VERSION ""

NS_ :

BS_:

BU_: ETH

BO_ 861 IBST_alertMatrix: 8 Vector__XXX
 SG_ IBST_matrixIndex M : 0|4@1+ (1,0) [0|0] "" Vector__XXX
 SG_ IBST_a001_microSupplyError m0 : 4|1@1+ (1,0) [0|0] "" Vector__XXX
 SG_ IBST_a061_AswSystemTimeOut m1 : 4|1@1+ (1,0) [0|0] "" Vector__XXX
 SG_ IBST_a121_RPSVectorRangeLow m2 : 4|1@1+ (1,0) [0|0] "" Vector__XXX
 SG_ IBST_a181_DIchassisControlDLC m3 : 4|1@1+ (1,0) [0|0] "" Vector__XXX
 SG_ IBST_a002_HWBISTError m0 : 5|1@1+ (1,0) [0|0] "" Vector__XXX
 SG_ IBST_a062_MICB6TransferError m1 : 5|1@1+ (1,0) [0|0] "" Vector__XXX
 SG_ IBST_a122_RPSVectorOscillating m2 : 5|1@1+ (1,0) [0|0] "" Vector__XXX
 SG_ IBST_a182_DIchassisControlTimeout m3 : 5|1@1+ (1,0) [0|0] "" Vector__XXX
 SG_ IBST_a003_RAMFault m0 : 6|1@1+ (1,0) [0|0] "" Vector__XXX
 SG_ IBST_a063_tempSens2ShortToSupply m1 : 6|1@1+ (1,0) [0|0] "" Vector__XXX
 SG_ IBST_a123_bridgeDriverUnavail m2 : 6|1@1+ (1,0) [0|0] "" Vector__XXX
 SG_ IBST_a183_DIchassisControlChecksum m3 : 6|1@1+ (1,0) [0|0] "" Vector__XXX
 SG_ IBST_a004_flashFault m0 : 7|1@1+ (1,0) [0|0] "" Vector__XXX
 SG_ IBST_a064_tempSens1ShortToGround m1 : 7|1@1+ (1,0) [0|0] "" Vector__XXX
 SG_ IBST_a124_OBDCurrent1OORHigh m2 : 7|1@1+ (1,0) [0|0] "" Vector__XXX
 SG_ IBST_a184_DIchassisControlCounter m3 : 7|1@1+ (1,0) [0|0] "" Vector__XXX
 SG_ IBST_a005_microSafetyFault m0 : 8|1@1+ (1,0) [0|0] "" Vector__XXX
 SG_ IBST_a065_tempSens2ShortToGround m1 : 8|1@1+ (1,0) [0|0] "" Vector__XXX
 SG_ IBST_a125_OBDCurrent2OORHigh m2 : 8|1@1+ (1,0) [0|0] "" Vector__XXX
 SG_ IBST_a185_rightBusOff m3 : 8|1@1+ (1,0) [0|0] "" Vector__XXX
 SG_ IBST_a006_microSafetyLogicFault m0 : 9|1@1+ (1,0) [0|0] "" Vector__XXX
 SG_ IBST_a066_tempSens1ShortToSupply m1 : 9|1@1+ (1,0) [0|0] "" Vector__XXX
 SG_ IBST_a126_OBDCurrent1OORLow m2 : 9|1@1+ (1,0) [0|0] "" Vector__XXX
 SG_ IBST_a186_rightBusPassive m3 : 9|1@1+ (1,0) [0|0] "" Vector__XXX
 SG_ IBST_a007_RBCPUException m0 : 10|1@1+ (1,0) [0|0] "" Vector__XXX
 SG_ IBST_a067_tempSensImplausVoltage m1 : 10|1@1+ (1,0) [0|0] "" Vector__XXX
 SG_ IBST_a127_OBDCurrent2OORLow m2 : 10|1@1+ (1,0) [0|0] "" Vector__XXX
 SG_ IBST_a187_brakeBusOff m3 : 10|1@1+ (1,0) [0|0] "" Vector__XXX
 SG_ IBST_a008_stackOverUnderFlow m0 : 11|1@1+ (1,0) [0|0] "" Vector__XXX
 SG_ IBST_a068_chargePumpUndervoltage m1 : 11|1@1+ (1,0) [0|0] "" Vector__XXX
 SG_ IBST_a128_BLMMuxerTimeoutError m2 : 11|1@1+ (1,0) [0|0] "" Vector__XXX
 SG_ IBST_a188_brakeBusPassive m3 : 11|1@1+ (1,0) [0|0] "" Vector__XXX
 SG_ IBST_a009_systemErrorHook m0 : 12|1@1+ (1,0) [0|0] "" Vector__XXX
 SG_ IBST_a069_greasingRoutineFault m1 : 12|1@1+ (1,0) [0|0] "" Vector__XXX
 SG_ IBST_a129_loadDumpOnFSLTest m2 : 12|1@1+ (1,0) [0|0] "" Vector__XXX
 SG_ IBST_a189_rightVCLVPowerStateTimeout m3 : 12|1@1+ (1,0) [0|0] "" Vector__XXX
 SG_ IBST_a010_OSErrorHook m0 : 13|1@1+ (1,0) [0|0] "" Vector__XXX
 SG_ IBST_a070_notShutDownNvMWrite m1 : 13|1@1+ (1,0) [0|0] "" Vector__XXX
 SG_ IBST_a130_DTSFunctionalRangeLow m2 : 13|1@1+ (1,0) [0|0] "" Vector__XXX
 SG_ IBST_a190_rightVCLVPowerStateDLC m3 : 13|1@1+ (1,0) [0|0] "" Vector__XXX
 SG_ IBST_a011_systemTaskOverRun m0 : 14|1@1+ (1,0) [0|0] "" Vector__XXX
 SG_ IBST_a071_notShutDownNvMRead m1 : 14|1@1+ (1,0) [0|0] "" Vector__XXX
 SG_ IBST_a131_DTSFunctionalRangeHigh m2 : 14|1@1+ (1,0) [0|0] "" Vector__XXX
 SG_ IBST_a191_rightVCLVPowerStateChecksum m3 : 14|1@1+ (1,0) [0|0] "" Vector__XXX
 SG_ IBST_a012_OSTaskSchemeError m0 : 15|1@1+ (1,0) [0|0] "" Vector__XXX
 SG_ IBST_a072_notShutDownRight m1 : 15|1@1+ (1,0) [0|0] "" Vector__XXX
 SG_ IBST_a132_DTSPlausiCheck1vs2 m2 : 15|1@1+ (1,0) [0|0] "" Vector__XXX
 SG_ IBST_a192_rightVCLVPowerStateCounter m3 : 15|1@1+ (1,0) [0|0] "" Vector__XXX
 SG_ IBST_a013_systemTaskJitter m0 : 16|1@1+ (1,0) [0|0] "" Vector__XXX
 SG_ IBST_a073_jumpInAdjustNvMRead m1 : 16|1@1+ (1,0) [0|0] "" Vector__XXX
 SG_ IBST_a133_DTSOffsetTooLow m2 : 16|1@1+ (1,0) [0|0] "" Vector__XXX
 SG_ IBST_a193_leftVCLVPowerStateTimeout m3 : 16|1@1+ (1,0) [0|0] "" Vector__XXX
 SG_ IBST_a014_DMATransferError m0 : 17|1@1+ (1,0) [0|0] "" Vector__XXX
 SG_ IBST_a074_FindIdleDataNvMWrite m1 : 17|1@1+ (1,0) [0|0] "" Vector__XXX
 SG_ IBST_a134_DTSOffsetTooHigh m2 : 17|1@1+ (1,0) [0|0] "" Vector__XXX
 SG_ IBST_a194_leftVCLVPowerStateChecksum m3 : 17|1@1+ (1,0) [0|0] "" Vector__XXX
 SG_ IBST_a015_asicOscillatorError m0 : 18|1@1+ (1,0) [0|0] "" Vector__XXX
 SG_ IBST_a075_FindIdleRoutineFault m1 : 18|1@1+ (1,0) [0|0] "" Vector__XXX
 SG_ IBST_a135_ESPparty1DLC m2 : 18|1@1+ (1,0) [0|0] "" Vector__XXX
 SG_ IBST_a195_leftVCLVPowerStateDLC m3 : 18|1@1+ (1,0) [0|0] "" Vector__XXX
 SG_ IBST_a016_RBBLMShaftShiftError m0 : 19|1@1+ (1,0) [0|0] "" Vector__XXX
 SG_ IBST_a076_masterCylLengthRead m1 : 19|1@1+ (1,0) [0|0] "" Vector__XXX
 SG_ IBST_a136_ESPparty1Timeout m2 : 19|1@1+ (1,0) [0|0] "" Vector__XXX
 SG_ IBST_a196_leftVCLVPowerStateCounter m3 : 19|1@1+ (1,0) [0|0] "" Vector__XXX
 SG_ IBST_a017_assertionFault m0 : 20|1@1+ (1,0) [0|0] "" Vector__XXX
 SG_ IBST_a077_runOutMotorSaturated m1 : 20|1@1+ (1,0) [0|0] "" Vector__XXX
 SG_ IBST_a137_ESPparty1Checksum m2 : 20|1@1+ (1,0) [0|0] "" Vector__XXX
 SG_ IBST_a197_brakeLatencyReductionActive m3 : 20|1@1+ (1,0) [0|0] "" Vector__XXX
 SG_ IBST_a018_unsupportedHW m0 : 21|1@1+ (1,0) [0|0] "" Vector__XXX
 SG_ IBST_a078_wearOffsetCompNVMRead m1 : 21|1@1+ (1,0) [0|0] "" Vector__XXX
 SG_ IBST_a138_ESPparty1Counter m2 : 21|1@1+ (1,0) [0|0] "" Vector__XXX
 SG_ IBST_a198_aesActive m3 : 21|1@1+ (1,0) [0|0] "" Vector__XXX
 SG_ IBST_a019_supplyASICInitFault m0 : 22|1@1+ (1,0) [0|0] "" Vector__XXX
 SG_ IBST_a079_motorTempHighLevel1 m1 : 22|1@1+ (1,0) [0|0] "" Vector__XXX
 SG_ IBST_a139_ESPparty2DLC m2 : 22|1@1+ (1,0) [0|0] "" Vector__XXX
 SG_ IBST_a199_undefinedAlertDetected m3 : 22|1@1+ (1,0) [0|0] "" Vector__XXX
 SG_ IBST_a020_VPREU5VOutOfRange m0 : 23|1@1+ (1,0) [0|0] "" Vector__XXX
 SG_ IBST_a080_motorTempHighLevel2 m1 : 23|1@1+ (1,0) [0|0] "" Vector__XXX
 SG_ IBST_a140_ESPparty2Timeout m2 : 23|1@1+ (1,0) [0|0] "" Vector__XXX
 SG_ IBST_a200_aesFault m3 : 23|1@1+ (1,0) [0|0] "" Vector__XXX
 SG_ IBST_a021_IREFOutOfRange m0 : 24|1@1+ (1,0) [0|0] "" Vector__XXX
 SG_ IBST_a081_travelDeviation m1 : 24|1@1+ (1,0) [0|0] "" Vector__XXX
 SG_ IBST_a141_ESPparty2Checksum m2 : 24|1@1+ (1,0) [0|0] "" Vector__XXX
 SG_ IBST_a201_EGGREAR1wheelSpeedsRearTimeOut m3 : 24|1@1+ (1,0) [0|0] "" Vector__XXX
 SG_ IBST_a022_U5VTestFault m0 : 25|1@1+ (1,0) [0|0] "" Vector__XXX
 SG_ IBST_a082_motorSpeedDeviation m1 : 25|1@1+ (1,0) [0|0] "" Vector__XXX
 SG_ IBST_a142_ESPparty2Counter m2 : 25|1@1+ (1,0) [0|0] "" Vector__XXX
 SG_ IBST_a202_EGGREAR1wheelSpeedsRearChecksum m3 : 25|1@1+ (1,0) [0|0] "" Vector__XXX
 SG_ IBST_a023_U5VOutOfRange m0 : 26|1@1+ (1,0) [0|0] "" Vector__XXX
 SG_ IBST_a083_spindlePositionTooHigh m1 : 26|1@1+ (1,0) [0|0] "" Vector__XXX
 SG_ IBST_a143_ESPparty3DLC m2 : 26|1@1+ (1,0) [0|0] "" Vector__XXX
 SG_ IBST_a203_EGGREAR1wheelSpeedsRearDLC m3 : 26|1@1+ (1,0) [0|0] "" Vector__XXX
 SG_ IBST_a024_chargePumpFault m0 : 27|1@1+ (1,0) [0|0] "" Vector__XXX
 SG_ IBST_a084_CANTransceiverHWFault m1 : 27|1@1+ (1,0) [0|0] "" Vector__XXX
 SG_ IBST_a144_ESPparty3Timeout m2 : 27|1@1+ (1,0) [0|0] "" Vector__XXX
 SG_ IBST_a204_EGGREAR1wheelSpeedsRearCounter m3 : 27|1@1+ (1,0) [0|0] "" Vector__XXX
 SG_ IBST_a025_ecuClockTestFault m0 : 28|1@1+ (1,0) [0|0] "" Vector__XXX
 SG_ IBST_a085_supplyUndervoltageLvl3 m1 : 28|1@1+ (1,0) [0|0] "" Vector__XXX
 SG_ IBST_a145_ESPparty3Checksum m2 : 28|1@1+ (1,0) [0|0] "" Vector__XXX
 SG_ IBST_a205_EGGRIGHT1wheelSpeedsFrontTimeOut m3 : 28|1@1+ (1,0) [0|0] "" Vector__XXX
 SG_ IBST_a026_ecuBistCmdTestFault m0 : 29|1@1+ (1,0) [0|0] "" Vector__XXX
 SG_ IBST_a086_supplyOvervoltageLvl3 m1 : 29|1@1+ (1,0) [0|0] "" Vector__XXX
 SG_ IBST_a146_ESPparty3Counter m2 : 29|1@1+ (1,0) [0|0] "" Vector__XXX
 SG_ IBST_a206_EGGRIGHT1wheelSpeedsFrontChecksum m3 : 29|1@1+ (1,0) [0|0] "" Vector__XXX
 SG_ IBST_a027_ecuFastWdTestFault m0 : 30|1@1+ (1,0) [0|0] "" Vector__XXX
 SG_ IBST_a087_rotorSinOutOfRangeLow m1 : 30|1@1+ (1,0) [0|0] "" Vector__XXX
 SG_ IBST_a147_PSCMotorSizeReadFault m2 : 30|1@1+ (1,0) [0|0] "" Vector__XXX
 SG_ IBST_a207_EGGRIGHT1wheelSpeedsFrontDLC m3 : 30|1@1+ (1,0) [0|0] "" Vector__XXX
 SG_ IBST_a028_ecuBistFaultCtrFault m0 : 31|1@1+ (1,0) [0|0] "" Vector__XXX
 SG_ IBST_a088_rotorCosOutOfRangeLow m1 : 31|1@1+ (1,0) [0|0] "" Vector__XXX
 SG_ IBST_a148_MLIGainMechReadFault m2 : 31|1@1+ (1,0) [0|0] "" Vector__XXX
 SG_ IBST_a208_EGGRIGHT1wheelSpeedsFrontCounter m3 : 31|1@1+ (1,0) [0|0] "" Vector__XXX
 SG_ IBST_a029_ecuErrpinCounterFault m0 : 32|1@1+ (1,0) [0|0] "" Vector__XXX
 SG_ IBST_a089_rotorSinOutOfRangeHigh m1 : 32|1@1+ (1,0) [0|0] "" Vector__XXX
 SG_ IBST_a149_MLITMCAreaReadFault m2 : 32|1@1+ (1,0) [0|0] "" Vector__XXX
 SG_ IBST_a209_reducedBrakePowerActive m3 : 32|1@1+ (1,0) [0|0] "" Vector__XXX
 SG_ IBST_a030_ecuEnableElLowFault m0 : 33|1@1+ (1,0) [0|0] "" Vector__XXX
 SG_ IBST_a090_rotorCosOutOfRangeHigh m1 : 33|1@1+ (1,0) [0|0] "" Vector__XXX
 SG_ IBST_a150_motorTestFault m2 : 33|1@1+ (1,0) [0|0] "" Vector__XXX
 SG_ IBST_a210_reducedBrakePowerNotAvailable m3 : 33|1@1+ (1,0) [0|0] "" Vector__XXX
 SG_ IBST_a031_decoupleBitTestFault m0 : 34|1@1+ (1,0) [0|0] "" Vector__XXX
 SG_ IBST_a091_SMMOneRequestsInit m1 : 34|1@1+ (1,0) [0|0] "" Vector__XXX
 SG_ IBST_a151_PSCGearRatioReadFault m2 : 34|1@1+ (1,0) [0|0] "" Vector__XXX
 SG_ IBST_a211_DETReportError m3 : 34|1@1+ (1,0) [0|0] "" Vector__XXX
 SG_ IBST_a032_ecuEnableElHighFault m0 : 35|1@1+ (1,0) [0|0] "" Vector__XXX
 SG_ IBST_a092_systemStartTimeOut m1 : 35|1@1+ (1,0) [0|0] "" Vector__XXX
 SG_ IBST_a152_PSCVoltageImplausible m2 : 35|1@1+ (1,0) [0|0] "" Vector__XXX
 SG_ IBST_a212_infoFailureWrongCUBASHandlingDetected m3 : 35|1@1+ (1,0) [0|0] "" Vector__XXX
 SG_ IBST_a033_ecuWdStartuptestFault m0 : 36|1@1+ (1,0) [0|0] "" Vector__XXX
 SG_ IBST_a093_UEXSOvertemperature m1 : 36|1@1+ (1,0) [0|0] "" Vector__XXX
 SG_ IBST_a153_unused m2 : 36|1@1+ (1,0) [0|0] "" Vector__XXX
 SG_ IBST_a213_PDURouterinitializationFailed m3 : 36|1@1+ (1,0) [0|0] "" Vector__XXX
 SG_ IBST_a034_ecuEnableHyHighFault m0 : 37|1@1+ (1,0) [0|0] "" Vector__XXX
 SG_ IBST_a094_XPASSEchoTimeDeviation m1 : 37|1@1+ (1,0) [0|0] "" Vector__XXX
 SG_ IBST_a154_unused m2 : 37|1@1+ (1,0) [0|0] "" Vector__XXX
 SG_ IBST_a214_LossOfPDUInstanceDetected m3 : 37|1@1+ (1,0) [0|0] "" Vector__XXX
 SG_ IBST_a035_ecuEnableHyLowFault m0 : 38|1@1+ (1,0) [0|0] "" Vector__XXX
 SG_ IBST_a095_XPASSTimeOut m1 : 38|1@1+ (1,0) [0|0] "" Vector__XXX
 SG_ IBST_a155_supplyUndervoltageLvl1 m2 : 38|1@1+ (1,0) [0|0] "" Vector__XXX
 SG_ IBST_a215_UnsupportedSeriesHWDetected m3 : 38|1@1+ (1,0) [0|0] "" Vector__XXX
 SG_ IBST_a036_MRGPathTestFault m0 : 39|1@1+ (1,0) [0|0] "" Vector__XXX
 SG_ IBST_a096_bridgeDriverMonError m1 : 39|1@1+ (1,0) [0|0] "" Vector__XXX
 SG_ IBST_a156_supplyOvervoltageLvl1 m2 : 39|1@1+ (1,0) [0|0] "" Vector__XXX
 SG_ IBST_a216_AsicMalfunctionDetected m3 : 39|1@1+ (1,0) [0|0] "" Vector__XXX
 SG_ IBST_a037_ecuWdSContinuousError m0 : 40|1@1+ (1,0) [0|0] "" Vector__XXX
 SG_ IBST_a097_bridgeDriverError m1 : 40|1@1+ (1,0) [0|0] "" Vector__XXX
 SG_ IBST_a157_masterCylPressInvalid m2 : 40|1@1+ (1,0) [0|0] "" Vector__XXX
 SG_ IBST_a217_AsicTrimmingNotCompleted m3 : 40|1@1+ (1,0) [0|0] "" Vector__XXX
 SG_ IBST_a038_ecuEnContinuousError m0 : 41|1@1+ (1,0) [0|0] "" Vector__XXX
 SG_ IBST_a098_bridgeShortedPhase m1 : 41|1@1+ (1,0) [0|0] "" Vector__XXX
 SG_ IBST_a158_DTSOffsHighSuspicious m2 : 41|1@1+ (1,0) [0|0] "" Vector__XXX
 SG_ IBST_a218_uCSafetyNotificationGRAM m3 : 41|1@1+ (1,0) [0|0] "" Vector__XXX
 SG_ IBST_a039_GTMRefFrequencyError m0 : 42|1@1+ (1,0) [0|0] "" Vector__XXX
 SG_ IBST_a099_bridgeSwitchInitError m1 : 42|1@1+ (1,0) [0|0] "" Vector__XXX
 SG_ IBST_a159_FindIdleNvMReadError m2 : 42|1@1+ (1,0) [0|0] "" Vector__XXX
 SG_ IBST_a219_uCSafetyNotification m3 : 42|1@1+ (1,0) [0|0] "" Vector__XXX
 SG_ IBST_a040_GTMTbuMonError m0 : 43|1@1+ (1,0) [0|0] "" Vector__XXX
 SG_ IBST_a100_current2OffsetHigh m1 : 43|1@1+ (1,0) [0|0] "" Vector__XXX
 SG_ IBST_a160_DTSIDTimeOut m2 : 43|1@1+ (1,0) [0|0] "" Vector__XXX
 SG_ IBST_a220_ASICOvercurrentOnGPIO250_2 m3 : 43|1@1+ (1,0) [0|0] "" Vector__XXX
 SG_ IBST_a041_micAsicClkInError m0 : 44|1@1+ (1,0) [0|0] "" Vector__XXX
 SG_ IBST_a101_current2OffsetLow m1 : 44|1@1+ (1,0) [0|0] "" Vector__XXX
 SG_ IBST_a161_powerPackMismatch m2 : 44|1@1+ (1,0) [0|0] "" Vector__XXX
 SG_ IBST_a221_ASICOvercurrentOnGPIO250_1 m3 : 44|1@1+ (1,0) [0|0] "" Vector__XXX
 SG_ IBST_a042_micAsicInitTestError m0 : 45|1@1+ (1,0) [0|0] "" Vector__XXX
 SG_ IBST_a102_current1OffsetHigh m1 : 45|1@1+ (1,0) [0|0] "" Vector__XXX
 SG_ IBST_a162_idlePosNotDetected m2 : 45|1@1+ (1,0) [0|0] "" Vector__XXX
 SG_ IBST_a222_ASICOvercurrentOnGPIO50_4 m3 : 45|1@1+ (1,0) [0|0] "" Vector__XXX
 SG_ IBST_a043_micSpiTransferError m0 : 46|1@1+ (1,0) [0|0] "" Vector__XXX
 SG_ IBST_a103_current1OffsetLow m1 : 46|1@1+ (1,0) [0|0] "" Vector__XXX
 SG_ IBST_a163_ESPpEstMaxInvalid m2 : 46|1@1+ (1,0) [0|0] "" Vector__XXX
 SG_ IBST_a223_ASICOvercurrentOnGPIO50_3 m3 : 46|1@1+ (1,0) [0|0] "" Vector__XXX
 SG_ IBST_a044_NvMEepromWIP m0 : 47|1@1+ (1,0) [0|0] "" Vector__XXX
 SG_ IBST_a104_bridgeDriverShort m1 : 47|1@1+ (1,0) [0|0] "" Vector__XXX
 SG_ IBST_a164_ESPVehicleSpeedInvalid m2 : 47|1@1+ (1,0) [0|0] "" Vector__XXX
 SG_ IBST_a224_ASICOvercurrentOnGPIO50_2 m3 : 47|1@1+ (1,0) [0|0] "" Vector__XXX
 SG_ IBST_a045_WdhAsicWdErrorCntStuck m0 : 48|1@1+ (1,0) [0|0] "" Vector__XXX
 SG_ IBST_a105_LiPSUndervoltage m1 : 48|1@1+ (1,0) [0|0] "" Vector__XXX
 SG_ IBST_a165_ESPpForceBlendInvalid m2 : 48|1@1+ (1,0) [0|0] "" Vector__XXX
 SG_ IBST_a225_ASICOvercurrentOnGPIO50_1 m3 : 48|1@1+ (1,0) [0|0] "" Vector__XXX
 SG_ IBST_a046_WdhAsicWdErrorCntLimit m0 : 49|1@1+ (1,0) [0|0] "" Vector__XXX
 SG_ IBST_a106_LiPS5VSupply m1 : 49|1@1+ (1,0) [0|0] "" Vector__XXX
 SG_ IBST_a166_ESPpMcVirtualInvalid m2 : 49|1@1+ (1,0) [0|0] "" Vector__XXX
 SG_ IBST_a226_ASICOvercurrentOnWRHS m3 : 49|1@1+ (1,0) [0|0] "" Vector__XXX
 SG_ IBST_a047_WdhAsicWdCmdMissing m0 : 50|1@1+ (1,0) [0|0] "" Vector__XXX
 SG_ IBST_a107_LiPS2PwmLineHigh m1 : 50|1@1+ (1,0) [0|0] "" Vector__XXX
 SG_ IBST_a167_ESPqTargetExterInvalid m2 : 50|1@1+ (1,0) [0|0] "" Vector__XXX
 SG_ IBST_a227_wakeRequestMismatchDetected m3 : 50|1@1+ (1,0) [0|0] "" Vector__XXX
 SG_ IBST_a048_WdhSwBistConCnt m0 : 51|1@1+ (1,0) [0|0] "" Vector__XXX
 SG_ IBST_a108_LiPS2PwmLineLow m1 : 51|1@1+ (1,0) [0|0] "" Vector__XXX
 SG_ IBST_a168_CANOvervoltage m2 : 51|1@1+ (1,0) [0|0] "" Vector__XXX
 SG_ IBST_a228_BlockedPedalDetectedDuringHAD m3 : 51|1@1+ (1,0) [0|0] "" Vector__XXX
 SG_ IBST_a049_WdhTaskMonConCnt m0 : 52|1@1+ (1,0) [0|0] "" Vector__XXX
 SG_ IBST_a109_LiPS2PwmTransmission m1 : 52|1@1+ (1,0) [0|0] "" Vector__XXX
 SG_ IBST_a169_CANUndervoltage m2 : 52|1@1+ (1,0) [0|0] "" Vector__XXX
 SG_ IBST_a229_BlockedPedalDetected m3 : 52|1@1+ (1,0) [0|0] "" Vector__XXX
 SG_ IBST_a050_VPreExternalFeeding m0 : 53|1@1+ (1,0) [0|0] "" Vector__XXX
 SG_ IBST_a110_LiPS1SentLineHigh m1 : 53|1@1+ (1,0) [0|0] "" Vector__XXX
 SG_ IBST_a170_LVPowerStateTimeout m2 : 53|1@1+ (1,0) [0|0] "" Vector__XXX
 SG_ IBST_a230_DTS2FunctionalRangeLow m3 : 53|1@1+ (1,0) [0|0] "" Vector__XXX
 SG_ IBST_a051_ecuBandgap m0 : 54|1@1+ (1,0) [0|0] "" Vector__XXX
 SG_ IBST_a111_LiPS1SentLineLow m1 : 54|1@1+ (1,0) [0|0] "" Vector__XXX
 SG_ IBST_a171_LVPowerStateChecksum m2 : 54|1@1+ (1,0) [0|0] "" Vector__XXX
 SG_ IBST_a231_DTS2FunctionalRangeLow m3 : 54|1@1+ (1,0) [0|0] "" Vector__XXX
 SG_ IBST_a052_AdcPinTest m0 : 55|1@1+ (1,0) [0|0] "" Vector__XXX
 SG_ IBST_a112_LiPS1SentTransmission m1 : 55|1@1+ (1,0) [0|0] "" Vector__XXX
 SG_ IBST_a172_LVPowerStateDLC m2 : 55|1@1+ (1,0) [0|0] "" Vector__XXX
 SG_ IBST_a232_PostAssemblyRoutineFailed m3 : 55|1@1+ (1,0) [0|0] "" Vector__XXX
 SG_ IBST_a053_AdcSelftestC5P m0 : 56|1@1+ (1,0) [0|0] "" Vector__XXX
 SG_ IBST_a113_LiPS1SentSensor m1 : 56|1@1+ (1,0) [0|0] "" Vector__XXX
 SG_ IBST_a173_LVPowerStateCounter m2 : 56|1@1+ (1,0) [0|0] "" Vector__XXX
 SG_ IBST_a233_ReferenceRunAbortByECUReset m3 : 56|1@1+ (1,0) [0|0] "" Vector__XXX
 SG_ IBST_a054_AdcPeripheralFault m0 : 57|1@1+ (1,0) [0|0] "" Vector__XXX
 SG_ IBST_a114_partyBusOff m1 : 57|1@1+ (1,0) [0|0] "" Vector__XXX
 SG_ IBST_a174_LVOffStateInvalid m2 : 57|1@1+ (1,0) [0|0] "" Vector__XXX
 SG_ IBST_a234_LiPSOutOfRangeHigh m3 : 57|1@1+ (1,0) [0|0] "" Vector__XXX
 SG_ IBST_a055_UB6SupplyPathFault m0 : 58|1@1+ (1,0) [0|0] "" Vector__XXX
 SG_ IBST_a115_chassisBusOff m1 : 58|1@1+ (1,0) [0|0] "" Vector__XXX
 SG_ IBST_a175_LVGoingDownInvalid m2 : 58|1@1+ (1,0) [0|0] "" Vector__XXX
 SG_ IBST_a235_LiPSOutOfRangeLow m3 : 58|1@1+ (1,0) [0|0] "" Vector__XXX
 SG_ IBST_a056_UB6PlausiMonFault m0 : 59|1@1+ (1,0) [0|0] "" Vector__XXX
 SG_ IBST_a116_supplyUndervoltageLvl2 m1 : 59|1@1+ (1,0) [0|0] "" Vector__XXX
 SG_ IBST_a176_blockedPedalDetected m2 : 59|1@1+ (1,0) [0|0] "" Vector__XXX
 SG_ IBST_a057_microRegisterFault m0 : 60|1@1+ (1,0) [0|0] "" Vector__XXX
 SG_ IBST_a117_supplyOvervoltageLvl2 m1 : 60|1@1+ (1,0) [0|0] "" Vector__XXX
 SG_ IBST_a177_EPBLsystemStatusMIA m2 : 60|1@1+ (1,0) [0|0] "" Vector__XXX
 SG_ IBST_a058_NvMWriteCycleExceed m0 : 61|1@1+ (1,0) [0|0] "" Vector__XXX
 SG_ IBST_a118_RPSNvMReadFault m1 : 61|1@1+ (1,0) [0|0] "" Vector__XXX
 SG_ IBST_a178_EPBRsystemStatusMIA m2 : 61|1@1+ (1,0) [0|0] "" Vector__XXX
 SG_ IBST_a059_NvMEepromSize m0 : 62|1@1+ (1,0) [0|0] "" Vector__XXX
 SG_ IBST_a119_RPSWrongCalibData m1 : 62|1@1+ (1,0) [0|0] "" Vector__XXX
 SG_ IBST_a179_VCLEFTepbmStatusMIA m2 : 62|1@1+ (1,0) [0|0] "" Vector__XXX
 SG_ IBST_a060_NvMMigrationFault m0 : 63|1@1+ (1,0) [0|0] "" Vector__XXX
 SG_ IBST_a120_RPSVectorRangeHigh m1 : 63|1@1+ (1,0) [0|0] "" Vector__XXX
 SG_ IBST_a180_VCRIGHTepbmStatusMIA m2 : 63|1@1+ (1,0) [0|0] "" Vector__XXX

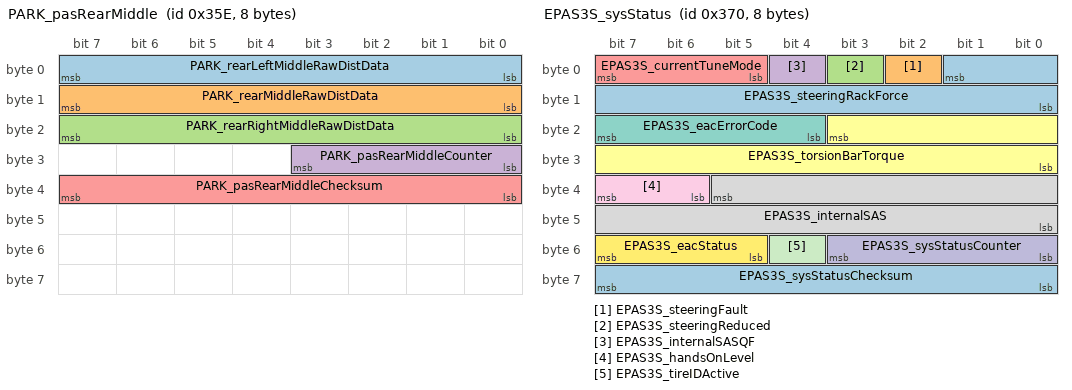
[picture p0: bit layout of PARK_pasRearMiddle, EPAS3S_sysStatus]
BO_ 862 PARK_pasRearMiddle: 8 Vector__XXX
 SG_ PARK_rearLeftMiddleRawDistData : 0|8@1+ (1,0) [0|0] "" Vector__XXX
 SG_ PARK_rearMiddleRawDistData : 8|8@1+ (1,0) [0|0] "" Vector__XXX
 SG_ PARK_rearRightMiddleRawDistData : 16|8@1+ (1,0) [0|0] "" Vector__XXX
 SG_ PARK_pasRearMiddleCounter : 24|4@1+ (1,0) [0|0] "" Vector__XXX
 SG_ PARK_pasRearMiddleChecksum : 32|8@1+ (1,0) [0|0] "" Vector__XXX

BO_ 873 APP_warningMatrix1: 8 Vector__XXX
 SG_ APP_w065_deserializerOvercurrent : 0|1@1+ (1,0) [0|0] "" Vector__XXX
 SG_ APP_w066_deserializerLockLost : 1|1@1+ (1,0) [0|0] "" Vector__XXX
 SG_ APP_w067_steeringAlignment : 2|1@1+ (1,0) [0|0] "" Vector__XXX
 SG_ APP_w068_vlInconsistency : 3|1@1+ (1,0) [0|0] "" Vector__XXX
 SG_ APP_w069_apcSpaceMasked : 4|1@1+ (1,0) [0|0] "" Vector__XXX
 SG_ APP_w070_apcIncompleteCal : 5|1@1+ (1,0) [0|0] "" Vector__XXX
 SG_ APP_w071_selfparkStarted : 6|1@1+ (1,0) [0|0] "" Vector__XXX
 SG_ APP_w072_selfparkComplete : 7|1@1+ (1,0) [0|0] "" Vector__XXX
 SG_ APP_w073_issueEscalatedLDW : 8|1@1+ (1,0) [0|0] "" Vector__XXX
 SG_ APP_w074_inPathStationaryObst : 9|1@1+ (1,0) [0|0] "" Vector__XXX
 SG_ APP_w075_scMia : 10|1@1+ (1,0) [0|0] "" Vector__XXX
 SG_ APP_w076_mobilEyeSetC : 11|1@1+ (1,0) [0|0] "" Vector__XXX
 SG_ APP_w077_pmmActive : 12|1@1+ (1,0) [0|0] "" Vector__XXX
 SG_ APP_w078_pmmActive2 : 13|1@1+ (1,0) [0|0] "" Vector__XXX
 SG_ APP_w079_edrAvailable : 14|1@1+ (1,0) [0|0] "" Vector__XXX
 SG_ APP_w080_accFailedActivation : 15|1@1+ (1,0) [0|0] "" Vector__XXX
 SG_ APP_w081_pmmActiveBraking : 16|1@1+ (1,0) [0|0] "" Vector__XXX
 SG_ APP_w082_inPathFSviolation : 17|1@1+ (1,0) [0|0] "" Vector__XXX
 SG_ APP_w083_inPathRADObject : 18|1@1+ (1,0) [0|0] "" Vector__XXX
 SG_ APP_w084_pmmIPSO : 19|1@1+ (1,0) [0|0] "" Vector__XXX
 SG_ APP_w085_pmmSteering : 20|1@1+ (1,0) [0|0] "" Vector__XXX
 SG_ APP_w086_robCollision : 21|1@1+ (1,0) [0|0] "" Vector__XXX
 SG_ APP_w087_DEPRECATED : 22|1@1+ (1,0) [0|0] "" Vector__XXX
 SG_ APP_w088_DEPRECATED : 23|1@1+ (1,0) [0|0] "" Vector__XXX
 SG_ APP_w089_DEPRECATED : 24|1@1+ (1,0) [0|0] "" Vector__XXX
 SG_ APP_w090_DEPRECATED : 25|1@1+ (1,0) [0|0] "" Vector__XXX
 SG_ APP_w091_DEPRECATED : 26|1@1+ (1,0) [0|0] "" Vector__XXX
 SG_ APP_w092_DEPRECATED : 27|1@1+ (1,0) [0|0] "" Vector__XXX
 SG_ APP_w093_DEPRECATED : 28|1@1+ (1,0) [0|0] "" Vector__XXX
 SG_ APP_w094_DEPRECATED : 29|1@1+ (1,0) [0|0] "" Vector__XXX
 SG_ APP_w095_DEPRECATED : 30|1@1+ (1,0) [0|0] "" Vector__XXX
 SG_ APP_w096_DEPRECATED : 31|1@1+ (1,0) [0|0] "" Vector__XXX
 SG_ APP_w097_DEPRECATED : 32|1@1+ (1,0) [0|0] "" Vector__XXX
 SG_ APP_w098_DEPRECATED : 33|1@1+ (1,0) [0|0] "" Vector__XXX
 SG_ APP_w099_DEPRECATED : 34|1@1+ (1,0) [0|0] "" Vector__XXX
 SG_ APP_w100_DEPRECATED : 35|1@1+ (1,0) [0|0] "" Vector__XXX
 SG_ APP_w101_DEPRECATED : 36|1@1+ (1,0) [0|0] "" Vector__XXX
 SG_ APP_w102_DEPRECATED : 37|1@1+ (1,0) [0|0] "" Vector__XXX
 SG_ APP_w103_robExperimentalAEB : 38|1@1+ (1,0) [0|0] "" Vector__XXX
 SG_ APP_w104_DEPRECATED : 39|1@1+ (1,0) [0|0] "" Vector__XXX
 SG_ APP_w105_DEPRECATED : 40|1@1+ (1,0) [0|0] "" Vector__XXX
 SG_ APP_w106_torsionBarOffset : 41|1@1+ (1,0) [0|0] "" Vector__XXX

BO_ 874 DAS_warningMatrix1: 8 Vector__XXX
 SG_ DAS_w065_deserializerOvercurrent : 0|1@1+ (1,0) [0|0] "" Vector__XXX
 SG_ DAS_w066_deserializerLockLost : 1|1@1+ (1,0) [0|0] "" Vector__XXX
 SG_ DAS_w067_steeringAlignment : 2|1@1+ (1,0) [0|0] "" Vector__XXX
 SG_ DAS_w068_vlInconsistency : 3|1@1+ (1,0) [0|0] "" Vector__XXX
 SG_ DAS_w069_apcSpaceMasked : 4|1@1+ (1,0) [0|0] "" Vector__XXX
 SG_ DAS_w070_apcIncompleteCal : 5|1@1+ (1,0) [0|0] "" Vector__XXX
 SG_ DAS_w071_selfparkStarted : 6|1@1+ (1,0) [0|0] "" Vector__XXX
 SG_ DAS_w072_selfparkComplete : 7|1@1+ (1,0) [0|0] "" Vector__XXX
 SG_ DAS_w073_issueEscalatedLDW : 8|1@1+ (1,0) [0|0] "" Vector__XXX
 SG_ DAS_w074_inPathStationaryObst : 9|1@1+ (1,0) [0|0] "" Vector__XXX
 SG_ DAS_w075_scMia : 10|1@1+ (1,0) [0|0] "" Vector__XXX
 SG_ DAS_w076_mobilEyeSetC : 11|1@1+ (1,0) [0|0] "" Vector__XXX
 SG_ DAS_w077_pmmActive : 12|1@1+ (1,0) [0|0] "" Vector__XXX
 SG_ DAS_w078_pmmActive2 : 13|1@1+ (1,0) [0|0] "" Vector__XXX
 SG_ DAS_w079_edrAvailable : 14|1@1+ (1,0) [0|0] "" Vector__XXX
 SG_ DAS_w080_accFailedActivation : 15|1@1+ (1,0) [0|0] "" Vector__XXX
 SG_ DAS_w081_pmmActiveBraking : 16|1@1+ (1,0) [0|0] "" Vector__XXX
 SG_ DAS_w082_inPathFSviolation : 17|1@1+ (1,0) [0|0] "" Vector__XXX
 SG_ DAS_w083_inPathRADObject : 18|1@1+ (1,0) [0|0] "" Vector__XXX
 SG_ DAS_w084_pmmIPSO : 19|1@1+ (1,0) [0|0] "" Vector__XXX
 SG_ DAS_w085_pmmSteering : 20|1@1+ (1,0) [0|0] "" Vector__XXX
 SG_ DAS_w086_robCollision : 21|1@1+ (1,0) [0|0] "" Vector__XXX
 SG_ DAS_w087_DEPRECATED : 22|1@1+ (1,0) [0|0] "" Vector__XXX
 SG_ DAS_w088_DEPRECATED : 23|1@1+ (1,0) [0|0] "" Vector__XXX
 SG_ DAS_w089_DEPRECATED : 24|1@1+ (1,0) [0|0] "" Vector__XXX
 SG_ DAS_w090_DEPRECATED : 25|1@1+ (1,0) [0|0] "" Vector__XXX
 SG_ DAS_w091_DEPRECATED : 26|1@1+ (1,0) [0|0] "" Vector__XXX
 SG_ DAS_w092_DEPRECATED : 27|1@1+ (1,0) [0|0] "" Vector__XXX
 SG_ DAS_w093_DEPRECATED : 28|1@1+ (1,0) [0|0] "" Vector__XXX
 SG_ DAS_w094_DEPRECATED : 29|1@1+ (1,0) [0|0] "" Vector__XXX
 SG_ DAS_w095_DEPRECATED : 30|1@1+ (1,0) [0|0] "" Vector__XXX
 SG_ DAS_w096_DEPRECATED : 31|1@1+ (1,0) [0|0] "" Vector__XXX
 SG_ DAS_w097_DEPRECATED : 32|1@1+ (1,0) [0|0] "" Vector__XXX
 SG_ DAS_w098_DEPRECATED : 33|1@1+ (1,0) [0|0] "" Vector__XXX
 SG_ DAS_w099_DEPRECATED : 34|1@1+ (1,0) [0|0] "" Vector__XXX
 SG_ DAS_w100_DEPRECATED : 35|1@1+ (1,0) [0|0] "" Vector__XXX
 SG_ DAS_w101_DEPRECATED : 36|1@1+ (1,0) [0|0] "" Vector__XXX
 SG_ DAS_w102_DEPRECATED : 37|1@1+ (1,0) [0|0] "" Vector__XXX
 SG_ DAS_w103_robExperimentalAEB : 38|1@1+ (1,0) [0|0] "" Vector__XXX
 SG_ DAS_w104_DEPRECATED : 39|1@1+ (1,0) [0|0] "" Vector__XXX
 SG_ DAS_w105_DEPRECATED : 40|1@1+ (1,0) [0|0] "" Vector__XXX
 SG_ DAS_w106_torsionBarCalibrated : 41|1@1+ (1,0) [0|0] "" Vector__XXX

BO_ 876 APS_warningMatrix1: 8 Vector__XXX
 SG_ APS_w065_deserializerOvercurrent : 0|1@1+ (1,0) [0|0] "" Vector__XXX
 SG_ APS_w066_deserializerLockLost : 1|1@1+ (1,0) [0|0] "" Vector__XXX
 SG_ APS_w067_steeringAlignment : 2|1@1+ (1,0) [0|0] "" Vector__XXX
 SG_ APS_w068_vlInconsistency : 3|1@1+ (1,0) [0|0] "" Vector__XXX
 SG_ APS_w069_apcSpaceMasked : 4|1@1+ (1,0) [0|0] "" Vector__XXX
 SG_ APS_w070_apcIncompleteCal : 5|1@1+ (1,0) [0|0] "" Vector__XXX
 SG_ APS_w071_selfparkStarted : 6|1@1+ (1,0) [0|0] "" Vector__XXX
 SG_ APS_w072_selfparkComplete : 7|1@1+ (1,0) [0|0] "" Vector__XXX
 SG_ APS_w073_issueEscalatedLDW : 8|1@1+ (1,0) [0|0] "" Vector__XXX
 SG_ APS_w074_inPathStationaryObst : 9|1@1+ (1,0) [0|0] "" Vector__XXX
 SG_ APS_w075_scMia : 10|1@1+ (1,0) [0|0] "" Vector__XXX
 SG_ APS_w076_mobilEyeSetC : 11|1@1+ (1,0) [0|0] "" Vector__XXX
 SG_ APS_w077_pmmActive : 12|1@1+ (1,0) [0|0] "" Vector__XXX
 SG_ APS_w078_pmmActive2 : 13|1@1+ (1,0) [0|0] "" Vector__XXX
 SG_ APS_w079_edrAvailable : 14|1@1+ (1,0) [0|0] "" Vector__XXX
 SG_ APS_w080_accFailedActivation : 15|1@1+ (1,0) [0|0] "" Vector__XXX
 SG_ APS_w081_pmmActiveBraking : 16|1@1+ (1,0) [0|0] "" Vector__XXX
 SG_ APS_w082_inPathFSviolation : 17|1@1+ (1,0) [0|0] "" Vector__XXX
 SG_ APS_w083_inPathRADObject : 18|1@1+ (1,0) [0|0] "" Vector__XXX
 SG_ APS_w084_pmmIPSO : 19|1@1+ (1,0) [0|0] "" Vector__XXX
 SG_ APS_w085_pmmSteering : 20|1@1+ (1,0) [0|0] "" Vector__XXX
 SG_ APS_w086_robCollision : 21|1@1+ (1,0) [0|0] "" Vector__XXX
 SG_ APS_w087_DEPRECATED : 22|1@1+ (1,0) [0|0] "" Vector__XXX
 SG_ APS_w088_DEPRECATED : 23|1@1+ (1,0) [0|0] "" Vector__XXX
 SG_ APS_w089_DEPRECATED : 24|1@1+ (1,0) [0|0] "" Vector__XXX
 SG_ APS_w090_DEPRECATED : 25|1@1+ (1,0) [0|0] "" Vector__XXX
 SG_ APS_w091_DEPRECATED : 26|1@1+ (1,0) [0|0] "" Vector__XXX
 SG_ APS_w092_DEPRECATED : 27|1@1+ (1,0) [0|0] "" Vector__XXX
 SG_ APS_w093_DEPRECATED : 28|1@1+ (1,0) [0|0] "" Vector__XXX
 SG_ APS_w094_DEPRECATED : 29|1@1+ (1,0) [0|0] "" Vector__XXX
 SG_ APS_w095_DEPRECATED : 30|1@1+ (1,0) [0|0] "" Vector__XXX
 SG_ APS_w096_DEPRECATED : 31|1@1+ (1,0) [0|0] "" Vector__XXX
 SG_ APS_w097_DEPRECATED : 32|1@1+ (1,0) [0|0] "" Vector__XXX
 SG_ APS_w098_DEPRECATED : 33|1@1+ (1,0) [0|0] "" Vector__XXX
 SG_ APS_w099_DEPRECATED : 34|1@1+ (1,0) [0|0] "" Vector__XXX
 SG_ APS_w100_DEPRECATED : 35|1@1+ (1,0) [0|0] "" Vector__XXX
 SG_ APS_w101_DEPRECATED : 36|1@1+ (1,0) [0|0] "" Vector__XXX
 SG_ APS_w102_DEPRECATED : 37|1@1+ (1,0) [0|0] "" Vector__XXX
 SG_ APS_w103_robExperimentalAEB : 38|1@1+ (1,0) [0|0] "" Vector__XXX
 SG_ APS_w104_DEPRECATED : 39|1@1+ (1,0) [0|0] "" Vector__XXX
 SG_ APS_w105_DEPRECATED : 40|1@1+ (1,0) [0|0] "" Vector__XXX
 SG_ APS_w106_torsionBarOffset : 41|1@1+ (1,0) [0|0] "" Vector__XXX

BO_ 879 TPMS_StatusC: 8 Vector__XXX
 SG_ TPMS_c_globalHardWarning : 0|1@1+ (1,0) [0|0] "" Vector__XXX
 SG_ TPMS_c_globalSoftWarning : 1|1@1+ (1,0) [0|0] "" Vector__XXX
 SG_ TPMS_systemMalfunction : 2|1@1+ (1,0) [0|0] "" Vector__XXX
 SG_ TPMS_WA_version : 3|1@1+ (1,0) [0|0] "" Vector__XXX
 SG_ TPMS_globalDeltaPressure : 4|1@1+ (1,0) [0|0] "" Vector__XXX
 SG_ TPMS_newSensorLearnt : 5|3@1+ (1,0) [0|0] "" Vector__XXX
 SG_ TPMS_softWarningRR : 8|1@1+ (1,0) [0|0] "" Vector__XXX
 SG_ TPMS_hardWarningRR : 9|1@1+ (1,0) [0|0] "" Vector__XXX
 SG_ TPMS_softWarningRL : 10|1@1+ (1,0) [0|0] "" Vector__XXX
 SG_ TPMS_hardWarningRL : 11|1@1+ (1,0) [0|0] "" Vector__XXX
 SG_ TPMS_softWarningFR : 12|1@1+ (1,0) [0|0] "" Vector__XXX
 SG_ TPMS_hardWarningFR : 13|1@1+ (1,0) [0|0] "" Vector__XXX
 SG_ TPMS_softWarningFL : 14|1@1+ (1,0) [0|0] "" Vector__XXX
 SG_ TPMS_hardWarningFL : 15|1@1+ (1,0) [0|0] "" Vector__XXX
 SG_ TPMS_learningStatus : 16|2@1+ (1,0) [0|0] "" Vector__XXX
 SG_ TPMS_localisationStatus : 18|2@1+ (1,0) [0|0] "" Vector__XXX
 SG_ TPMS_deltaPressWarningFL : 20|1@1+ (1,0) [0|0] "" Vector__XXX
 SG_ TPMS_deltaPressWarningFR : 21|1@1+ (1,0) [0|0] "" Vector__XXX
 SG_ TPMS_deltaPressWarningRL : 22|1@1+ (1,0) [0|0] "" Vector__XXX
 SG_ TPMS_deltaPressWarningRR : 23|1@1+ (1,0) [0|0] "" Vector__XXX
 SG_ TPMS_sensorNoResponseFL : 24|1@1+ (1,0) [0|0] "" Vector__XXX
 SG_ TPMS_sensorNoResponseFR : 25|1@1+ (1,0) [0|0] "" Vector__XXX
 SG_ TPMS_sensorNoResponseRL : 26|1@1+ (1,0) [0|0] "" Vector__XXX
 SG_ TPMS_sensorNoResponseRR : 27|1@1+ (1,0) [0|0] "" Vector__XXX
 SG_ TPMS_sensorThermShutdownFL : 28|1@1+ (1,0) [0|0] "" Vector__XXX
 SG_ TPMS_sensorThermShutdownFR : 29|1@1+ (1,0) [0|0] "" Vector__XXX
 SG_ TPMS_sensorThermShutdownRL : 30|1@1+ (1,0) [0|0] "" Vector__XXX
 SG_ TPMS_sensorThermShutdownRR : 31|1@1+ (1,0) [0|0] "" Vector__XXX
 SG_ TPMS_sensorBatteryLowFL : 32|1@1+ (1,0) [0|0] "" Vector__XXX
 SG_ TPMS_sensorBatteryLowFR : 33|1@1+ (1,0) [0|0] "" Vector__XXX
 SG_ TPMS_sensorBatteryLowRL : 34|1@1+ (1,0) [0|0] "" Vector__XXX
 SG_ TPMS_sensorBatteryLowRR : 35|1@1+ (1,0) [0|0] "" Vector__XXX
 SG_ TPMS_sensorDefectiveFL : 36|1@1+ (1,0) [0|0] "" Vector__XXX
 SG_ TPMS_sensorDefectiveFR : 37|1@1+ (1,0) [0|0] "" Vector__XXX
 SG_ TPMS_sensorDefectiveRL : 38|1@1+ (1,0) [0|0] "" Vector__XXX
 SG_ TPMS_sensorDefectiveRR : 39|1@1+ (1,0) [0|0] "" Vector__XXX
 SG_ TPMS_ecuUnderVoltage : 40|1@1+ (1,0) [0|0] "" Vector__XXX
 SG_ TPMS_ecuOverVoltage : 41|1@1+ (1,0) [0|0] "" Vector__XXX
 SG_ TPMS_ecuRamRomNvMFail : 42|1@1+ (1,0) [0|0] "" Vector__XXX
 SG_ TPMS_rfReceiverFail : 43|1@1+ (1,0) [0|0] "" Vector__XXX
 SG_ TPMS_wheelPulseMissing : 44|1@1+ (1,0) [0|0] "" Vector__XXX
 SG_ TPMS_vehicleSpeedFail : 45|1@1+ (1,0) [0|0] "" Vector__XXX
 SG_ TPMS_externalTemperatureFail : 46|1@1+ (1,0) [0|0] "" Vector__XXX
 SG_ TPMS_eolNotCompleted : 47|1@1+ (1,0) [0|0] "" Vector__XXX
 SG_ TPMS_rcpFront : 48|8@1+ (0.025,0) [0|0] "" Vector__XXX
 SG_ TPMS_rcpRear : 56|8@1+ (0.025,0) [0|0] "" Vector__XXX

BO_ 880 EPAS3S_sysStatus: 8 Vector__XXX
 SG_ EPAS3S_steeringRackForce : 1|10@0+ (50,-25575) [0|0] "" Vector__XXX
 SG_ EPAS3S_steeringFault : 2|1@0+ (1,0) [0|0] "" Vector__XXX
 SG_ EPAS3S_steeringReduced : 3|1@0+ (1,0) [0|0] "" Vector__XXX
 SG_ EPAS3S_internalSASQF : 4|1@0+ (1,0) [0|0] "" Vector__XXX
 SG_ EPAS3S_currentTuneMode : 7|3@0+ (1,0) [0|0] "" Vector__XXX
 SG_ EPAS3S_torsionBarTorque : 19|12@0+ (0.01,-20.5) [0|0] "" Vector__XXX
 SG_ EPAS3S_eacErrorCode : 23|4@0+ (1,0) [0|0] "" Vector__XXX
 SG_ EPAS3S_internalSAS : 37|14@0+ (0.1,-819.2) [0|0] "" Vector__XXX
 SG_ EPAS3S_handsOnLevel : 39|2@0+ (1,0) [0|0] "" Vector__XXX
 SG_ EPAS3S_sysStatusCounter : 51|4@0+ (1,0) [0|0] "" Vector__XXX
 SG_ EPAS3S_tireIDActive : 52|1@1+ (1,0) [0|0] "" Vector__XXX
 SG_ EPAS3S_eacStatus : 55|3@0+ (1,0) [0|0] "" Vector__XXX
 SG_ EPAS3S_sysStatusChecksum : 63|8@0+ (1,0) [0|0] "" Vector__XXX

BO_ 881 RCM_alertMatrix: 8 Vector__XXX
 SG_ RCM_matrixIndex M : 0|4@1+ (1,0) [0|0] "" Vector__XXX
 SG_ RCM_a000_crashDetected m0 : 4|1@1+ (1,0) [0|0] "" Vector__XXX
 SG_ RCM_a060_stpsLeft m1 : 4|1@1+ (1,0) [0|0] "" Vector__XXX
 SG_ RCM_a001_nearDeploy m0 : 5|1@1+ (1,0) [0|0] "" Vector__XXX
 SG_ RCM_a061_stpsRight m1 : 5|1@1+ (1,0) [0|0] "" Vector__XXX
 SG_ RCM_a002_airbagsNotArmed m0 : 6|1@1+ (1,0) [0|0] "" Vector__XXX
 SG_ RCM_a062_alrSwitch m1 : 6|1@1+ (1,0) [0|0] "" Vector__XXX
 SG_ RCM_a003_warningIndicator m0 : 7|1@1+ (1,0) [0|0] "" Vector__XXX
 SG_ RCM_a063_sbsw2ndRowRight m1 : 7|1@1+ (1,0) [0|0] "" Vector__XXX
 SG_ RCM_a004_internalFault m0 : 8|1@1+ (1,0) [0|0] "" Vector__XXX
 SG_ RCM_a064_hardwareCodingPin1 m1 : 8|1@1+ (1,0) [0|0] "" Vector__XXX
 SG_ RCM_a005_crcError m0 : 9|1@1+ (1,0) [0|0] "" Vector__XXX
 SG_ RCM_a065_driverOrientConfigPin m1 : 9|1@1+ (1,0) [0|0] "" Vector__XXX
 SG_ RCM_a006_batteryVoltageRange m0 : 10|1@1+ (1,0) [0|0] "" Vector__XXX
 SG_ RCM_a066_seatBackSw2ndRowLeft m1 : 10|1@1+ (1,0) [0|0] "" Vector__XXX
 SG_ RCM_a007_powerSupplyExternal m0 : 11|1@1+ (1,0) [0|0] "" Vector__XXX
 SG_ RCM_a067_comCANInitFailure m1 : 11|1@1+ (1,0) [0|0] "" Vector__XXX
 SG_ RCM_a008_powerSupplyInternal m0 : 12|1@1+ (1,0) [0|0] "" Vector__XXX
 SG_ RCM_a068_comChassisBusOff m1 : 12|1@1+ (1,0) [0|0] "" Vector__XXX
 SG_ RCM_a009_reprogramLimit m0 : 13|1@1+ (1,0) [0|0] "" Vector__XXX
 SG_ RCM_a069_comCHCANPH7 m1 : 13|1@1+ (1,0) [0|0] "" Vector__XXX
 SG_ RCM_a010_scmDisabled m0 : 14|1@1+ (1,0) [0|0] "" Vector__XXX
 SG_ RCM_a070_comCHCANPH8 m1 : 14|1@1+ (1,0) [0|0] "" Vector__XXX
 SG_ RCM_a011_eepromDataLocked m0 : 15|1@1+ (1,0) [0|0] "" Vector__XXX
 SG_ RCM_a071_comCHCANPH9 m1 : 15|1@1+ (1,0) [0|0] "" Vector__XXX
 SG_ RCM_a012_vinStorage m0 : 16|1@1+ (1,0) [0|0] "" Vector__XXX
 SG_ RCM_a072_comUnused m1 : 16|1@1+ (1,0) [0|0] "" Vector__XXX
 SG_ RCM_a013_driverOrientation m0 : 17|1@1+ (1,0) [0|0] "" Vector__XXX
 SG_ RCM_a073_comCHCANPH4 m1 : 17|1@1+ (1,0) [0|0] "" Vector__XXX
 SG_ RCM_a014_driverABStage1 m0 : 18|1@1+ (1,0) [0|0] "" Vector__XXX
 SG_ RCM_a074_comCHCANPH5 m1 : 18|1@1+ (1,0) [0|0] "" Vector__XXX
 SG_ RCM_a015_driverABStage2 m0 : 19|1@1+ (1,0) [0|0] "" Vector__XXX
 SG_ RCM_a075_comCHCANPH6 m1 : 19|1@1+ (1,0) [0|0] "" Vector__XXX
 SG_ RCM_a016_passABStage1 m0 : 20|1@1+ (1,0) [0|0] "" Vector__XXX
 SG_ RCM_a076_comEPBLStatus m1 : 20|1@1+ (1,0) [0|0] "" Vector__XXX
 SG_ RCM_a017_passABStage2 m0 : 21|1@1+ (1,0) [0|0] "" Vector__XXX
 SG_ RCM_a077_comEPBRStatus m1 : 21|1@1+ (1,0) [0|0] "" Vector__XXX
 SG_ RCM_a018_passengerActiveVent m0 : 22|1@1+ (1,0) [0|0] "" Vector__XXX
 SG_ RCM_a078_comOCS1PStatus m1 : 22|1@1+ (1,0) [0|0] "" Vector__XXX
 SG_ RCM_a019_pretenShldrFrontLeft m0 : 23|1@1+ (1,0) [0|0] "" Vector__XXX
 SG_ RCM_a079_comOCS1DStatus m1 : 23|1@1+ (1,0) [0|0] "" Vector__XXX
 SG_ RCM_a020_pretenShldFrontRight m0 : 24|1@1+ (1,0) [0|0] "" Vector__XXX
 SG_ RCM_a080_comGTWACS m1 : 24|1@1+ (1,0) [0|0] "" Vector__XXX
 SG_ RCM_a021_pretenLapFrontLeft m0 : 25|1@1+ (1,0) [0|0] "" Vector__XXX
 SG_ RCM_a081_comVCFRONTLVPwr m1 : 25|1@1+ (1,0) [0|0] "" Vector__XXX
 SG_ RCM_a022_pretenLapFrontRight m0 : 26|1@1+ (1,0) [0|0] "" Vector__XXX
 SG_ RCM_a082_comUIodo m1 : 26|1@1+ (1,0) [0|0] "" Vector__XXX
 SG_ RCM_a023_loadLimiterLeftSide m0 : 27|1@1+ (1,0) [0|0] "" Vector__XXX
 SG_ RCM_a083_comGTWCarState m1 : 27|1@1+ (1,0) [0|0] "" Vector__XXX
 SG_ RCM_a024_loadLimiterRightSide m0 : 28|1@1+ (1,0) [0|0] "" Vector__XXX
 SG_ RCM_a084_comTPMSStatus m1 : 28|1@1+ (1,0) [0|0] "" Vector__XXX
 SG_ RCM_a025_kneeABDriver m0 : 29|1@1+ (1,0) [0|0] "" Vector__XXX
 SG_ RCM_a085_comGTWCarConfig m1 : 29|1@1+ (1,0) [0|0] "" Vector__XXX
 SG_ RCM_a026_kneeABFrontPassenger m0 : 30|1@1+ (1,0) [0|0] "" Vector__XXX
 SG_ RCM_a086_comVINMIA m1 : 30|1@1+ (1,0) [0|0] "" Vector__XXX
 SG_ RCM_a027_sideAB1stRowLeft m0 : 31|1@1+ (1,0) [0|0] "" Vector__XXX
 SG_ RCM_a087_comCANSilent m1 : 31|1@1+ (1,0) [0|0] "" Vector__XXX
 SG_ RCM_a028_sideAB1stRowRight m0 : 32|1@1+ (1,0) [0|0] "" Vector__XXX
 SG_ RCM_a088_comCHCANPH2 m1 : 32|1@1+ (1,0) [0|0] "" Vector__XXX
 SG_ RCM_a029_driverABActiveVent m0 : 33|1@1+ (1,0) [0|0] "" Vector__XXX
 SG_ RCM_a089_comCHCANPH3 m1 : 33|1@1+ (1,0) [0|0] "" Vector__XXX
 SG_ RCM_a030_farSideInboardAirbag m0 : 34|1@1+ (1,0) [0|0] "" Vector__XXX
 SG_ RCM_a090_comPartyBusOff m1 : 34|1@1+ (1,0) [0|0] "" Vector__XXX
 SG_ RCM_a031_frontCenterAirbag m0 : 35|1@1+ (1,0) [0|0] "" Vector__XXX
 SG_ RCM_a091_comEPAS3PsysStatus m1 : 35|1@1+ (1,0) [0|0] "" Vector__XXX
 SG_ RCM_a032_curtainABLeft m0 : 36|1@1+ (1,0) [0|0] "" Vector__XXX
 SG_ RCM_a092_comDASISF m1 : 36|1@1+ (1,0) [0|0] "" Vector__XXX
 SG_ RCM_a033_curtainABRight m0 : 37|1@1+ (1,0) [0|0] "" Vector__XXX
 SG_ RCM_a093_comVCLEFTStatus m1 : 37|1@1+ (1,0) [0|0] "" Vector__XXX
 SG_ RCM_a034_preten2ndRowLeft m0 : 38|1@1+ (1,0) [0|0] "" Vector__XXX
 SG_ RCM_a094_comVCRIGHTStatus m1 : 38|1@1+ (1,0) [0|0] "" Vector__XXX
 SG_ RCM_a035_preten2ndRowRight m0 : 39|1@1+ (1,0) [0|0] "" Vector__XXX
 SG_ RCM_a095_comESPstatus m1 : 39|1@1+ (1,0) [0|0] "" Vector__XXX
 SG_ RCM_a036_curAB2ndRowLeft m0 : 40|1@1+ (1,0) [0|0] "" Vector__XXX
 SG_ RCM_a096_comESPwheelSpeeds m1 : 40|1@1+ (1,0) [0|0] "" Vector__XXX
 SG_ RCM_a037_curAB2ndRowRight m0 : 41|1@1+ (1,0) [0|0] "" Vector__XXX
 SG_ RCM_a097_comDIspeed m1 : 41|1@1+ (1,0) [0|0] "" Vector__XXX
 SG_ RCM_a038_unusedA m0 : 42|1@1+ (1,0) [0|0] "" Vector__XXX
 SG_ RCM_a098_comDIchassisControl m1 : 42|1@1+ (1,0) [0|0] "" Vector__XXX
 SG_ RCM_a039_unusedB m0 : 43|1@1+ (1,0) [0|0] "" Vector__XXX
 SG_ RCM_a099_comDItorque m1 : 43|1@1+ (1,0) [0|0] "" Vector__XXX
 SG_ RCM_a040_hoodActuatorRight m0 : 44|1@1+ (1,0) [0|0] "" Vector__XXX
 SG_ RCM_a100_comDIsystemStatus m1 : 44|1@1+ (1,0) [0|0] "" Vector__XXX
 SG_ RCM_a041_hoodActuatorLeft m0 : 45|1@1+ (1,0) [0|0] "" Vector__XXX
 SG_ RCM_a101_idfSystem m1 : 45|1@1+ (1,0) [0|0] "" Vector__XXX
 SG_ RCM_a042_ens1Line m0 : 46|1@1+ (1,0) [0|0] "" Vector__XXX
 SG_ RCM_a102_imuYawR8OffstCompLim m1 : 46|1@1+ (1,0) [0|0] "" Vector__XXX
 SG_ RCM_a043_ens2Line m0 : 47|1@1+ (1,0) [0|0] "" Vector__XXX
 SG_ RCM_a103_imuPtchR8OffstCompLim m1 : 47|1@1+ (1,0) [0|0] "" Vector__XXX
 SG_ RCM_a044_upFrontSensorLeft m0 : 48|1@1+ (1,0) [0|0] "" Vector__XXX
 SG_ RCM_a104_imuRollR8OffstCompLim m1 : 48|1@1+ (1,0) [0|0] "" Vector__XXX
 SG_ RCM_a045_upFrontSensorRight m0 : 49|1@1+ (1,0) [0|0] "" Vector__XXX
 SG_ RCM_a105_imuLongAccOffstCompLim m1 : 49|1@1+ (1,0) [0|0] "" Vector__XXX
 SG_ RCM_a046_sideAccelBPillarLeft m0 : 50|1@1+ (1,0) [0|0] "" Vector__XXX
 SG_ RCM_a106_imuLatAccOffstCompLim m1 : 50|1@1+ (1,0) [0|0] "" Vector__XXX
 SG_ RCM_a047_sideAccelBPillarRight m0 : 51|1@1+ (1,0) [0|0] "" Vector__XXX
 SG_ RCM_a107_imuVertAccOffstCompLim m1 : 51|1@1+ (1,0) [0|0] "" Vector__XXX
 SG_ RCM_a048_sideAccelCPillarLeft m0 : 52|1@1+ (1,0) [0|0] "" Vector__XXX
 SG_ RCM_a108_crashAlgoWakeup m1 : 52|1@1+ (1,0) [0|0] "" Vector__XXX
 SG_ RCM_a049_sideAccelCPillarRight m0 : 53|1@1+ (1,0) [0|0] "" Vector__XXX
 SG_ RCM_a109_abuseImmunity m1 : 53|1@1+ (1,0) [0|0] "" Vector__XXX
 SG_ RCM_a050_upFrontSensorCenter m0 : 54|1@1+ (1,0) [0|0] "" Vector__XXX
 SG_ RCM_a110_factoryMode m1 : 54|1@1+ (1,0) [0|0] "" Vector__XXX
 SG_ RCM_a051_pressureFrontLftDoor m0 : 55|1@1+ (1,0) [0|0] "" Vector__XXX
 SG_ RCM_a111_diagnosticsEnabled m1 : 55|1@1+ (1,0) [0|0] "" Vector__XXX
 SG_ RCM_a052_pressureFrontRtDoor m0 : 56|1@1+ (1,0) [0|0] "" Vector__XXX
 SG_ RCM_a112_imuYawRate m1 : 56|1@1+ (1,0) [0|0] "" Vector__XXX
 SG_ RCM_a053_pressurePedProLeft m0 : 57|1@1+ (1,0) [0|0] "" Vector__XXX
 SG_ RCM_a113_imuPitchRate m1 : 57|1@1+ (1,0) [0|0] "" Vector__XXX
 SG_ RCM_a054_pressurePedProRight m0 : 58|1@1+ (1,0) [0|0] "" Vector__XXX
 SG_ RCM_a114_imuRollRate m1 : 58|1@1+ (1,0) [0|0] "" Vector__XXX
 SG_ RCM_a055_inertialMeasurement m0 : 59|1@1+ (1,0) [0|0] "" Vector__XXX
 SG_ RCM_a115_imuLinearAcceleration m1 : 59|1@1+ (1,0) [0|0] "" Vector__XXX
 SG_ RCM_a056_passengerFrontOCS m0 : 60|1@1+ (1,0) [0|0] "" Vector__XXX
 SG_ RCM_a116_imuLateralAcceleration m1 : 60|1@1+ (1,0) [0|0] "" Vector__XXX
 SG_ RCM_a057_driverOCS m0 : 61|1@1+ (1,0) [0|0] "" Vector__XXX
 SG_ RCM_a117_imuVerticalAcceleration m1 : 61|1@1+ (1,0) [0|0] "" Vector__XXX
 SG_ RCM_a058_buckle1stRowLeft m0 : 62|1@1+ (1,0) [0|0] "" Vector__XXX
 SG_ RCM_a118_imuInPlaneAcceleration m1 : 62|1@1+ (1,0) [0|0] "" Vector__XXX
 SG_ RCM_a059_buckle1stRowRight m0 : 63|1@1+ (1,0) [0|0] "" Vector__XXX

BO_ 882 TRCM_alertMatrix: 8 Vector__XXX
 SG_ TRCM_matrixIndex M : 0|4@1+ (1,0) [0|0] "" Vector__XXX
 SG_ TRCM_a001_airbagsDisabled m0 : 4|1@1+ (1,0) [0|0] "" Vector__XXX
 SG_ TRCM_a061_XCPConnected m1 : 4|1@1+ (1,0) [0|0] "" Vector__XXX
 SG_ TRCM_a301_passengerAirbagStage1Suppressed m5 : 4|1@1+ (1,0) [0|0] "" Vector__XXX
 SG_ TRCM_a421_hoodLifterRightIssue m7 : 4|1@1+ (1,0) [0|0] "" Vector__XXX
 SG_ TRCM_a601_loop0AsicStartupDiagnosticFailure m10 : 4|1@1+ (1,0) [0|0] "" Vector__XXX
 SG_ TRCM_a002_systemDisabled m0 : 5|1@1+ (1,0) [0|0] "" Vector__XXX
 SG_ TRCM_a062_XCPWasConnected m1 : 5|1@1+ (1,0) [0|0] "" Vector__XXX
 SG_ TRCM_a302_driverAirbagStage2Suppressed m5 : 5|1@1+ (1,0) [0|0] "" Vector__XXX
 SG_ TRCM_a422_seatbeltShoulderPretensionerRearLeftIssue m7 : 5|1@1+ (1,0) [0|0] "" Vector__XXX
 SG_ TRCM_a602_loop1AsicStartupDiagnosticFailure m10 : 5|1@1+ (1,0) [0|0] "" Vector__XXX
 SG_ TRCM_a003_SWAssertion m0 : 6|1@1+ (1,0) [0|0] "" Vector__XXX
 SG_ TRCM_a063_SwitchFault m1 : 6|1@1+ (1,0) [0|0] "" Vector__XXX
 SG_ TRCM_a303_driverAirbagActiveVentSuppressed m5 : 6|1@1+ (1,0) [0|0] "" Vector__XXX
 SG_ TRCM_a423_seatbeltShoulderPretensionerRearRightIssue m7 : 6|1@1+ (1,0) [0|0] "" Vector__XXX
 SG_ TRCM_a603_loop2AsicStartupDiagnosticFailure m10 : 6|1@1+ (1,0) [0|0] "" Vector__XXX
 SG_ TRCM_a004_internalFailure m0 : 7|1@1+ (1,0) [0|0] "" Vector__XXX
 SG_ TRCM_a064_busSleepReqTimeout m1 : 7|1@1+ (1,0) [0|0] "" Vector__XXX
 SG_ TRCM_a304_passengerAirbagStage2Suppressed m5 : 7|1@1+ (1,0) [0|0] "" Vector__XXX
 SG_ TRCM_a364_safingEngine0NoValidData m6 : 7|1@1+ (1,0) [0|0] "" Vector__XXX
 SG_ TRCM_a544_erCapDiagnosticsFailed m9 : 7|1@1+ (1,0) [0|0] "" Vector__XXX
 SG_ TRCM_a604_loop3AsicStartupDiagnosticFailure m10 : 7|1@1+ (1,0) [0|0] "" Vector__XXX
 SG_ TRCM_a005_CANTXError m0 : 8|1@1+ (1,0) [0|0] "" Vector__XXX
 SG_ TRCM_a065_vSafingFetUnderVoltage m1 : 8|1@1+ (1,0) [0|0] "" Vector__XXX
 SG_ TRCM_a305_passengerAirbagActiveVentSuppressed m5 : 8|1@1+ (1,0) [0|0] "" Vector__XXX
 SG_ TRCM_a365_safingEngine1NoValidData m6 : 8|1@1+ (1,0) [0|0] "" Vector__XXX
 SG_ TRCM_a545_erCapBelowAutarkyThreshold m9 : 8|1@1+ (1,0) [0|0] "" Vector__XXX
 SG_ TRCM_a605_loop4AsicStartupDiagnosticFailure m10 : 8|1@1+ (1,0) [0|0] "" Vector__XXX
 SG_ TRCM_a006_CANTX_cyclicError m0 : 9|1@1+ (1,0) [0|0] "" Vector__XXX
 SG_ TRCM_a066_leftPowerIssue m1 : 9|1@1+ (1,0) [0|0] "" Vector__XXX
 SG_ TRCM_a366_safingEngine2NoValidData m6 : 9|1@1+ (1,0) [0|0] "" Vector__XXX
 SG_ TRCM_a546_sensorValuesFaultedBySmart m9 : 9|1@1+ (1,0) [0|0] "" Vector__XXX
 SG_ TRCM_a606_loop5AsicStartupDiagnosticFailure m10 : 9|1@1+ (1,0) [0|0] "" Vector__XXX
 SG_ TRCM_a007_chassisChecksumError m0 : 10|1@1+ (1,0) [0|0] "" Vector__XXX
 SG_ TRCM_a067_rightPowerIssue m1 : 10|1@1+ (1,0) [0|0] "" Vector__XXX
 SG_ TRCM_a367_safingEngine3NoValidData m6 : 10|1@1+ (1,0) [0|0] "" Vector__XXX
 SG_ TRCM_a607_loop6AsicStartupDiagnosticFailure m10 : 10|1@1+ (1,0) [0|0] "" Vector__XXX
 SG_ TRCM_a008_chassisCounterError m0 : 11|1@1+ (1,0) [0|0] "" Vector__XXX
 SG_ TRCM_a068_vBusCUnderVoltage m1 : 11|1@1+ (1,0) [0|0] "" Vector__XXX
 SG_ TRCM_a308_kneeAirbagLeftSuppressed m5 : 11|1@1+ (1,0) [0|0] "" Vector__XXX
 SG_ TRCM_a368_safingEngine4NoValidData m6 : 11|1@1+ (1,0) [0|0] "" Vector__XXX
 SG_ TRCM_a608_loop7AsicStartupDiagnosticFailure m10 : 11|1@1+ (1,0) [0|0] "" Vector__XXX
 SG_ TRCM_a009_partyChecksumError m0 : 12|1@1+ (1,0) [0|0] "" Vector__XXX
 SG_ TRCM_a069_swAppBoot m1 : 12|1@1+ (1,0) [0|0] "" Vector__XXX
 SG_ TRCM_a309_kneeAirbagRightSuppressed m5 : 12|1@1+ (1,0) [0|0] "" Vector__XXX
 SG_ TRCM_a369_safingEngine5NoValidData m6 : 12|1@1+ (1,0) [0|0] "" Vector__XXX
 SG_ TRCM_a609_loop8AsicStartupDiagnosticFailure m10 : 12|1@1+ (1,0) [0|0] "" Vector__XXX
 SG_ TRCM_a010_partyCounterError m0 : 13|1@1+ (1,0) [0|0] "" Vector__XXX
 SG_ TRCM_a070_asm3StatusError m1 : 13|1@1+ (1,0) [0|0] "" Vector__XXX
 SG_ TRCM_a310_curtainAirbagLeftSuppressed m5 : 13|1@1+ (1,0) [0|0] "" Vector__XXX
 SG_ TRCM_a370_safingEngine6NoValidData m6 : 13|1@1+ (1,0) [0|0] "" Vector__XXX
 SG_ TRCM_a550_AlgoWake_RCM_WAKE_FRONT m9 : 13|1@1+ (1,0) [0|0] "" Vector__XXX
 SG_ TRCM_a610_loop9AsicStartupDiagnosticFailure m10 : 13|1@1+ (1,0) [0|0] "" Vector__XXX
 SG_ TRCM_a011_edrDataLocked m0 : 14|1@1+ (1,0) [0|0] "" Vector__XXX
 SG_ TRCM_a071_asm3DeviceFaulted m1 : 14|1@1+ (1,0) [0|0] "" Vector__XXX
 SG_ TRCM_a311_curtainAirbagRightSuppressed m5 : 14|1@1+ (1,0) [0|0] "" Vector__XXX
 SG_ TRCM_a371_safingEngine7NoValidData m6 : 14|1@1+ (1,0) [0|0] "" Vector__XXX
 SG_ TRCM_a551_AlgoWake_RCM_WAKE_REAR m9 : 14|1@1+ (1,0) [0|0] "" Vector__XXX
 SG_ TRCM_a611_loop10AsicStartupDiagnosticFailure m10 : 14|1@1+ (1,0) [0|0] "" Vector__XXX
 SG_ TRCM_a012_asm5TemperatureOutsideSignalRange m0 : 15|1@1+ (1,0) [0|0] "" Vector__XXX
 SG_ TRCM_a072_ais2120StatusError m1 : 15|1@1+ (1,0) [0|0] "" Vector__XXX
 SG_ TRCM_a312_seatbeltLoadLimiterFrontLeftSuppressed m5 : 15|1@1+ (1,0) [0|0] "" Vector__XXX
 SG_ TRCM_a372_safingEngine8NoValidData m6 : 15|1@1+ (1,0) [0|0] "" Vector__XXX
 SG_ TRCM_a432_driverAirbagStage1ConfigError m7 : 15|1@1+ (1,0) [0|0] "" Vector__XXX
 SG_ TRCM_a552_AlgoWake_RCM_WAKE_LEFT m9 : 15|1@1+ (1,0) [0|0] "" Vector__XXX
 SG_ TRCM_a612_loop11AsicStartupDiagnosticFailure m10 : 15|1@1+ (1,0) [0|0] "" Vector__XXX
 SG_ TRCM_a013_AlertManagerFault m0 : 16|1@1+ (1,0) [0|0] "" Vector__XXX
 SG_ TRCM_a073_ais2120DeviceFaulted m1 : 16|1@1+ (1,0) [0|0] "" Vector__XXX
 SG_ TRCM_a313_seatbeltLoadLimiterFrontRightSuppressed m5 : 16|1@1+ (1,0) [0|0] "" Vector__XXX
 SG_ TRCM_a373_safingEngine9NoValidData m6 : 16|1@1+ (1,0) [0|0] "" Vector__XXX
 SG_ TRCM_a433_passengerAirbagStage1ConfigError m7 : 16|1@1+ (1,0) [0|0] "" Vector__XXX
 SG_ TRCM_a553_AlgoWake_RCM_WAKE_RIGHT m9 : 16|1@1+ (1,0) [0|0] "" Vector__XXX
 SG_ TRCM_a613_loop12AsicStartupDiagnosticFailure m10 : 16|1@1+ (1,0) [0|0] "" Vector__XXX
 SG_ TRCM_a014_asm3TemperatureOutsideSignalRange m0 : 17|1@1+ (1,0) [0|0] "" Vector__XXX
 SG_ TRCM_a074_ais2120SelfTestXPositiveFailed m1 : 17|1@1+ (1,0) [0|0] "" Vector__XXX
 SG_ TRCM_a314_seatbeltShoulderPretensionerFrontLeftSuppressed m5 : 17|1@1+ (1,0) [0|0] "" Vector__XXX
 SG_ TRCM_a374_safingEngine10NoValidData m6 : 17|1@1+ (1,0) [0|0] "" Vector__XXX
 SG_ TRCM_a434_driverAirbagStage2ConfigError m7 : 17|1@1+ (1,0) [0|0] "" Vector__XXX
 SG_ TRCM_a554_AlgoWake_PAS_LH_PLAUSI_FRONT m9 : 17|1@1+ (1,0) [0|0] "" Vector__XXX
 SG_ TRCM_a614_loop13AsicStartupDiagnosticFailure m10 : 17|1@1+ (1,0) [0|0] "" Vector__XXX
 SG_ TRCM_a015_NVMMError m0 : 18|1@1+ (1,0) [0|0] "" Vector__XXX
 SG_ TRCM_a075_ais2120SelfTestXNegativeFailed m1 : 18|1@1+ (1,0) [0|0] "" Vector__XXX
 SG_ TRCM_a135_asm5StatusError m2 : 18|1@1+ (1,0) [0|0] "" Vector__XXX
 SG_ TRCM_a315_seatbeltShoulderPretensionerFrontRightSuppressed m5 : 18|1@1+ (1,0) [0|0] "" Vector__XXX
 SG_ TRCM_a375_safingEngine11NoValidData m6 : 18|1@1+ (1,0) [0|0] "" Vector__XXX
 SG_ TRCM_a435_driverAirbagActiveVentConfigError m7 : 18|1@1+ (1,0) [0|0] "" Vector__XXX
 SG_ TRCM_a555_AlgoWake_PAS_LH_PLAUSI_REAR m9 : 18|1@1+ (1,0) [0|0] "" Vector__XXX
 SG_ TRCM_a615_loop14AsicStartupDiagnosticFailure m10 : 18|1@1+ (1,0) [0|0] "" Vector__XXX
 SG_ TRCM_a016_NVMMRecordError m0 : 19|1@1+ (1,0) [0|0] "" Vector__XXX
 SG_ TRCM_a076_ais2120SelfTestYPositiveFailed m1 : 19|1@1+ (1,0) [0|0] "" Vector__XXX
 SG_ TRCM_a136_asm5DeviceFaulted m2 : 19|1@1+ (1,0) [0|0] "" Vector__XXX
 SG_ TRCM_a316_seatbeltLapPretensionerFrontLeftSuppressed m5 : 19|1@1+ (1,0) [0|0] "" Vector__XXX
 SG_ TRCM_a376_safingEngine12NoValidData m6 : 19|1@1+ (1,0) [0|0] "" Vector__XXX
 SG_ TRCM_a436_passengerAirbagStage2ConfigError m7 : 19|1@1+ (1,0) [0|0] "" Vector__XXX
 SG_ TRCM_a556_AlgoWake_PAS_LH_PLAUSI m9 : 19|1@1+ (1,0) [0|0] "" Vector__XXX
 SG_ TRCM_a616_loop15AsicStartupDiagnosticFailure m10 : 19|1@1+ (1,0) [0|0] "" Vector__XXX
 SG_ TRCM_a017_asm5TemperatureOutsideOperatingRange m0 : 20|1@1+ (1,0) [0|0] "" Vector__XXX
 SG_ TRCM_a077_ais2120SelfTestYNegativeFailed m1 : 20|1@1+ (1,0) [0|0] "" Vector__XXX
 SG_ TRCM_a137_ext1AsicSnoopTestFailed m2 : 20|1@1+ (1,0) [0|0] "" Vector__XXX
 SG_ TRCM_a317_seatbeltLapPretensionerFrontRightSuppressed m5 : 20|1@1+ (1,0) [0|0] "" Vector__XXX
 SG_ TRCM_a377_safingEngine13NoValidData m6 : 20|1@1+ (1,0) [0|0] "" Vector__XXX
 SG_ TRCM_a437_passengerAirbagActiveVentConfigError m7 : 20|1@1+ (1,0) [0|0] "" Vector__XXX
 SG_ TRCM_a557_AlgoWake_PAS_RH_PLAUSI_FRONT m9 : 20|1@1+ (1,0) [0|0] "" Vector__XXX
 SG_ TRCM_a617_loop16AsicStartupDiagnosticFailure m10 : 20|1@1+ (1,0) [0|0] "" Vector__XXX
 SG_ TRCM_a018_asm3TemperatureOutsideOperatingRange m0 : 21|1@1+ (1,0) [0|0] "" Vector__XXX
 SG_ TRCM_a078_imuSensorSignalMonitor m1 : 21|1@1+ (1,0) [0|0] "" Vector__XXX
 SG_ TRCM_a138_ext2AsicSnoopTestFailed m2 : 21|1@1+ (1,0) [0|0] "" Vector__XXX
 SG_ TRCM_a318_outboardSeatAirbagLeftSuppressed m5 : 21|1@1+ (1,0) [0|0] "" Vector__XXX
 SG_ TRCM_a378_safingEngine14NoValidData m6 : 21|1@1+ (1,0) [0|0] "" Vector__XXX
 SG_ TRCM_a558_AlgoWake_PAS_RH_PLAUSI_REAR m9 : 21|1@1+ (1,0) [0|0] "" Vector__XXX
 SG_ TRCM_a618_loop17AsicStartupDiagnosticFailure m10 : 21|1@1+ (1,0) [0|0] "" Vector__XXX
 SG_ TRCM_a019_Task500usError m0 : 22|1@1+ (1,0) [0|0] "" Vector__XXX
 SG_ TRCM_a319_outboardSeatAirbagRightSuppressed m5 : 22|1@1+ (1,0) [0|0] "" Vector__XXX
 SG_ TRCM_a379_safingEngine15NoValidData m6 : 22|1@1+ (1,0) [0|0] "" Vector__XXX
 SG_ TRCM_a559_AlgoWake_PAS_RH_PLAUSI m9 : 22|1@1+ (1,0) [0|0] "" Vector__XXX
 SG_ TRCM_a619_loop18AsicStartupDiagnosticFailure m10 : 22|1@1+ (1,0) [0|0] "" Vector__XXX
 SG_ TRCM_a020_asm3ComStatusError m0 : 23|1@1+ (1,0) [0|0] "" Vector__XXX
 SG_ TRCM_a200_rightBPillarAccelReportedError m3 : 23|1@1+ (1,0) [0|0] "" Vector__XXX
 SG_ TRCM_a320_hoodLifterLeftSuppressed m5 : 23|1@1+ (1,0) [0|0] "" Vector__XXX
 SG_ TRCM_a380_safingEngine16NoValidData m6 : 23|1@1+ (1,0) [0|0] "" Vector__XXX
 SG_ TRCM_a440_kneeAirbagLeftConfigError m7 : 23|1@1+ (1,0) [0|0] "" Vector__XXX
 SG_ TRCM_a560_AlgoWake_RCM_WAKE_ROLL_LEFT m9 : 23|1@1+ (1,0) [0|0] "" Vector__XXX
 SG_ TRCM_a620_loop19AsicStartupDiagnosticFailure m10 : 23|1@1+ (1,0) [0|0] "" Vector__XXX
 SG_ TRCM_a021_TaskSchedulerError m0 : 24|1@1+ (1,0) [0|0] "" Vector__XXX
 SG_ TRCM_a081_powerLossDetected m1 : 24|1@1+ (1,0) [0|0] "" Vector__XXX
 SG_ TRCM_a201_rightBPillarAccelGeneralIssue m3 : 24|1@1+ (1,0) [0|0] "" Vector__XXX
 SG_ TRCM_a321_hoodLifterRightSuppressed m5 : 24|1@1+ (1,0) [0|0] "" Vector__XXX
 SG_ TRCM_a381_safingEngine17NoValidData m6 : 24|1@1+ (1,0) [0|0] "" Vector__XXX
 SG_ TRCM_a441_kneeAirbagRightConfigError m7 : 24|1@1+ (1,0) [0|0] "" Vector__XXX
 SG_ TRCM_a561_AlgoWake_RCM_WAKE_ROLL_RIGHT m9 : 24|1@1+ (1,0) [0|0] "" Vector__XXX
 SG_ TRCM_a621_loop20AsicStartupDiagnosticFailure m10 : 24|1@1+ (1,0) [0|0] "" Vector__XXX
 SG_ TRCM_a022_TaskInitError m0 : 25|1@1+ (1,0) [0|0] "" Vector__XXX
 SG_ TRCM_a082_VCRIGHT_IPC_MIA m1 : 25|1@1+ (1,0) [0|0] "" Vector__XXX
 SG_ TRCM_a202_rightBPillarAccelElectricalIssue m3 : 25|1@1+ (1,0) [0|0] "" Vector__XXX
 SG_ TRCM_a322_seatbeltShoulderPretensionerRearLeftSuppressed m5 : 25|1@1+ (1,0) [0|0] "" Vector__XXX
 SG_ TRCM_a382_safingEngine18NoValidData m6 : 25|1@1+ (1,0) [0|0] "" Vector__XXX
 SG_ TRCM_a442_curtainAirbagLeftConfigError m7 : 25|1@1+ (1,0) [0|0] "" Vector__XXX
 SG_ TRCM_a562_AlgoWake_RCM_AWAKE_FRONT m9 : 25|1@1+ (1,0) [0|0] "" Vector__XXX
 SG_ TRCM_a622_loop21AsicStartupDiagnosticFailure m10 : 25|1@1+ (1,0) [0|0] "" Vector__XXX
 SG_ TRCM_a023_asm3ArsStatusXError m0 : 26|1@1+ (1,0) [0|0] "" Vector__XXX
 SG_ TRCM_a083_VCLEFT_IPC_MIA m1 : 26|1@1+ (1,0) [0|0] "" Vector__XXX
 SG_ TRCM_a203_rightBPillarAccelConfigError m3 : 26|1@1+ (1,0) [0|0] "" Vector__XXX
 SG_ TRCM_a323_seatbeltShoulderPretensionerRearRightSuppressed m5 : 26|1@1+ (1,0) [0|0] "" Vector__XXX
 SG_ TRCM_a383_safingEngine19NoValidData m6 : 26|1@1+ (1,0) [0|0] "" Vector__XXX
 SG_ TRCM_a443_curtainAirbagRightConfigError m7 : 26|1@1+ (1,0) [0|0] "" Vector__XXX
 SG_ TRCM_a563_AlgoWake_RCM_AWAKE_REAR m9 : 26|1@1+ (1,0) [0|0] "" Vector__XXX
 SG_ TRCM_a623_loop22AsicStartupDiagnosticFailure m10 : 26|1@1+ (1,0) [0|0] "" Vector__XXX
 SG_ TRCM_a024_asm3AccStatusError m0 : 27|1@1+ (1,0) [0|0] "" Vector__XXX
 SG_ TRCM_a084_TPMS_MIA m1 : 27|1@1+ (1,0) [0|0] "" Vector__XXX
 SG_ TRCM_a204_rightBPillarAccelSignalMonitor m3 : 27|1@1+ (1,0) [0|0] "" Vector__XXX
 SG_ TRCM_a384_safingEngine20NoValidData m6 : 27|1@1+ (1,0) [0|0] "" Vector__XXX
 SG_ TRCM_a444_seatbeltLoadLimiterFrontLeftConfigError m7 : 27|1@1+ (1,0) [0|0] "" Vector__XXX
 SG_ TRCM_a564_AlgoWake_RCM_AWAKE_LEFT m9 : 27|1@1+ (1,0) [0|0] "" Vector__XXX
 SG_ TRCM_a624_loop23AsicStartupDiagnosticFailure m10 : 27|1@1+ (1,0) [0|0] "" Vector__XXX
 SG_ TRCM_a025_CHCANBusFaults m0 : 28|1@1+ (1,0) [0|0] "" Vector__XXX
 SG_ TRCM_a085_CCCM_MIA m1 : 28|1@1+ (1,0) [0|0] "" Vector__XXX
 SG_ TRCM_a145_frontCenterAccelReportedError m2 : 28|1@1+ (1,0) [0|0] "" Vector__XXX
 SG_ TRCM_a205_rightCPillarAccelReportedError m3 : 28|1@1+ (1,0) [0|0] "" Vector__XXX
 SG_ TRCM_a385_safingEngine21NoValidData m6 : 28|1@1+ (1,0) [0|0] "" Vector__XXX
 SG_ TRCM_a445_seatbeltLoadLimiterFrontRightConfigError m7 : 28|1@1+ (1,0) [0|0] "" Vector__XXX
 SG_ TRCM_a565_AlgoWake_RCM_AWAKE_RIGHT m9 : 28|1@1+ (1,0) [0|0] "" Vector__XXX
 SG_ TRCM_a625_loop24AsicStartupDiagnosticFailure m10 : 28|1@1+ (1,0) [0|0] "" Vector__XXX
 SG_ TRCM_a026_airbagAsicDiagnosticFault m0 : 29|1@1+ (1,0) [0|0] "" Vector__XXX
 SG_ TRCM_a086_VCBATT_MIA m1 : 29|1@1+ (1,0) [0|0] "" Vector__XXX
 SG_ TRCM_a146_frontCenterAccelGeneralIssue m2 : 29|1@1+ (1,0) [0|0] "" Vector__XXX
 SG_ TRCM_a206_rightCPillarAccelGeneralIssue m3 : 29|1@1+ (1,0) [0|0] "" Vector__XXX
 SG_ TRCM_a446_seatbeltShoulderPretensionerFrontLeftConfigError m7 : 29|1@1+ (1,0) [0|0] "" Vector__XXX
 SG_ TRCM_a566_AlgoWake_RCM_AWAKE_ROLL m9 : 29|1@1+ (1,0) [0|0] "" Vector__XXX
 SG_ TRCM_a626_loop25AsicStartupDiagnosticFailure m10 : 29|1@1+ (1,0) [0|0] "" Vector__XXX
 SG_ TRCM_a027_airbagAsicDeploymentDiagnosticFault m0 : 30|1@1+ (1,0) [0|0] "" Vector__XXX
 SG_ TRCM_a087_DIREL_MIA m1 : 30|1@1+ (1,0) [0|0] "" Vector__XXX
 SG_ TRCM_a147_frontCenterAccelElectricalIssue m2 : 30|1@1+ (1,0) [0|0] "" Vector__XXX
 SG_ TRCM_a207_rightCPillarAccelElectricalIssue m3 : 30|1@1+ (1,0) [0|0] "" Vector__XXX
 SG_ TRCM_a387_primaryAsicResetSource m6 : 30|1@1+ (1,0) [0|0] "" Vector__XXX
 SG_ TRCM_a447_seatbeltShoulderPretensionerFrontRightConfigError m7 : 30|1@1+ (1,0) [0|0] "" Vector__XXX
 SG_ TRCM_a567_AlgoWake_RCM_AWAKE_X m9 : 30|1@1+ (1,0) [0|0] "" Vector__XXX
 SG_ TRCM_a627_loop26AsicStartupDiagnosticFailure m10 : 30|1@1+ (1,0) [0|0] "" Vector__XXX
 SG_ TRCM_a088_DIRER_MIA m1 : 31|1@1+ (1,0) [0|0] "" Vector__XXX
 SG_ TRCM_a148_frontCenterAccelConfigError m2 : 31|1@1+ (1,0) [0|0] "" Vector__XXX
 SG_ TRCM_a208_rightCPillarAccelConfigError m3 : 31|1@1+ (1,0) [0|0] "" Vector__XXX
 SG_ TRCM_a388_cpuLoadHigh m6 : 31|1@1+ (1,0) [0|0] "" Vector__XXX
 SG_ TRCM_a448_seatbeltLapPretensionerFrontLeftConfigError m7 : 31|1@1+ (1,0) [0|0] "" Vector__XXX
 SG_ TRCM_a568_AlgoWake_RCM_AWAKE_Y m9 : 31|1@1+ (1,0) [0|0] "" Vector__XXX
 SG_ TRCM_a628_loop27AsicStartupDiagnosticFailure m10 : 31|1@1+ (1,0) [0|0] "" Vector__XXX
 SG_ TRCM_a089_IBST_MIA m1 : 32|1@1+ (1,0) [0|0] "" Vector__XXX
 SG_ TRCM_a149_frontCenterAccelSignalMonitor m2 : 32|1@1+ (1,0) [0|0] "" Vector__XXX
 SG_ TRCM_a209_rightCPillarAccelSignalMonitor m3 : 32|1@1+ (1,0) [0|0] "" Vector__XXX
 SG_ TRCM_a389_asicPwrStatusError m6 : 32|1@1+ (1,0) [0|0] "" Vector__XXX
 SG_ TRCM_a449_seatbeltLapPretensionerFrontRightConfigError m7 : 32|1@1+ (1,0) [0|0] "" Vector__XXX
 SG_ TRCM_a569_AlgoWake_PAS_WAKE_LEFT m9 : 32|1@1+ (1,0) [0|0] "" Vector__XXX
 SG_ TRCM_a629_loop28AsicStartupDiagnosticFailure m10 : 32|1@1+ (1,0) [0|0] "" Vector__XXX
 SG_ TRCM_a030_ECULogUploadRequest m0 : 33|1@1+ (1,0) [0|0] "" Vector__XXX
 SG_ TRCM_a090_APS_MIA m1 : 33|1@1+ (1,0) [0|0] "" Vector__XXX
 SG_ TRCM_a150_frontLeftAccelReportedError m2 : 33|1@1+ (1,0) [0|0] "" Vector__XXX
 SG_ TRCM_a390_systemAsicClockOrOperatingStateError m6 : 33|1@1+ (1,0) [0|0] "" Vector__XXX
 SG_ TRCM_a450_outboardSeatAirbagLeftConfigError m7 : 33|1@1+ (1,0) [0|0] "" Vector__XXX
 SG_ TRCM_a570_AlgoWake_PAS_WAKE_RIGHT m9 : 33|1@1+ (1,0) [0|0] "" Vector__XXX
 SG_ TRCM_a630_loop29AsicStartupDiagnosticFailure m10 : 33|1@1+ (1,0) [0|0] "" Vector__XXX
 SG_ TRCM_a031_UDSActive m0 : 34|1@1+ (1,0) [0|0] "" Vector__XXX
 SG_ TRCM_a091_CMPD_MIA m1 : 34|1@1+ (1,0) [0|0] "" Vector__XXX
 SG_ TRCM_a151_frontLeftAccelGeneralIssue m2 : 34|1@1+ (1,0) [0|0] "" Vector__XXX
 SG_ TRCM_a391_extAsic1ClockOrOperatingStateError m6 : 34|1@1+ (1,0) [0|0] "" Vector__XXX
 SG_ TRCM_a451_outboardSeatAirbagRightConfigError m7 : 34|1@1+ (1,0) [0|0] "" Vector__XXX
 SG_ TRCM_a631_loop30AsicStartupDiagnosticFailure m10 : 34|1@1+ (1,0) [0|0] "" Vector__XXX
 SG_ TRCM_a032_ScrollCreated m0 : 35|1@1+ (1,0) [0|0] "" Vector__XXX
 SG_ TRCM_a092_VCSEATD_MIA m1 : 35|1@1+ (1,0) [0|0] "" Vector__XXX
 SG_ TRCM_a152_frontLeftAccelElectricalIssue m2 : 35|1@1+ (1,0) [0|0] "" Vector__XXX
 SG_ TRCM_a272_asm5ComStatusError m4 : 35|1@1+ (1,0) [0|0] "" Vector__XXX
 SG_ TRCM_a332_driverAirbagStage1Deployed m5 : 35|1@1+ (1,0) [0|0] "" Vector__XXX
 SG_ TRCM_a392_extAsic2ClockOrOperatingStateError m6 : 35|1@1+ (1,0) [0|0] "" Vector__XXX
 SG_ TRCM_a452_hoodLifterLeftConfigError m7 : 35|1@1+ (1,0) [0|0] "" Vector__XXX
 SG_ TRCM_a632_loop31AsicStartupDiagnosticFailure m10 : 35|1@1+ (1,0) [0|0] "" Vector__XXX
 SG_ TRCM_a033_HercLogCreated m0 : 36|1@1+ (1,0) [0|0] "" Vector__XXX
 SG_ TRCM_a093_VCSEATP_MIA m1 : 36|1@1+ (1,0) [0|0] "" Vector__XXX
 SG_ TRCM_a153_frontLeftAccelConfigError m2 : 36|1@1+ (1,0) [0|0] "" Vector__XXX
 SG_ TRCM_a273_asm5ArsStatusXError m4 : 36|1@1+ (1,0) [0|0] "" Vector__XXX
 SG_ TRCM_a333_passengerAirbagStage1Deployed m5 : 36|1@1+ (1,0) [0|0] "" Vector__XXX
 SG_ TRCM_a393_depAdcConvertRatioError m6 : 36|1@1+ (1,0) [0|0] "" Vector__XXX
 SG_ TRCM_a453_hoodLifterRightConfigError m7 : 36|1@1+ (1,0) [0|0] "" Vector__XXX
 SG_ TRCM_a633_glacierInitialStatusFailure m10 : 36|1@1+ (1,0) [0|0] "" Vector__XXX
 SG_ TRCM_a034_apClipTrigger m0 : 37|1@1+ (1,0) [0|0] "" Vector__XXX
 SG_ TRCM_a094_EPAS3P_MIA m1 : 37|1@1+ (1,0) [0|0] "" Vector__XXX
 SG_ TRCM_a154_frontLeftAccelSignalMonitor m2 : 37|1@1+ (1,0) [0|0] "" Vector__XXX
 SG_ TRCM_a274_asm5ArsStatusZError m4 : 37|1@1+ (1,0) [0|0] "" Vector__XXX
 SG_ TRCM_a334_driverAirbagStage2Deployed m5 : 37|1@1+ (1,0) [0|0] "" Vector__XXX
 SG_ TRCM_a394_gspiGlobalStatusWordError m6 : 37|1@1+ (1,0) [0|0] "" Vector__XXX
 SG_ TRCM_a454_seatbeltShoulderPretensionerRearLeftConfigError m7 : 37|1@1+ (1,0) [0|0] "" Vector__XXX
 SG_ TRCM_a634_glacierTraceabilityReadoutA0A0Failure m10 : 37|1@1+ (1,0) [0|0] "" Vector__XXX
 SG_ TRCM_a035_hvDisconnectCommanded m0 : 38|1@1+ (1,0) [0|0] "" Vector__XXX
 SG_ TRCM_a095_CHG_MIA m1 : 38|1@1+ (1,0) [0|0] "" Vector__XXX
 SG_ TRCM_a155_frontLeftDoorPressureReportedError m2 : 38|1@1+ (1,0) [0|0] "" Vector__XXX
 SG_ TRCM_a275_asm5AccStatusError m4 : 38|1@1+ (1,0) [0|0] "" Vector__XXX
 SG_ TRCM_a335_driverAirbagActiveVentDeployed m5 : 38|1@1+ (1,0) [0|0] "" Vector__XXX
 SG_ TRCM_a395_imuUncalibrated m6 : 38|1@1+ (1,0) [0|0] "" Vector__XXX
 SG_ TRCM_a455_seatbeltShoulderPretensionerRearRightConfigError m7 : 38|1@1+ (1,0) [0|0] "" Vector__XXX
 SG_ TRCM_a635_glacierTraceabilityReadoutB0B0Failure m10 : 38|1@1+ (1,0) [0|0] "" Vector__XXX
 SG_ TRCM_a036_crashDetected m0 : 39|1@1+ (1,0) [0|0] "" Vector__XXX
 SG_ TRCM_a096_OCS1P_MIA m1 : 39|1@1+ (1,0) [0|0] "" Vector__XXX
 SG_ TRCM_a156_frontLeftDoorPressureGeneralIssue m2 : 39|1@1+ (1,0) [0|0] "" Vector__XXX
 SG_ TRCM_a276_watchdogStatus m4 : 39|1@1+ (1,0) [0|0] "" Vector__XXX
 SG_ TRCM_a336_passengerAirbagStage2Deployed m5 : 39|1@1+ (1,0) [0|0] "" Vector__XXX
 SG_ TRCM_a396_spiCommunicationProgramError m6 : 39|1@1+ (1,0) [0|0] "" Vector__XXX
 SG_ TRCM_a576_AlgoWake_IMPACT_FINISH_X m9 : 39|1@1+ (1,0) [0|0] "" Vector__XXX
 SG_ TRCM_a636_glacierRegisterPatternWriteFailure m10 : 39|1@1+ (1,0) [0|0] "" Vector__XXX
 SG_ TRCM_a037_nearDeploy m0 : 40|1@1+ (1,0) [0|0] "" Vector__XXX
 SG_ TRCM_a097_CMP_MIA m1 : 40|1@1+ (1,0) [0|0] "" Vector__XXX
 SG_ TRCM_a157_frontLeftDoorPressureElectricalIssue m2 : 40|1@1+ (1,0) [0|0] "" Vector__XXX
 SG_ TRCM_a337_passengerAirbagActiveVentDeployed m5 : 40|1@1+ (1,0) [0|0] "" Vector__XXX
 SG_ TRCM_a397_safingMonitorError m6 : 40|1@1+ (1,0) [0|0] "" Vector__XXX
 SG_ TRCM_a577_AlgoWake_IMPACT_FINISH_Y m9 : 40|1@1+ (1,0) [0|0] "" Vector__XXX
 SG_ TRCM_a637_glacierFixedPatternSelfTestFailure m10 : 40|1@1+ (1,0) [0|0] "" Vector__XXX
 SG_ TRCM_a038_ens1Degraded m0 : 41|1@1+ (1,0) [0|0] "" Vector__XXX
 SG_ TRCM_a098_DIR_MIA m1 : 41|1@1+ (1,0) [0|0] "" Vector__XXX
 SG_ TRCM_a158_frontLeftDoorPressureConfigError m2 : 41|1@1+ (1,0) [0|0] "" Vector__XXX
 SG_ TRCM_a278_safingEngine0Armed m4 : 41|1@1+ (1,0) [0|0] "" Vector__XXX
 SG_ TRCM_a398_asicNvmReprogrammed m6 : 41|1@1+ (1,0) [0|0] "" Vector__XXX
 SG_ TRCM_a578_AlgoWake_IMPACT_FINISH_ROLL m9 : 41|1@1+ (1,0) [0|0] "" Vector__XXX
 SG_ TRCM_a638_glacierSelfTestEFailure m10 : 41|1@1+ (1,0) [0|0] "" Vector__XXX
 SG_ TRCM_a039_ens2Degraded m0 : 42|1@1+ (1,0) [0|0] "" Vector__XXX
 SG_ TRCM_a099_PARK_MIA m1 : 42|1@1+ (1,0) [0|0] "" Vector__XXX
 SG_ TRCM_a159_frontLeftDoorPressureSignalMonitor m2 : 42|1@1+ (1,0) [0|0] "" Vector__XXX
 SG_ TRCM_a279_safingEngine1Armed m4 : 42|1@1+ (1,0) [0|0] "" Vector__XXX
 SG_ TRCM_a579_AlgoWake_RCM_ENABLED_X m9 : 42|1@1+ (1,0) [0|0] "" Vector__XXX
 SG_ TRCM_a639_glacierSelfTestFFailure m10 : 42|1@1+ (1,0) [0|0] "" Vector__XXX
 SG_ TRCM_a040_task500usOverrunDebug m0 : 43|1@1+ (1,0) [0|0] "" Vector__XXX
 SG_ TRCM_a100_CANbus_MIA m1 : 43|1@1+ (1,0) [0|0] "" Vector__XXX
 SG_ TRCM_a160_frontRightAccelReportedError m2 : 43|1@1+ (1,0) [0|0] "" Vector__XXX
 SG_ TRCM_a280_safingEngine2Armed m4 : 43|1@1+ (1,0) [0|0] "" Vector__XXX
 SG_ TRCM_a340_kneeAirbagLeftDeployed m5 : 43|1@1+ (1,0) [0|0] "" Vector__XXX
 SG_ TRCM_a400_driverAirbagStage1Issue m6 : 43|1@1+ (1,0) [0|0] "" Vector__XXX
 SG_ TRCM_a580_AlgoWake_RCM_ENABLED_Y m9 : 43|1@1+ (1,0) [0|0] "" Vector__XXX
 SG_ TRCM_a640_glacierAnalogSelfTestFailure m10 : 43|1@1+ (1,0) [0|0] "" Vector__XXX
 SG_ TRCM_a041_HighCPULoad m0 : 44|1@1+ (1,0) [0|0] "" Vector__XXX
 SG_ TRCM_a101_PM_MIA m1 : 44|1@1+ (1,0) [0|0] "" Vector__XXX
 SG_ TRCM_a161_frontRightAccelGeneralIssue m2 : 44|1@1+ (1,0) [0|0] "" Vector__XXX
 SG_ TRCM_a281_safingEngine3Armed m4 : 44|1@1+ (1,0) [0|0] "" Vector__XXX
 SG_ TRCM_a341_kneeAirbagRightDeployed m5 : 44|1@1+ (1,0) [0|0] "" Vector__XXX
 SG_ TRCM_a401_passengerAirbagStage1Issue m6 : 44|1@1+ (1,0) [0|0] "" Vector__XXX
 SG_ TRCM_a581_AlgoWake_RCM_ENABLED_ROLL m9 : 44|1@1+ (1,0) [0|0] "" Vector__XXX
 SG_ TRCM_a641_glacierOscillatorVerificationFailure m10 : 44|1@1+ (1,0) [0|0] "" Vector__XXX
 SG_ TRCM_a042_HighStackUsage m0 : 45|1@1+ (1,0) [0|0] "" Vector__XXX
 SG_ TRCM_a102_PTC_MIA m1 : 45|1@1+ (1,0) [0|0] "" Vector__XXX
 SG_ TRCM_a162_frontRightAccelElectricalIssue m2 : 45|1@1+ (1,0) [0|0] "" Vector__XXX
 SG_ TRCM_a282_safingEngine4Armed m4 : 45|1@1+ (1,0) [0|0] "" Vector__XXX
 SG_ TRCM_a342_curtainAirbagLeftDeployed m5 : 45|1@1+ (1,0) [0|0] "" Vector__XXX
 SG_ TRCM_a402_driverAirbagStage2Issue m6 : 45|1@1+ (1,0) [0|0] "" Vector__XXX
 SG_ TRCM_a582_AlgoWake_RCM_AWAKE m9 : 45|1@1+ (1,0) [0|0] "" Vector__XXX
 SG_ TRCM_a642_glacierFinalStatusFailure m10 : 45|1@1+ (1,0) [0|0] "" Vector__XXX
 SG_ TRCM_a043_Task1msError m0 : 46|1@1+ (1,0) [0|0] "" Vector__XXX
 SG_ TRCM_a103_CP_MIA m1 : 46|1@1+ (1,0) [0|0] "" Vector__XXX
 SG_ TRCM_a163_frontRightAccelConfigError m2 : 46|1@1+ (1,0) [0|0] "" Vector__XXX
 SG_ TRCM_a283_safingEngine5Armed m4 : 46|1@1+ (1,0) [0|0] "" Vector__XXX
 SG_ TRCM_a343_curtainAirbagRightDeployed m5 : 46|1@1+ (1,0) [0|0] "" Vector__XXX
 SG_ TRCM_a403_driverAirbagActiveVentIssue m6 : 46|1@1+ (1,0) [0|0] "" Vector__XXX
 SG_ TRCM_a643_glacierOffsetVerificationFailure m10 : 46|1@1+ (1,0) [0|0] "" Vector__XXX
 SG_ TRCM_a044_Task10msError m0 : 47|1@1+ (1,0) [0|0] "" Vector__XXX
 SG_ TRCM_a104_DAS_MIA m1 : 47|1@1+ (1,0) [0|0] "" Vector__XXX
 SG_ TRCM_a164_frontRightAccelSignalMonitor m2 : 47|1@1+ (1,0) [0|0] "" Vector__XXX
 SG_ TRCM_a284_safingEngine6Armed m4 : 47|1@1+ (1,0) [0|0] "" Vector__XXX
 SG_ TRCM_a344_seatbeltLoadLimiterFrontLeftDeployed m5 : 47|1@1+ (1,0) [0|0] "" Vector__XXX
 SG_ TRCM_a404_passengerAirbagStage2Issue m6 : 47|1@1+ (1,0) [0|0] "" Vector__XXX
 SG_ TRCM_a644_glacierNormalOperationFailure m10 : 47|1@1+ (1,0) [0|0] "" Vector__XXX
 SG_ TRCM_a045_Task100msError m0 : 48|1@1+ (1,0) [0|0] "" Vector__XXX
 SG_ TRCM_a105_TAS_MIA m1 : 48|1@1+ (1,0) [0|0] "" Vector__XXX
 SG_ TRCM_a165_frontRightDoorPressureReportedError m2 : 48|1@1+ (1,0) [0|0] "" Vector__XXX
 SG_ TRCM_a285_safingEngine7Armed m4 : 48|1@1+ (1,0) [0|0] "" Vector__XXX
 SG_ TRCM_a345_seatbeltLoadLimiterFrontRightDeployed m5 : 48|1@1+ (1,0) [0|0] "" Vector__XXX
 SG_ TRCM_a405_passengerAirbagActiveVentIssue m6 : 48|1@1+ (1,0) [0|0] "" Vector__XXX
 SG_ TRCM_a645_glacierDeviceReset m10 : 48|1@1+ (1,0) [0|0] "" Vector__XXX
 SG_ TRCM_a046_Task1000msError m0 : 49|1@1+ (1,0) [0|0] "" Vector__XXX
 SG_ TRCM_a106_PCS_MIA m1 : 49|1@1+ (1,0) [0|0] "" Vector__XXX
 SG_ TRCM_a166_frontRightDoorPressureGeneralIssue m2 : 49|1@1+ (1,0) [0|0] "" Vector__XXX
 SG_ TRCM_a286_safingEngine8Armed m4 : 49|1@1+ (1,0) [0|0] "" Vector__XXX
 SG_ TRCM_a346_seatbeltShoulderPretensionerFrontLeftDeployed m5 : 49|1@1+ (1,0) [0|0] "" Vector__XXX
 SG_ TRCM_a646_glacierDeviceFaulted m10 : 49|1@1+ (1,0) [0|0] "" Vector__XXX
 SG_ TRCM_a047_vinNotLearned m0 : 50|1@1+ (1,0) [0|0] "" Vector__XXX
 SG_ TRCM_a107_BMS_MIA m1 : 50|1@1+ (1,0) [0|0] "" Vector__XXX
 SG_ TRCM_a167_frontRightDoorPressureElectricalIssue m2 : 50|1@1+ (1,0) [0|0] "" Vector__XXX
 SG_ TRCM_a287_safingEngine9Armed m4 : 50|1@1+ (1,0) [0|0] "" Vector__XXX
 SG_ TRCM_a347_seatbeltShoulderPretensionerFrontRightDeployed m5 : 50|1@1+ (1,0) [0|0] "" Vector__XXX
 SG_ TRCM_a048_vinMismatch m0 : 51|1@1+ (1,0) [0|0] "" Vector__XXX
 SG_ TRCM_a108_DIF_MIA m1 : 51|1@1+ (1,0) [0|0] "" Vector__XXX
 SG_ TRCM_a168_frontRightDoorPressureConfigError m2 : 51|1@1+ (1,0) [0|0] "" Vector__XXX
 SG_ TRCM_a288_safingEngine10Armed m4 : 51|1@1+ (1,0) [0|0] "" Vector__XXX
 SG_ TRCM_a348_seatbeltLapPretensionerFrontLeftDeployed m5 : 51|1@1+ (1,0) [0|0] "" Vector__XXX
 SG_ TRCM_a408_kneeAirbagLeftIssue m6 : 51|1@1+ (1,0) [0|0] "" Vector__XXX
 SG_ TRCM_a588_yawRateOffsetPosLimit m9 : 51|1@1+ (1,0) [0|0] "" Vector__XXX
 SG_ TRCM_a049_nvmDebugInfo m0 : 52|1@1+ (1,0) [0|0] "" Vector__XXX
 SG_ TRCM_a109_RCM_MIA m1 : 52|1@1+ (1,0) [0|0] "" Vector__XXX
 SG_ TRCM_a169_frontRightDoorPressureSignalMonitor m2 : 52|1@1+ (1,0) [0|0] "" Vector__XXX
 SG_ TRCM_a289_safingEngine11Armed m4 : 52|1@1+ (1,0) [0|0] "" Vector__XXX
 SG_ TRCM_a349_seatbeltLapPretensionerFrontRightDeployed m5 : 52|1@1+ (1,0) [0|0] "" Vector__XXX
 SG_ TRCM_a409_kneeAirbagRightIssue m6 : 52|1@1+ (1,0) [0|0] "" Vector__XXX
 SG_ TRCM_a589_yawRateOffsetNegLimit m9 : 52|1@1+ (1,0) [0|0] "" Vector__XXX
 SG_ TRCM_a110_GTW_MIA m1 : 53|1@1+ (1,0) [0|0] "" Vector__XXX
 SG_ TRCM_a170_leftBPillarAccelReportedError m2 : 53|1@1+ (1,0) [0|0] "" Vector__XXX
 SG_ TRCM_a290_safingEngine12Armed m4 : 53|1@1+ (1,0) [0|0] "" Vector__XXX
 SG_ TRCM_a350_outboardSeatAirbagLeftDeployed m5 : 53|1@1+ (1,0) [0|0] "" Vector__XXX
 SG_ TRCM_a410_curtainAirbagLeftIssue m6 : 53|1@1+ (1,0) [0|0] "" Vector__XXX
 SG_ TRCM_a590_pitchRateOffsetPosLimit m9 : 53|1@1+ (1,0) [0|0] "" Vector__XXX
 SG_ TRCM_a051_systemSelfTestTimeout m0 : 54|1@1+ (1,0) [0|0] "" Vector__XXX
 SG_ TRCM_a111_EPBR_MIA m1 : 54|1@1+ (1,0) [0|0] "" Vector__XXX
 SG_ TRCM_a171_leftBPillarAccelGeneralIssue m2 : 54|1@1+ (1,0) [0|0] "" Vector__XXX
 SG_ TRCM_a291_safingEngine13Armed m4 : 54|1@1+ (1,0) [0|0] "" Vector__XXX
 SG_ TRCM_a351_outboardSeatAirbagRightDeployed m5 : 54|1@1+ (1,0) [0|0] "" Vector__XXX
 SG_ TRCM_a411_curtainAirbagRightIssue m6 : 54|1@1+ (1,0) [0|0] "" Vector__XXX
 SG_ TRCM_a591_pitchRateOffsetNegLimit m9 : 54|1@1+ (1,0) [0|0] "" Vector__XXX
 SG_ TRCM_a112_EPBL_MIA m1 : 55|1@1+ (1,0) [0|0] "" Vector__XXX
 SG_ TRCM_a172_leftBPillarAccelElectricalIssue m2 : 55|1@1+ (1,0) [0|0] "" Vector__XXX
 SG_ TRCM_a292_safingEngine14Armed m4 : 55|1@1+ (1,0) [0|0] "" Vector__XXX
 SG_ TRCM_a352_hoodLifterLeftDeployed m5 : 55|1@1+ (1,0) [0|0] "" Vector__XXX
 SG_ TRCM_a412_seatbeltLoadLimiterFrontLeftIssue m6 : 55|1@1+ (1,0) [0|0] "" Vector__XXX
 SG_ TRCM_a592_rollRateOffsetPosLimit m9 : 55|1@1+ (1,0) [0|0] "" Vector__XXX
 SG_ TRCM_a113_UI_MIA m1 : 56|1@1+ (1,0) [0|0] "" Vector__XXX
 SG_ TRCM_a173_leftBPillarAccelConfigError m2 : 56|1@1+ (1,0) [0|0] "" Vector__XXX
 SG_ TRCM_a293_safingEngine15Armed m4 : 56|1@1+ (1,0) [0|0] "" Vector__XXX
 SG_ TRCM_a353_hoodLifterRightDeployed m5 : 56|1@1+ (1,0) [0|0] "" Vector__XXX
 SG_ TRCM_a413_seatbeltLoadLimiterFrontRightIssue m6 : 56|1@1+ (1,0) [0|0] "" Vector__XXX
 SG_ TRCM_a593_rollRateOffsetNegLimit m9 : 56|1@1+ (1,0) [0|0] "" Vector__XXX
 SG_ TRCM_a114_ESP_MIA m1 : 57|1@1+ (1,0) [0|0] "" Vector__XXX
 SG_ TRCM_a174_leftBPillarAccelSignalMonitor m2 : 57|1@1+ (1,0) [0|0] "" Vector__XXX
 SG_ TRCM_a294_safingEngine16Armed m4 : 57|1@1+ (1,0) [0|0] "" Vector__XXX
 SG_ TRCM_a354_seatbeltShoulderPretensionerRearLeftDeployed m5 : 57|1@1+ (1,0) [0|0] "" Vector__XXX
 SG_ TRCM_a414_seatbeltShoulderPretensionerFrontLeftIssue m6 : 57|1@1+ (1,0) [0|0] "" Vector__XXX
 SG_ TRCM_a594_longitudinalAccelOffsetPosLimit m9 : 57|1@1+ (1,0) [0|0] "" Vector__XXX
 SG_ TRCM_a115_VCSEC_MIA m1 : 58|1@1+ (1,0) [0|0] "" Vector__XXX
 SG_ TRCM_a175_leftCPillarAccelReportedError m2 : 58|1@1+ (1,0) [0|0] "" Vector__XXX
 SG_ TRCM_a295_safingEngine17Armed m4 : 58|1@1+ (1,0) [0|0] "" Vector__XXX
 SG_ TRCM_a355_seatbeltShoulderPretensionerRearRightDeployed m5 : 58|1@1+ (1,0) [0|0] "" Vector__XXX
 SG_ TRCM_a415_seatbeltShoulderPretensionerFrontRightIssue m6 : 58|1@1+ (1,0) [0|0] "" Vector__XXX
 SG_ TRCM_a595_longitudinalAccelOffsetNegLimit m9 : 58|1@1+ (1,0) [0|0] "" Vector__XXX
 SG_ TRCM_a116_VCRIGHT_MIA m1 : 59|1@1+ (1,0) [0|0] "" Vector__XXX
 SG_ TRCM_a176_leftCPillarAccelGeneralIssue m2 : 59|1@1+ (1,0) [0|0] "" Vector__XXX
 SG_ TRCM_a296_safingEngine18Armed m4 : 59|1@1+ (1,0) [0|0] "" Vector__XXX
 SG_ TRCM_a416_seatbeltLapPretensionerFrontLeftIssue m6 : 59|1@1+ (1,0) [0|0] "" Vector__XXX
 SG_ TRCM_a596_lateralAccelOffsetPosLimit m9 : 59|1@1+ (1,0) [0|0] "" Vector__XXX
 SG_ TRCM_a057_HVP_MIA m0 : 60|1@1+ (1,0) [0|0] "" Vector__XXX
 SG_ TRCM_a117_VCLEFT_MIA m1 : 60|1@1+ (1,0) [0|0] "" Vector__XXX
 SG_ TRCM_a177_leftCPillarAccelElectricalIssue m2 : 60|1@1+ (1,0) [0|0] "" Vector__XXX
 SG_ TRCM_a297_safingEngine19Armed m4 : 60|1@1+ (1,0) [0|0] "" Vector__XXX
 SG_ TRCM_a417_seatbeltLapPretensionerFrontRightIssue m6 : 60|1@1+ (1,0) [0|0] "" Vector__XXX
 SG_ TRCM_a597_lateralAccelOffsetNegLimit m9 : 60|1@1+ (1,0) [0|0] "" Vector__XXX
 SG_ TRCM_a058_inputRHighSyncDebug m0 : 61|1@1+ (1,0) [0|0] "" Vector__XXX
 SG_ TRCM_a118_VCFRONT_MIA m1 : 61|1@1+ (1,0) [0|0] "" Vector__XXX
 SG_ TRCM_a178_leftCPillarAccelConfigError m2 : 61|1@1+ (1,0) [0|0] "" Vector__XXX
 SG_ TRCM_a298_safingEngine20Armed m4 : 61|1@1+ (1,0) [0|0] "" Vector__XXX
 SG_ TRCM_a418_outboardSeatAirbagLeftIssue m6 : 61|1@1+ (1,0) [0|0] "" Vector__XXX
 SG_ TRCM_a598_verticalAccelOffsetPosLimit m9 : 61|1@1+ (1,0) [0|0] "" Vector__XXX
 SG_ TRCM_a059_inputResistanceHigh m0 : 62|1@1+ (1,0) [0|0] "" Vector__XXX
 SG_ TRCM_a119_SCCM_MIA m1 : 62|1@1+ (1,0) [0|0] "" Vector__XXX
 SG_ TRCM_a179_leftCPillarAccelSignalMonitor m2 : 62|1@1+ (1,0) [0|0] "" Vector__XXX
 SG_ TRCM_a299_safingEngine21Armed m4 : 62|1@1+ (1,0) [0|0] "" Vector__XXX
 SG_ TRCM_a419_outboardSeatAirbagRightIssue m6 : 62|1@1+ (1,0) [0|0] "" Vector__XXX
 SG_ TRCM_a599_verticalAccelOffsetNegLimit m9 : 62|1@1+ (1,0) [0|0] "" Vector__XXX
 SG_ TRCM_a060_engineeringBuild m0 : 63|1@1+ (1,0) [0|0] "" Vector__XXX
 SG_ TRCM_a120_DI_DRIVE_MIA m1 : 63|1@1+ (1,0) [0|0] "" Vector__XXX
 SG_ TRCM_a300_driverAirbagStage1Suppressed m4 : 63|1@1+ (1,0) [0|0] "" Vector__XXX
 SG_ TRCM_a420_hoodLifterLeftIssue m6 : 63|1@1+ (1,0) [0|0] "" Vector__XXX
 SG_ TRCM_a600_airbagAsicStartupFailure m9 : 63|1@1+ (1,0) [0|0] "" Vector__XXX

BO_ 890 DAS_telemetryPeriodic: 8 Vector__XXX
 SG_ DAS_TP_multiplexer M : 0|5@1+ (1,0) [0|0] "" Vector__XXX
 SG_ DAS_TP_bdlCounter m6 : 5|3@1+ (1,0) [0|0] "" Vector__XXX
 SG_ DAS_TP_bdrCounter m7 : 5|3@1+ (1,0) [0|0] "" Vector__XXX
 SG_ DAS_TP_counter m0 : 5|3@1+ (1,0) [0|0] "" Vector__XXX
 SG_ DAS_TP_hppCounter m3 : 5|3@1+ (1,0) [0|0] "" Vector__XXX
 SG_ DAS_TP_laneCounter m8 : 5|3@1+ (1,0) [0|0] "" Vector__XXX
 SG_ DAS_TP_llCounter m1 : 5|3@1+ (1,0) [0|0] "" Vector__XXX
 SG_ DAS_TP_llrCounter m9 : 5|3@1+ (1,0) [0|0] "" Vector__XXX
 SG_ DAS_TP_navCounter m4 : 5|3@1+ (1,0) [0|0] "" Vector__XXX
 SG_ DAS_TP_rlCounter m2 : 5|3@1+ (1,0) [0|0] "" Vector__XXX
 SG_ DAS_TP_vlCounter m5 : 5|3@1+ (1,0) [0|0] "" Vector__XXX
 SG_ DAS_TP_bdlC0 m6 : 8|10@1- (0.02,0) [0|0] "" Vector__XXX
 SG_ DAS_TP_bdrC0 m7 : 8|10@1- (0.02,0) [0|0] "" Vector__XXX
 SG_ DAS_TP_hppC0 m3 : 8|10@1- (0.02,0) [0|0] "" Vector__XXX
 SG_ DAS_TP_llC0 m1 : 8|10@1- (0.02,0) [0|0] "" Vector__XXX
 SG_ DAS_TP_llSegQ1 m8 : 8|4@1+ (10,0) [0|0] "" Vector__XXX
 SG_ DAS_TP_navC0 m4 : 8|10@1- (0.02,0) [0|0] "" Vector__XXX
 SG_ DAS_TP_numLanes m9 : 8|3@1+ (1,0) [0|0] "" Vector__XXX
 SG_ DAS_TP_rlC0 m2 : 8|10@1- (0.02,0) [0|0] "" Vector__XXX
 SG_ DAS_TP_vlC0 m5 : 8|10@1- (0.02,0) [0|0] "" Vector__XXX
 SG_ DAS_TP_vlWidth m0 : 8|8@1+ (0.05,0) [0|0] "" Vector__XXX
 SG_ DAS_TP_lane1LLR m9 : 11|6@1+ (0.3125,-10) [0|0] "" Vector__XXX
 SG_ DAS_TP_llSegQ2 m8 : 12|4@1+ (10,0) [0|0] "" Vector__XXX
 SG_ DAS_TP_hppError m0 : 16|6@1+ (0.05,0) [0|0] "" Vector__XXX
 SG_ DAS_TP_llSegQ3 m8 : 16|4@1+ (10,0) [0|0] "" Vector__XXX
 SG_ DAS_TP_lane2LLR m9 : 17|6@1+ (0.3125,-10) [0|0] "" Vector__XXX
 SG_ DAS_TP_bdlC1 m6 : 18|9@1- (0.001953125,0) [0|0] "" Vector__XXX
 SG_ DAS_TP_bdrC1 m7 : 18|9@1- (0.001953125,0) [0|0] "" Vector__XXX
 SG_ DAS_TP_hppC1 m3 : 18|9@1- (0.001953125,0) [0|0] "" Vector__XXX
 SG_ DAS_TP_llC1 m1 : 18|9@1- (0.001953125,0) [0|0] "" Vector__XXX
 SG_ DAS_TP_navC1 m4 : 18|9@1- (0.001953125,0) [0|0] "" Vector__XXX
 SG_ DAS_TP_rlC1 m2 : 18|9@1- (0.001953125,0) [0|0] "" Vector__XXX
 SG_ DAS_TP_vlC1 m5 : 18|9@1- (0.001953125,0) [0|0] "" Vector__XXX
 SG_ DAS_TP_llSegQ4 m8 : 20|4@1+ (10,0) [0|0] "" Vector__XXX
 SG_ DAS_TP_wipersActive m0 : 22|1@1+ (1,0) [0|0] "" Vector__XXX
 SG_ DAS_TP_handsOn m0 : 23|1@1+ (1,0) [0|0] "" Vector__XXX
 SG_ DAS_TP_lane3LLR m9 : 23|6@1+ (0.3125,-10) [0|0] "" Vector__XXX
 SG_ DAS_TP_rlSegQ1 m8 : 24|4@1+ (10,0) [0|0] "" Vector__XXX
 SG_ DAS_TP_sonicDistL m0 : 24|9@1+ (0.01,0) [0|0] "" Vector__XXX
 SG_ DAS_TP_bdlC2 m6 : 27|14@1- (4e-06,0) [0|0] "" Vector__XXX
 SG_ DAS_TP_bdrC2 m7 : 27|14@1- (4e-06,0) [0|0] "" Vector__XXX
 SG_ DAS_TP_hppC2 m3 : 27|14@1- (4e-06,0) [0|0] "" Vector__XXX
 SG_ DAS_TP_llC2 m1 : 27|14@1- (4e-06,0) [0|0] "" Vector__XXX
 SG_ DAS_TP_navC2 m4 : 27|14@1- (4e-06,0) [0|0] "" Vector__XXX
 SG_ DAS_TP_rlC2 m2 : 27|14@1- (4e-06,0) [0|0] "" Vector__XXX
 SG_ DAS_TP_vlC2 m5 : 27|14@1- (4e-06,0) [0|0] "" Vector__XXX
 SG_ DAS_TP_rlSegQ2 m8 : 28|4@1+ (10,0) [0|0] "" Vector__XXX
 SG_ DAS_TP_lane4LLR m9 : 29|6@1+ (0.3125,-10) [0|0] "" Vector__XXX
 SG_ DAS_TP_rlSegQ3 m8 : 32|4@1+ (10,0) [0|0] "" Vector__XXX
 SG_ DAS_TP_sonicDistR m0 : 33|9@1+ (0.01,0) [0|0] "" Vector__XXX
 SG_ DAS_TP_lane5LLR m9 : 35|6@1+ (0.3125,-10) [0|0] "" Vector__XXX
 SG_ DAS_TP_rlSegQ4 m8 : 36|4@1+ (10,0) [0|0] "" Vector__XXX
 SG_ DAS_TP_llExist m8 : 40|4@1+ (10,0) [0|0] "" Vector__XXX
 SG_ DAS_TP_bdlC3 m6 : 41|14@1- (1.6e-08,0) [0|0] "" Vector__XXX
 SG_ DAS_TP_bdrC3 m7 : 41|14@1- (1.6e-08,0) [0|0] "" Vector__XXX
 SG_ DAS_TP_hppC3 m3 : 41|14@1- (1.6e-08,0) [0|0] "" Vector__XXX
 SG_ DAS_TP_lane6LLR m9 : 41|6@1+ (0.3125,-10) [0|0] "" Vector__XXX
 SG_ DAS_TP_llC3 m1 : 41|14@1- (1.6e-08,0) [0|0] "" Vector__XXX
 SG_ DAS_TP_navC3 m4 : 41|14@1- (1.6e-08,0) [0|0] "" Vector__XXX
 SG_ DAS_TP_rlC3 m2 : 41|14@1- (1.6e-08,0) [0|0] "" Vector__XXX
 SG_ DAS_TP_vlC3 m5 : 41|14@1- (1.6e-08,0) [0|0] "" Vector__XXX
 SG_ DAS_TP_hppValid m0 : 42|1@1+ (1,0) [0|0] "" Vector__XXX
 SG_ DAS_TP_restrictedAccess m0 : 43|1@1+ (1,0) [0|0] "" Vector__XXX
 SG_ DAS_TP_rlExist m8 : 44|4@1+ (10,0) [0|0] "" Vector__XXX
 SG_ DAS_TP_vehFuse m0 : 44|1@1+ (1,0) [0|0] "" Vector__XXX
 SG_ DAS_TP_accRestricted m0 : 46|1@1+ (1,0) [0|0] "" Vector__XXX
 SG_ DAS_TP_lane7LLR m9 : 47|6@1+ (0.3125,-10) [0|0] "" Vector__XXX
 SG_ DAS_TP_laneChange m0 : 48|2@1+ (1,0) [0|0] "" Vector__XXX
 SG_ DAS_TP_nllProb m8 : 48|4@1+ (0.1,0) [0|0] "" Vector__XXX
 SG_ DAS_TP_llType m0 : 50|3@1+ (1,0) [0|0] "" Vector__XXX
 SG_ DAS_TP_nrlProb m8 : 52|4@1+ (0.1,0) [0|0] "" Vector__XXX
 SG_ DAS_TP_lane8LLR m9 : 53|6@1+ (0.3125,-10) [0|0] "" Vector__XXX
 SG_ DAS_TP_rlType m0 : 53|3@1+ (1,0) [0|0] "" Vector__XXX
 SG_ DAS_TP_bdlQlty m6 : 55|1@1+ (1,0) [0|0] "" Vector__XXX
 SG_ DAS_TP_bdrQlty m7 : 55|1@1+ (1,0) [0|0] "" Vector__XXX
 SG_ DAS_TP_hppQlty m3 : 55|1@1+ (1,0) [0|0] "" Vector__XXX
 SG_ DAS_TP_llQlty m1 : 55|1@1+ (1,0) [0|0] "" Vector__XXX
 SG_ DAS_TP_navQlty m4 : 55|1@1+ (1,0) [0|0] "" Vector__XXX
 SG_ DAS_TP_rlQlty m2 : 55|1@1+ (1,0) [0|0] "" Vector__XXX
 SG_ DAS_TP_vlQlty m5 : 55|1@1+ (1,0) [0|0] "" Vector__XXX
 SG_ DAS_TP_bdlRange m6 : 56|7@1+ (1,0) [0|0] "" Vector__XXX
 SG_ DAS_TP_bdrRange m7 : 56|7@1+ (1,0) [0|0] "" Vector__XXX
 SG_ DAS_TP_hppRange m3 : 56|7@1+ (1,0) [0|0] "" Vector__XXX
 SG_ DAS_TP_llQltyME m8 : 56|2@1+ (1,0) [0|0] "" Vector__XXX
 SG_ DAS_TP_llRange m1 : 56|7@1+ (1,0) [0|0] "" Vector__XXX
 SG_ DAS_TP_navRange m4 : 56|7@1+ (1,0) [0|0] "" Vector__XXX
 SG_ DAS_TP_plannerState m0 : 56|4@1+ (1,0) [0|0] "" Vector__XXX
 SG_ DAS_TP_rlRange m2 : 56|7@1+ (1,0) [0|0] "" Vector__XXX
 SG_ DAS_TP_vlRange m5 : 56|7@1+ (1,0) [0|0] "" Vector__XXX
 SG_ DAS_TP_rlQltyME m8 : 58|2@1+ (1,0) [0|0] "" Vector__XXX
 SG_ DAS_TP_egoLane m9 : 59|3@1+ (1,0) [0|0] "" Vector__XXX
 SG_ DAS_TP_bdlQltyME m8 : 60|2@1+ (1,0) [0|0] "" Vector__XXX
 SG_ DAS_TP_lcState m0 : 60|4@1+ (1,0) [0|0] "" Vector__XXX
 SG_ DAS_TP_bdrQltyME m8 : 62|2@1+ (1,0) [0|0] "" Vector__XXX
 SG_ DAS_TP_bdlFuse m6 : 63|1@1+ (1,0) [0|0] "" Vector__XXX
 SG_ DAS_TP_bdrFuse m7 : 63|1@1+ (1,0) [0|0] "" Vector__XXX
 SG_ DAS_TP_hppFuse m3 : 63|1@1+ (1,0) [0|0] "" Vector__XXX
 SG_ DAS_TP_llFuse m1 : 63|1@1+ (1,0) [0|0] "" Vector__XXX
 SG_ DAS_TP_navFuse m4 : 63|1@1+ (1,0) [0|0] "" Vector__XXX
 SG_ DAS_TP_rlFuse m2 : 63|1@1+ (1,0) [0|0] "" Vector__XXX
 SG_ DAS_TP_vlFuse m5 : 63|1@1+ (1,0) [0|0] "" Vector__XXX

BO_ 894 PARK_warningMatrix: 8 Vector__XXX
 SG_ PARK_matrixIndex M : 0|4@1+ (1,0) [0|0] "" Vector__XXX
 SG_ PARK_a001_s1_overTemp m0 : 4|1@1+ (1,0) [0|0] "" Vector__XXX
 SG_ PARK_a061_ecuUnderVoltage m1 : 4|1@1+ (1,0) [0|0] "" Vector__XXX
 SG_ PARK_a002_s1_internalFail m0 : 5|1@1+ (1,0) [0|0] "" Vector__XXX
 SG_ PARK_a062_ecuOverVoltage m1 : 5|1@1+ (1,0) [0|0] "" Vector__XXX
 SG_ PARK_a003_s1_linCommError m0 : 6|1@1+ (1,0) [0|0] "" Vector__XXX
 SG_ PARK_a063_sensorVoltage m1 : 6|1@1+ (1,0) [0|0] "" Vector__XXX
 SG_ PARK_a004_s1_blocked m0 : 7|1@1+ (1,0) [0|0] "" Vector__XXX
 SG_ PARK_a064_ecuFault m1 : 7|1@1+ (1,0) [0|0] "" Vector__XXX
 SG_ PARK_a005_s1_crossTalk m0 : 8|1@1+ (1,0) [0|0] "" Vector__XXX
 SG_ PARK_a065_crcFault m1 : 8|1@1+ (1,0) [0|0] "" Vector__XXX
 SG_ PARK_a006_s2_overTemp m0 : 9|1@1+ (1,0) [0|0] "" Vector__XXX
 SG_ PARK_a066_calibrationMissing m1 : 9|1@1+ (1,0) [0|0] "" Vector__XXX
 SG_ PARK_a007_s2_internalFail m0 : 10|1@1+ (1,0) [0|0] "" Vector__XXX
 SG_ PARK_a067_privateCANBusOff m1 : 10|1@1+ (1,0) [0|0] "" Vector__XXX
 SG_ PARK_a008_s2_linCommError m0 : 11|1@1+ (1,0) [0|0] "" Vector__XXX
 SG_ PARK_a068_hardwareWatchDog m1 : 11|1@1+ (1,0) [0|0] "" Vector__XXX
 SG_ PARK_a009_s2_blocked m0 : 12|1@1+ (1,0) [0|0] "" Vector__XXX
 SG_ PARK_a069_dasMia m1 : 12|1@1+ (1,0) [0|0] "" Vector__XXX
 SG_ PARK_a010_s2_crossTalk m0 : 13|1@1+ (1,0) [0|0] "" Vector__XXX
 SG_ PARK_a070_sccmMia m1 : 13|1@1+ (1,0) [0|0] "" Vector__XXX
 SG_ PARK_a011_s3_overTemp m0 : 14|1@1+ (1,0) [0|0] "" Vector__XXX
 SG_ PARK_a071_diMia m1 : 14|1@1+ (1,0) [0|0] "" Vector__XXX
 SG_ PARK_a012_s3_internalFail m0 : 15|1@1+ (1,0) [0|0] "" Vector__XXX
 SG_ PARK_a072_epasMia m1 : 15|1@1+ (1,0) [0|0] "" Vector__XXX
 SG_ PARK_a013_s3_linCommError m0 : 16|1@1+ (1,0) [0|0] "" Vector__XXX
 SG_ PARK_a073_epbMia m1 : 16|1@1+ (1,0) [0|0] "" Vector__XXX
 SG_ PARK_a014_s3_blocked m0 : 17|1@1+ (1,0) [0|0] "" Vector__XXX
 SG_ PARK_a074_espMia m1 : 17|1@1+ (1,0) [0|0] "" Vector__XXX
 SG_ PARK_a015_s3_crossTalk m0 : 18|1@1+ (1,0) [0|0] "" Vector__XXX
 SG_ PARK_a075_rcmMia m1 : 18|1@1+ (1,0) [0|0] "" Vector__XXX
 SG_ PARK_a016_s4_overTemp m0 : 19|1@1+ (1,0) [0|0] "" Vector__XXX
 SG_ PARK_a076_vcFrontMia m1 : 19|1@1+ (1,0) [0|0] "" Vector__XXX
 SG_ PARK_a017_s4_internalFail m0 : 20|1@1+ (1,0) [0|0] "" Vector__XXX
 SG_ PARK_a077_dasError m1 : 20|1@1+ (1,0) [0|0] "" Vector__XXX
 SG_ PARK_a018_s4_linCommError m0 : 21|1@1+ (1,0) [0|0] "" Vector__XXX
 SG_ PARK_a078_diError m1 : 21|1@1+ (1,0) [0|0] "" Vector__XXX
 SG_ PARK_a019_s4_blocked m0 : 22|1@1+ (1,0) [0|0] "" Vector__XXX
 SG_ PARK_a079_epasError m1 : 22|1@1+ (1,0) [0|0] "" Vector__XXX
 SG_ PARK_a020_s4_crossTalk m0 : 23|1@1+ (1,0) [0|0] "" Vector__XXX
 SG_ PARK_a080_epbError m1 : 23|1@1+ (1,0) [0|0] "" Vector__XXX
 SG_ PARK_a021_s5_overTemp m0 : 24|1@1+ (1,0) [0|0] "" Vector__XXX
 SG_ PARK_a081_espError m1 : 24|1@1+ (1,0) [0|0] "" Vector__XXX
 SG_ PARK_a022_s5_internalFail m0 : 25|1@1+ (1,0) [0|0] "" Vector__XXX
 SG_ PARK_a082_rcmError m1 : 25|1@1+ (1,0) [0|0] "" Vector__XXX
 SG_ PARK_a023_s5_linCommError m0 : 26|1@1+ (1,0) [0|0] "" Vector__XXX
 SG_ PARK_a083_vcFrontError m1 : 26|1@1+ (1,0) [0|0] "" Vector__XXX
 SG_ PARK_a024_s5_blocked m0 : 27|1@1+ (1,0) [0|0] "" Vector__XXX
 SG_ PARK_a084_sccmError m1 : 27|1@1+ (1,0) [0|0] "" Vector__XXX
 SG_ PARK_a025_s5_crossTalk m0 : 28|1@1+ (1,0) [0|0] "" Vector__XXX
 SG_ PARK_a085_watchdogReset m1 : 28|1@1+ (1,0) [0|0] "" Vector__XXX
 SG_ PARK_a026_s6_overTemp m0 : 29|1@1+ (1,0) [0|0] "" Vector__XXX
 SG_ PARK_a086_nvmFault m1 : 29|1@1+ (1,0) [0|0] "" Vector__XXX
 SG_ PARK_a027_s6_internalFail m0 : 30|1@1+ (1,0) [0|0] "" Vector__XXX
 SG_ PARK_a087_sensorMismatchError m1 : 30|1@1+ (1,0) [0|0] "" Vector__XXX
 SG_ PARK_a028_s6_linCommError m0 : 31|1@1+ (1,0) [0|0] "" Vector__XXX
 SG_ PARK_a029_s6_blocked m0 : 32|1@1+ (1,0) [0|0] "" Vector__XXX
 SG_ PARK_a030_s6_crossTalk m0 : 33|1@1+ (1,0) [0|0] "" Vector__XXX
 SG_ PARK_a031_s7_overTemp m0 : 34|1@1+ (1,0) [0|0] "" Vector__XXX
 SG_ PARK_a032_s7_internalFail m0 : 35|1@1+ (1,0) [0|0] "" Vector__XXX
 SG_ PARK_a033_s7_linCommError m0 : 36|1@1+ (1,0) [0|0] "" Vector__XXX
 SG_ PARK_a034_s7_blocked m0 : 37|1@1+ (1,0) [0|0] "" Vector__XXX
 SG_ PARK_a035_s7_crossTalk m0 : 38|1@1+ (1,0) [0|0] "" Vector__XXX
 SG_ PARK_a036_s8_overTemp m0 : 39|1@1+ (1,0) [0|0] "" Vector__XXX
 SG_ PARK_a037_s8_internalFail m0 : 40|1@1+ (1,0) [0|0] "" Vector__XXX
 SG_ PARK_a038_s8_linCommError m0 : 41|1@1+ (1,0) [0|0] "" Vector__XXX
 SG_ PARK_a039_s8_blocked m0 : 42|1@1+ (1,0) [0|0] "" Vector__XXX
 SG_ PARK_a040_s8_crossTalk m0 : 43|1@1+ (1,0) [0|0] "" Vector__XXX
 SG_ PARK_a041_s9_overTemp m0 : 44|1@1+ (1,0) [0|0] "" Vector__XXX
 SG_ PARK_a042_s9_internalFail m0 : 45|1@1+ (1,0) [0|0] "" Vector__XXX
 SG_ PARK_a043_s9_linCommError m0 : 46|1@1+ (1,0) [0|0] "" Vector__XXX
 SG_ PARK_a044_s9_blocked m0 : 47|1@1+ (1,0) [0|0] "" Vector__XXX
 SG_ PARK_a045_s9_crossTalk m0 : 48|1@1+ (1,0) [0|0] "" Vector__XXX
 SG_ PARK_a046_s10_overTemp m0 : 49|1@1+ (1,0) [0|0] "" Vector__XXX
 SG_ PARK_a047_s10_internalFail m0 : 50|1@1+ (1,0) [0|0] "" Vector__XXX
 SG_ PARK_a048_s10_linCommError m0 : 51|1@1+ (1,0) [0|0] "" Vector__XXX
 SG_ PARK_a049_s10_blocked m0 : 52|1@1+ (1,0) [0|0] "" Vector__XXX
 SG_ PARK_a050_s10_crossTalk m0 : 53|1@1+ (1,0) [0|0] "" Vector__XXX
 SG_ PARK_a051_s11_overTemp m0 : 54|1@1+ (1,0) [0|0] "" Vector__XXX
 SG_ PARK_a052_s11_internalFail m0 : 55|1@1+ (1,0) [0|0] "" Vector__XXX
 SG_ PARK_a053_s11_linCommError m0 : 56|1@1+ (1,0) [0|0] "" Vector__XXX
 SG_ PARK_a054_s11_blocked m0 : 57|1@1+ (1,0) [0|0] "" Vector__XXX
 SG_ PARK_a055_s11_crossTalk m0 : 58|1@1+ (1,0) [0|0] "" Vector__XXX
 SG_ PARK_a056_s12_overTemp m0 : 59|1@1+ (1,0) [0|0] "" Vector__XXX
 SG_ PARK_a057_s12_internalFail m0 : 60|1@1+ (1,0) [0|0] "" Vector__XXX
 SG_ PARK_a058_s12_linCommError m0 : 61|1@1+ (1,0) [0|0] "" Vector__XXX
 SG_ PARK_a059_s12_blocked m0 : 62|1@1+ (1,0) [0|0] "" Vector__XXX
 SG_ PARK_a060_s12_crossTalk m0 : 63|1@1+ (1,0) [0|0] "" Vector__XXX

BO_ 895 TPMS_debugC: 8 Vector__XXX
 SG_ TPMS_debugResponse : 0|64@1+ (1,0) [0|0] "" Vector__XXX

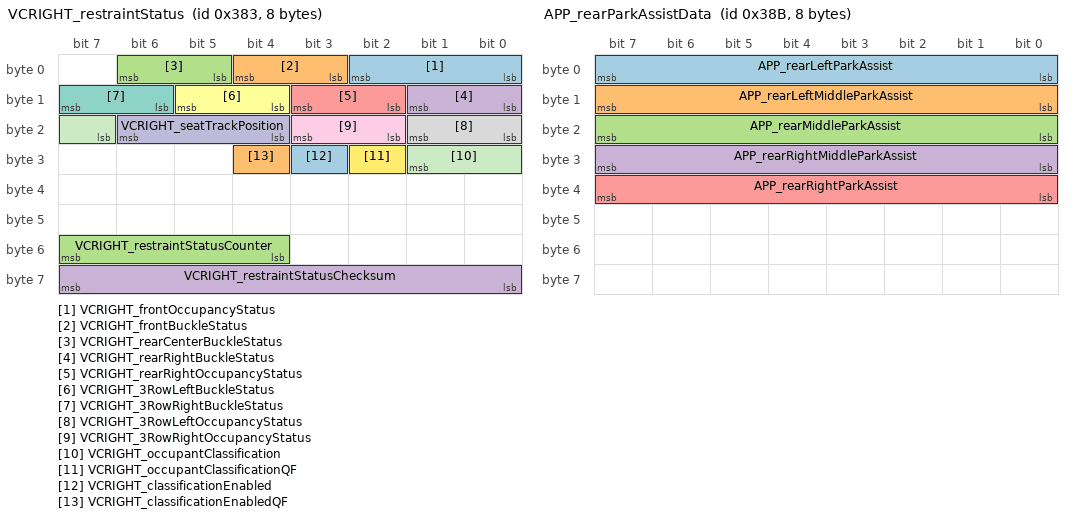
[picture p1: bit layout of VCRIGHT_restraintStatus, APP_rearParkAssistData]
BO_ 899 VCRIGHT_restraintStatus: 8 Vector__XXX
 SG_ VCRIGHT_frontOccupancyStatus : 0|3@1+ (1,0) [0|0] "" Vector__XXX
 SG_ VCRIGHT_frontBuckleStatus : 3|2@1+ (1,0) [0|0] "" Vector__XXX
 SG_ VCRIGHT_rearCenterBuckleStatus : 5|2@1+ (1,0) [0|0] "" Vector__XXX
 SG_ VCRIGHT_rearRightBuckleStatus : 8|2@1+ (1,0) [0|0] "" Vector__XXX
 SG_ VCRIGHT_rearRightOccupancyStatus : 10|2@1+ (1,0) [0|0] "" Vector__XXX
 SG_ VCRIGHT_3RowLeftBuckleStatus : 12|2@1+ (1,0) [0|0] "" Vector__XXX
 SG_ VCRIGHT_3RowRightBuckleStatus : 14|2@1+ (1,0) [0|0] "" Vector__XXX
 SG_ VCRIGHT_3RowLeftOccupancyStatus : 16|2@1+ (1,0) [0|0] "" Vector__XXX
 SG_ VCRIGHT_3RowRightOccupancyStatus : 18|2@1+ (1,0) [0|0] "" Vector__XXX
 SG_ VCRIGHT_seatTrackPosition : 20|3@1+ (1,0) [0|0] "" Vector__XXX
 SG_ VCRIGHT_occupantClassification : 23|3@1+ (1,0) [0|0] "" Vector__XXX
 SG_ VCRIGHT_occupantClassificationQF : 26|1@1+ (1,0) [0|0] "" Vector__XXX
 SG_ VCRIGHT_classificationEnabled : 27|1@1+ (1,0) [0|0] "" Vector__XXX
 SG_ VCRIGHT_classificationEnabledQF : 28|1@1+ (1,0) [0|0] "" Vector__XXX
 SG_ VCRIGHT_restraintStatusCounter : 52|4@1+ (1,0) [0|0] "" Vector__XXX
 SG_ VCRIGHT_restraintStatusChecksum : 56|8@1+ (1,0) [0|0] "" Vector__XXX

BO_ 905 DAS_status2: 8 Vector__XXX
 SG_ DAS_accSpeedLimit : 0|9@1+ (0.4,0) [0|0] "" Vector__XXX
 SG_ DAS_versionIdentifier : 9|1@1+ (1,0) [0|0] "" Vector__XXX
 SG_ DAS_pmmObstacleSeverity : 10|3@1+ (1,0) [0|0] "" Vector__XXX
 SG_ DAS_pmmLoggingRequest : 13|1@1+ (1,0) [0|0] "" Vector__XXX
 SG_ DAS_activationFailureStatus : 14|2@1+ (1,0) [0|0] "" Vector__XXX
 SG_ DAS_pmmUltrasonicsFaultReason : 16|3@1+ (1,0) [0|0] "" Vector__XXX
 SG_ DAS_pmmRadarFaultReason : 19|2@1+ (1,0) [0|0] "" Vector__XXX
 SG_ DAS_pmmSysFaultReason : 21|3@1+ (1,0) [0|0] "" Vector__XXX
 SG_ DAS_pmmCameraFaultReason : 24|2@1+ (1,0) [0|0] "" Vector__XXX
 SG_ DAS_ACC_report : 26|5@1+ (1,0) [0|0] "" Vector__XXX
 SG_ DAS_relaxCruiseLimits : 31|1@1+ (1,0) [0|0] "" Vector__XXX
 SG_ DAS_csaState : 32|2@1+ (1,0) [0|0] "" Vector__XXX
 SG_ DAS_radarTelemetry : 34|2@1+ (1,0) [0|0] "" Vector__XXX
 SG_ DAS_robState : 36|2@1+ (1,0) [0|0] "" Vector__XXX
 SG_ DAS_driverInteractionLevel : 38|2@1+ (1,0) [0|0] "" Vector__XXX
 SG_ DAS_ppOffsetDesiredRamp : 40|8@1+ (0.01,-1.28) [0|0] "" Vector__XXX
 SG_ DAS_longCollisionWarning : 48|4@1+ (1,0) [0|0] "" Vector__XXX
 SG_ DAS_status2Counter : 52|4@1+ (1,0) [0|0] "" Vector__XXX
 SG_ DAS_status2Checksum : 56|8@1+ (1,0) [0|0] "" Vector__XXX

BO_ 907 APP_rearParkAssistData: 8 Vector__XXX
 SG_ APP_rearLeftParkAssist : 0|8@1+ (1,0) [0|0] "" Vector__XXX
 SG_ APP_rearLeftMiddleParkAssist : 8|8@1+ (1,0) [0|0] "" Vector__XXX
 SG_ APP_rearMiddleParkAssist : 16|8@1+ (1,0) [0|0] "" Vector__XXX
 SG_ APP_rearRightMiddleParkAssist : 24|8@1+ (1,0) [0|0] "" Vector__XXX
 SG_ APP_rearRightParkAssist : 32|8@1+ (1,0) [0|0] "" Vector__XXX

BO_ 913 EPAS3S_alertMatrix: 8 Vector__XXX
 SG_ EPAS3S_matrixIndex M : 0|4@1+ (1,0) [0|0] "" Vector__XXX
 SG_ EPAS3S_a001_sent1Mia m0 : 4|1@1+ (1,0) [0|0] "" Vector__XXX
 SG_ EPAS3S_a061_bridgeUv m1 : 4|1@1+ (1,0) [0|0] "" Vector__XXX
 SG_ EPAS3S_a121_pvtEcuStatCrcError m2 : 4|1@1+ (1,0) [0|0] "" Vector__XXX
 SG_ EPAS3S_a002_sent1Error m0 : 5|1@1+ (1,0) [0|0] "" Vector__XXX
 SG_ EPAS3S_a062_assistCorrError m1 : 5|1@1+ (1,0) [0|0] "" Vector__XXX
 SG_ EPAS3S_a122_olpActive m2 : 5|1@1+ (1,0) [0|0] "" Vector__XXX
 SG_ EPAS3S_a003_trqSens1Supply m0 : 6|1@1+ (1,0) [0|0] "" Vector__XXX
 SG_ EPAS3S_a063_dampCorrError m1 : 6|1@1+ (1,0) [0|0] "" Vector__XXX
 SG_ EPAS3S_a123_combEcu2StatFail m2 : 6|1@1+ (1,0) [0|0] "" Vector__XXX
 SG_ EPAS3S_a004_trqSens1Eeprom m0 : 7|1@1+ (1,0) [0|0] "" Vector__XXX
 SG_ EPAS3S_a064_phaseCompCorrError m1 : 7|1@1+ (1,0) [0|0] "" Vector__XXX
 SG_ EPAS3S_a124_tempSensStuckInRange m2 : 7|1@1+ (1,0) [0|0] "" Vector__XXX
 SG_ EPAS3S_a005_sent2Mia m0 : 8|1@1+ (1,0) [0|0] "" Vector__XXX
 SG_ EPAS3S_a065_trqTarCorrError m1 : 8|1@1+ (1,0) [0|0] "" Vector__XXX
 SG_ EPAS3S_a125_trqSensTrimOutRange m2 : 8|1@1+ (1,0) [0|0] "" Vector__XXX
 SG_ EPAS3S_a006_sent2Error m0 : 9|1@1+ (1,0) [0|0] "" Vector__XXX
 SG_ EPAS3S_a066_returnCorrError m1 : 9|1@1+ (1,0) [0|0] "" Vector__XXX
 SG_ EPAS3S_a126_apsMia m2 : 9|1@1+ (1,0) [0|0] "" Vector__XXX
 SG_ EPAS3S_a007_trqSens2Supply m0 : 10|1@1+ (1,0) [0|0] "" Vector__XXX
 SG_ EPAS3S_a067_yawDampCorrError m1 : 10|1@1+ (1,0) [0|0] "" Vector__XXX
 SG_ EPAS3S_a127_apsCntError m2 : 10|1@1+ (1,0) [0|0] "" Vector__XXX
 SG_ EPAS3S_a008_trqSens2Eeprom m0 : 11|1@1+ (1,0) [0|0] "" Vector__XXX
 SG_ EPAS3S_a068_hystCorrError m1 : 11|1@1+ (1,0) [0|0] "" Vector__XXX
 SG_ EPAS3S_a128_apsCsError m2 : 11|1@1+ (1,0) [0|0] "" Vector__XXX
 SG_ EPAS3S_a009_sentDiff m0 : 12|1@1+ (1,0) [0|0] "" Vector__XXX
 SG_ EPAS3S_a069_eacCorrError m1 : 12|1@1+ (1,0) [0|0] "" Vector__XXX
 SG_ EPAS3S_a129_combEcu1StatFail m2 : 12|1@1+ (1,0) [0|0] "" Vector__XXX
 SG_ EPAS3S_a010_trqSensCalError m0 : 13|1@1+ (1,0) [0|0] "" Vector__XXX
 SG_ EPAS3S_a070_hodCorrError m1 : 13|1@1+ (1,0) [0|0] "" Vector__XXX
 SG_ EPAS3S_a130_sasOffsetNotCal m2 : 13|1@1+ (1,0) [0|0] "" Vector__XXX
 SG_ EPAS3S_a011_currentSensError m0 : 14|1@1+ (1,0) [0|0] "" Vector__XXX
 SG_ EPAS3S_a071_vehSpdCorrError m1 : 14|1@1+ (1,0) [0|0] "" Vector__XXX
 SG_ EPAS3S_a131_phaseFeedbackError m2 : 14|1@1+ (1,0) [0|0] "" Vector__XXX
 SG_ EPAS3S_a012_currentSensCalError m0 : 15|1@1+ (1,0) [0|0] "" Vector__XXX
 SG_ EPAS3S_a072_motFeedFwdError m1 : 15|1@1+ (1,0) [0|0] "" Vector__XXX
 SG_ EPAS3S_a132_motFeedFwdCounter25 m2 : 15|1@1+ (1,0) [0|0] "" Vector__XXX
 SG_ EPAS3S_a013_gateDriveError m0 : 16|1@1+ (1,0) [0|0] "" Vector__XXX
 SG_ EPAS3S_a073_motParEstError m1 : 16|1@1+ (1,0) [0|0] "" Vector__XXX
 SG_ EPAS3S_a133_motFeedFwdCounter50 m2 : 16|1@1+ (1,0) [0|0] "" Vector__XXX
 SG_ EPAS3S_a014_gateDriveTxError m0 : 17|1@1+ (1,0) [0|0] "" Vector__XXX
 SG_ EPAS3S_a074_overHeatProtect m1 : 17|1@1+ (1,0) [0|0] "" Vector__XXX
 SG_ EPAS3S_a134_motFeedFwdCounter85 m2 : 17|1@1+ (1,0) [0|0] "" Vector__XXX
 SG_ EPAS3S_a015_gateDriveEeprom m0 : 18|1@1+ (1,0) [0|0] "" Vector__XXX
 SG_ EPAS3S_a075_fspPwrCut m1 : 18|1@1+ (1,0) [0|0] "" Vector__XXX
 SG_ EPAS3S_a135_piCtrlCounter25 m2 : 18|1@1+ (1,0) [0|0] "" Vector__XXX
 SG_ EPAS3S_a016_phaseUhighUv m0 : 19|1@1+ (1,0) [0|0] "" Vector__XXX
 SG_ EPAS3S_a076_tempSensOutofRange m1 : 19|1@1+ (1,0) [0|0] "" Vector__XXX
 SG_ EPAS3S_a136_piCtrlCounter50 m2 : 19|1@1+ (1,0) [0|0] "" Vector__XXX
 SG_ EPAS3S_a017_phaseUlowUv m0 : 20|1@1+ (1,0) [0|0] "" Vector__XXX
 SG_ EPAS3S_a077_highSideFetError m1 : 20|1@1+ (1,0) [0|0] "" Vector__XXX
 SG_ EPAS3S_a137_piCtrlCounter85 m2 : 20|1@1+ (1,0) [0|0] "" Vector__XXX
 SG_ EPAS3S_a018_phaseVhighUv m0 : 21|1@1+ (1,0) [0|0] "" Vector__XXX
 SG_ EPAS3S_a078_phaseDisconnectError m1 : 21|1@1+ (1,0) [0|0] "" Vector__XXX
 SG_ EPAS3S_a144_diSpdMia m2 : 21|1@1+ (1,0) [0|0] "" Vector__XXX
 SG_ EPAS3S_a019_phaseVlowUv m0 : 22|1@1+ (1,0) [0|0] "" Vector__XXX
 SG_ EPAS3S_a079_backupCurrentPlaus m1 : 22|1@1+ (1,0) [0|0] "" Vector__XXX
 SG_ EPAS3S_a145_diSpdCntError m2 : 22|1@1+ (1,0) [0|0] "" Vector__XXX
 SG_ EPAS3S_a020_phaseWhighUv m0 : 23|1@1+ (1,0) [0|0] "" Vector__XXX
 SG_ EPAS3S_a080_ecuInitArbError m1 : 23|1@1+ (1,0) [0|0] "" Vector__XXX
 SG_ EPAS3S_a146_diSpdCsError m2 : 23|1@1+ (1,0) [0|0] "" Vector__XXX
 SG_ EPAS3S_a021_phaseWlowUv m0 : 24|1@1+ (1,0) [0|0] "" Vector__XXX
 SG_ EPAS3S_a081_coggCompError m1 : 24|1@1+ (1,0) [0|0] "" Vector__XXX
 SG_ EPAS3S_a147_backupVehSpeed m2 : 24|1@1+ (1,0) [0|0] "" Vector__XXX
 SG_ EPAS3S_a022_phaseUhighOv m0 : 25|1@1+ (1,0) [0|0] "" Vector__XXX
 SG_ EPAS3S_a082_polarityCalError m1 : 25|1@1+ (1,0) [0|0] "" Vector__XXX
 SG_ EPAS3S_a148_vMaxAssist m2 : 25|1@1+ (1,0) [0|0] "" Vector__XXX
 SG_ EPAS3S_a023_phaseUlowOv m0 : 26|1@1+ (1,0) [0|0] "" Vector__XXX
 SG_ EPAS3S_a083_crcMismatch m1 : 26|1@1+ (1,0) [0|0] "" Vector__XXX
 SG_ EPAS3S_a149_currentSensPathSwitch m2 : 26|1@1+ (1,0) [0|0] "" Vector__XXX
 SG_ EPAS3S_a024_phaseVhighOv m0 : 27|1@1+ (1,0) [0|0] "" Vector__XXX
 SG_ EPAS3S_a084_eacCancelled m1 : 27|1@1+ (1,0) [0|0] "" Vector__XXX
 SG_ EPAS3S_a150_currentSensOffsetDetect m2 : 27|1@1+ (1,0) [0|0] "" Vector__XXX
 SG_ EPAS3S_a025_phaseVlowOv m0 : 28|1@1+ (1,0) [0|0] "" Vector__XXX
 SG_ EPAS3S_a085_canBusOff m1 : 28|1@1+ (1,0) [0|0] "" Vector__XXX
 SG_ EPAS3S_a151_dcsCboot m2 : 28|1@1+ (1,0) [0|0] "" Vector__XXX
 SG_ EPAS3S_a026_phaseWhighOv m0 : 29|1@1+ (1,0) [0|0] "" Vector__XXX
 SG_ EPAS3S_a086_dasMia m1 : 29|1@1+ (1,0) [0|0] "" Vector__XXX
 SG_ EPAS3S_a152_dcsDiagReg m2 : 29|1@1+ (1,0) [0|0] "" Vector__XXX
 SG_ EPAS3S_a027_phaseWlowOv m0 : 30|1@1+ (1,0) [0|0] "" Vector__XXX
 SG_ EPAS3S_a087_dasCntError m1 : 30|1@1+ (1,0) [0|0] "" Vector__XXX
 SG_ EPAS3S_a153_dcsInitOffset m2 : 30|1@1+ (1,0) [0|0] "" Vector__XXX
 SG_ EPAS3S_a028_phaseUbootUv m0 : 31|1@1+ (1,0) [0|0] "" Vector__XXX
 SG_ EPAS3S_a088_dasCsError m1 : 31|1@1+ (1,0) [0|0] "" Vector__XXX
 SG_ EPAS3S_a154_assistTorqueDisabled m2 : 31|1@1+ (1,0) [0|0] "" Vector__XXX
 SG_ EPAS3S_a029_phaseVbootUv m0 : 32|1@1+ (1,0) [0|0] "" Vector__XXX
 SG_ EPAS3S_a089_espWsMia m1 : 32|1@1+ (1,0) [0|0] "" Vector__XXX
 SG_ EPAS3S_a155_backupEacActive m2 : 32|1@1+ (1,0) [0|0] "" Vector__XXX
 SG_ EPAS3S_a030_phaseWbootUv m0 : 33|1@1+ (1,0) [0|0] "" Vector__XXX
 SG_ EPAS3S_a090_espWsCntError m1 : 33|1@1+ (1,0) [0|0] "" Vector__XXX
 SG_ EPAS3S_a156_angleSensorDivergence m2 : 33|1@1+ (1,0) [0|0] "" Vector__XXX
 SG_ EPAS3S_a031_abnormalShutdown m0 : 34|1@1+ (1,0) [0|0] "" Vector__XXX
 SG_ EPAS3S_a091_espWsCsError m1 : 34|1@1+ (1,0) [0|0] "" Vector__XXX
 SG_ EPAS3S_a032_vRegOutputUv m0 : 35|1@1+ (1,0) [0|0] "" Vector__XXX
 SG_ EPAS3S_a092_espWrMia m1 : 35|1@1+ (1,0) [0|0] "" Vector__XXX
 SG_ EPAS3S_a033_vRegOutputOv m0 : 36|1@1+ (1,0) [0|0] "" Vector__XXX
 SG_ EPAS3S_a093_espWrCntError m1 : 36|1@1+ (1,0) [0|0] "" Vector__XXX
 SG_ EPAS3S_a034_vRegError m0 : 37|1@1+ (1,0) [0|0] "" Vector__XXX
 SG_ EPAS3S_a094_espWrCsError m1 : 37|1@1+ (1,0) [0|0] "" Vector__XXX
 SG_ EPAS3S_a035_vbbSupplyUv m0 : 38|1@1+ (1,0) [0|0] "" Vector__XXX
 SG_ EPAS3S_a095_espWsStatus m1 : 38|1@1+ (1,0) [0|0] "" Vector__XXX
 SG_ EPAS3S_a036_vbbSupplyOv m0 : 39|1@1+ (1,0) [0|0] "" Vector__XXX
 SG_ EPAS3S_a096_rcmMia m1 : 39|1@1+ (1,0) [0|0] "" Vector__XXX
 SG_ EPAS3S_a037_motPos1ParityError m0 : 40|1@1+ (1,0) [0|0] "" Vector__XXX
 SG_ EPAS3S_a097_rcmCntError m1 : 40|1@1+ (1,0) [0|0] "" Vector__XXX
 SG_ EPAS3S_a038_motPos1Uv m0 : 41|1@1+ (1,0) [0|0] "" Vector__XXX
 SG_ EPAS3S_a098_rcmCsError m1 : 41|1@1+ (1,0) [0|0] "" Vector__XXX
 SG_ EPAS3S_a039_motPos1MagnetMia m0 : 42|1@1+ (1,0) [0|0] "" Vector__XXX
 SG_ EPAS3S_a099_yawRateStatus m1 : 42|1@1+ (1,0) [0|0] "" Vector__XXX
 SG_ EPAS3S_a040_motPos1LogicError m0 : 43|1@1+ (1,0) [0|0] "" Vector__XXX
 SG_ EPAS3S_a100_diMia m1 : 43|1@1+ (1,0) [0|0] "" Vector__XXX
 SG_ EPAS3S_a041_motPos1tempError m0 : 44|1@1+ (1,0) [0|0] "" Vector__XXX
 SG_ EPAS3S_a101_diCntError m1 : 44|1@1+ (1,0) [0|0] "" Vector__XXX
 SG_ EPAS3S_a042_motPos2ParityError m0 : 45|1@1+ (1,0) [0|0] "" Vector__XXX
 SG_ EPAS3S_a102_diCsError m1 : 45|1@1+ (1,0) [0|0] "" Vector__XXX
 SG_ EPAS3S_a043_motPos2Uv m0 : 46|1@1+ (1,0) [0|0] "" Vector__XXX
 SG_ EPAS3S_a103_vcFrontMia m1 : 46|1@1+ (1,0) [0|0] "" Vector__XXX
 SG_ EPAS3S_a044_motPos2MagnetMia m0 : 47|1@1+ (1,0) [0|0] "" Vector__XXX
 SG_ EPAS3S_a104_vcFrontCntError m1 : 47|1@1+ (1,0) [0|0] "" Vector__XXX
 SG_ EPAS3S_a045_motPos2LogicError m0 : 48|1@1+ (1,0) [0|0] "" Vector__XXX
 SG_ EPAS3S_a105_vcFrontCsError m1 : 48|1@1+ (1,0) [0|0] "" Vector__XXX
 SG_ EPAS3S_a046_motPos2tempError m0 : 49|1@1+ (1,0) [0|0] "" Vector__XXX
 SG_ EPAS3S_a106_vcFrontTempMia m1 : 49|1@1+ (1,0) [0|0] "" Vector__XXX
 SG_ EPAS3S_a047_motPosCorrError m0 : 50|1@1+ (1,0) [0|0] "" Vector__XXX
 SG_ EPAS3S_a107_uiTuneReqMia m1 : 50|1@1+ (1,0) [0|0] "" Vector__XXX
 SG_ EPAS3S_a048_motPosCalError m0 : 51|1@1+ (1,0) [0|0] "" Vector__XXX
 SG_ EPAS3S_a108_uiTuneReqCntError m1 : 51|1@1+ (1,0) [0|0] "" Vector__XXX
 SG_ EPAS3S_a049_piCtrlError m0 : 52|1@1+ (1,0) [0|0] "" Vector__XXX
 SG_ EPAS3S_a109_uiTuneReqCsError m1 : 52|1@1+ (1,0) [0|0] "" Vector__XXX
 SG_ EPAS3S_a050_mcuSmuError m0 : 53|1@1+ (1,0) [0|0] "" Vector__XXX
 SG_ EPAS3S_a110_sasMia m1 : 53|1@1+ (1,0) [0|0] "" Vector__XXX
 SG_ EPAS3S_a051_mcuSupError m0 : 54|1@1+ (1,0) [0|0] "" Vector__XXX
 SG_ EPAS3S_a111_sasCntError m1 : 54|1@1+ (1,0) [0|0] "" Vector__XXX
 SG_ EPAS3S_a052_intWatchdogError m0 : 55|1@1+ (1,0) [0|0] "" Vector__XXX
 SG_ EPAS3S_a112_sasCsError m1 : 55|1@1+ (1,0) [0|0] "" Vector__XXX
 SG_ EPAS3S_a053_extWatchdogError m0 : 56|1@1+ (1,0) [0|0] "" Vector__XXX
 SG_ EPAS3S_a113_sasStatusError m1 : 56|1@1+ (1,0) [0|0] "" Vector__XXX
 SG_ EPAS3S_a054_memoryProtectError m0 : 57|1@1+ (1,0) [0|0] "" Vector__XXX
 SG_ EPAS3S_a114_gtwConfigMia m1 : 57|1@1+ (1,0) [0|0] "" Vector__XXX
 SG_ EPAS3S_a055_floatPointError m0 : 58|1@1+ (1,0) [0|0] "" Vector__XXX
 SG_ EPAS3S_a115_ecuStatMia m1 : 58|1@1+ (1,0) [0|0] "" Vector__XXX
 SG_ EPAS3S_a056_battUv m0 : 59|1@1+ (1,0) [0|0] "" Vector__XXX
 SG_ EPAS3S_a116_ecuStatCntError m1 : 59|1@1+ (1,0) [0|0] "" Vector__XXX
 SG_ EPAS3S_a057_battUvReduced m0 : 60|1@1+ (1,0) [0|0] "" Vector__XXX
 SG_ EPAS3S_a117_ecuStatCrcError m1 : 60|1@1+ (1,0) [0|0] "" Vector__XXX
 SG_ EPAS3S_a058_battOv m0 : 61|1@1+ (1,0) [0|0] "" Vector__XXX
 SG_ EPAS3S_a118_privateBusOff m1 : 61|1@1+ (1,0) [0|0] "" Vector__XXX
 SG_ EPAS3S_a059_battOvReduced m0 : 62|1@1+ (1,0) [0|0] "" Vector__XXX
 SG_ EPAS3S_a119_pvtEcuStatMia m1 : 62|1@1+ (1,0) [0|0] "" Vector__XXX
 SG_ EPAS3S_a060_battBridgeDiff m0 : 63|1@1+ (1,0) [0|0] "" Vector__XXX
 SG_ EPAS3S_a120_pvtEcuStatCntError m1 : 63|1@1+ (1,0) [0|0] "" Vector__XXX

BO_ 917 OCS1P_alertMatrix: 8 Vector__XXX
 SG_ OCS1P_matrixIndex M : 0|4@1+ (1,0) [0|0] "" Vector__XXX
 SG_ OCS1P_w121_sandwichOpen m2 : 4|1@1+ (1,0) [0|0] "" Vector__XXX
 SG_ OCS1P_w122_sandwichLow m2 : 5|1@1+ (1,0) [0|0] "" Vector__XXX
 SG_ OCS1P_w123_sandwichShort m2 : 6|1@1+ (1,0) [0|0] "" Vector__XXX
 SG_ OCS1P_w124_cushionSelfOpen m2 : 7|1@1+ (1,0) [0|0] "" Vector__XXX
 SG_ OCS1P_w125_cushionSelfLow m2 : 8|1@1+ (1,0) [0|0] "" Vector__XXX
 SG_ OCS1P_w126_cushionSelfShort m2 : 9|1@1+ (1,0) [0|0] "" Vector__XXX
 SG_ OCS1P_w127_seatbackSelfOpen m2 : 10|1@1+ (1,0) [0|0] "" Vector__XXX
 SG_ OCS1P_w128_seatbackSelfLow m2 : 11|1@1+ (1,0) [0|0] "" Vector__XXX
 SG_ OCS1P_w129_seatbackSelfShort m2 : 12|1@1+ (1,0) [0|0] "" Vector__XXX
 SG_ OCS1P_w130_sandwichNoCalib m2 : 13|1@1+ (1,0) [0|0] "" Vector__XXX
 SG_ OCS1P_w131_cushionSelfNoCalib m2 : 14|1@1+ (1,0) [0|0] "" Vector__XXX
 SG_ OCS1P_w132_seatbackSelfNoCalib m2 : 15|1@1+ (1,0) [0|0] "" Vector__XXX
 SG_ OCS1P_w133_sandwichBadCalib m2 : 16|1@1+ (1,0) [0|0] "" Vector__XXX
 SG_ OCS1P_w134_uninitializedCalib m2 : 17|1@1+ (1,0) [0|0] "" Vector__XXX
 SG_ OCS1P_w015_NVMMAlert m0 : 18|1@1+ (1,0) [0|0] "" Vector__XXX
 SG_ OCS1P_w135_tempNoCalib m2 : 18|1@1+ (1,0) [0|0] "" Vector__XXX
 SG_ OCS1P_w136_cushionSelfDutyLow m2 : 19|1@1+ (1,0) [0|0] "" Vector__XXX
 SG_ OCS1P_w137_cushionSelfDutyHigh m2 : 20|1@1+ (1,0) [0|0] "" Vector__XXX
 SG_ OCS1P_w138_seatbackSelfDutyLow m2 : 21|1@1+ (1,0) [0|0] "" Vector__XXX
 SG_ OCS1P_w139_seatbackSelfDutyHigh m2 : 22|1@1+ (1,0) [0|0] "" Vector__XXX
 SG_ OCS1P_w140_tempInvalidCalib m2 : 23|1@1+ (1,0) [0|0] "" Vector__XXX
 SG_ OCS1P_w141_humidityInvalidCalib m2 : 24|1@1+ (1,0) [0|0] "" Vector__XXX
 SG_ OCS1P_w142_tempHumidityInvalid m2 : 25|1@1+ (1,0) [0|0] "" Vector__XXX
 SG_ OCS1P_w143_mismatchPassAirbag m2 : 26|1@1+ (1,0) [0|0] "" Vector__XXX
 SG_ OCS1P_w144_mismatchCarRegion m2 : 27|1@1+ (1,0) [0|0] "" Vector__XXX
 SG_ OCS1P_w145_rebaselineTriggered m2 : 28|1@1+ (1,0) [0|0] "" Vector__XXX
 SG_ OCS1P_w148_classificationMismatch m2 : 31|1@1+ (1,0) [0|0] "" Vector__XXX
 SG_ OCS1P_w150_rbEntryTriggered m2 : 33|1@1+ (1,0) [0|0] "" Vector__XXX
 SG_ OCS1P_w151_rbEntryExited m2 : 34|1@1+ (1,0) [0|0] "" Vector__XXX
 SG_ OCS1P_w152_rbExit1Triggered m2 : 35|1@1+ (1,0) [0|0] "" Vector__XXX
 SG_ OCS1P_w153_rbExit1Exited m2 : 36|1@1+ (1,0) [0|0] "" Vector__XXX
 SG_ OCS1P_w154_rbExit2Exited1 m2 : 37|1@1+ (1,0) [0|0] "" Vector__XXX
 SG_ OCS1P_w155_rbExit2Exited2 m2 : 38|1@1+ (1,0) [0|0] "" Vector__XXX
 SG_ OCS1P_w156_seatbeltReminderUnavailable m2 : 39|1@1+ (1,0) [0|0] "" Vector__XXX

BO_ 921 DAS_status: 8 Vector__XXX
 SG_ DAS_autopilotState : 0|4@1+ (1,0) [0|0] "" Vector__XXX
 SG_ DAS_blindSpotRearLeft : 4|2@1+ (1,0) [0|0] "" Vector__XXX
 SG_ DAS_blindSpotRearRight : 6|2@1+ (1,0) [0|0] "" Vector__XXX
 SG_ DAS_fusedSpeedLimit : 8|5@1+ (5,0) [0|0] "" Vector__XXX
 SG_ DAS_suppressSpeedWarning : 13|1@1+ (1,0) [0|0] "" Vector__XXX
 SG_ DAS_summonObstacle : 14|1@1+ (1,0) [0|0] "" Vector__XXX
 SG_ DAS_summonClearedGate : 15|1@1+ (1,0) [0|0] "" Vector__XXX
 SG_ DAS_visionOnlySpeedLimit : 16|5@1+ (5,0) [0|0] "" Vector__XXX
 SG_ DAS_heaterState : 21|1@1+ (1,0) [0|0] "" Vector__XXX
 SG_ DAS_forwardCollisionWarning : 22|2@1+ (1,0) [0|0] "" Vector__XXX
 SG_ DAS_autoparkReady : 24|1@1+ (1,0) [0|0] "" Vector__XXX
 SG_ DAS_autoParked : 25|1@1+ (1,0) [0|0] "" Vector__XXX
 SG_ DAS_autoparkActive : 26|1@1+ (1,0) [0|0] "" Vector__XXX
 SG_ DAS_summonFwdLeashReached : 27|1@1+ (1,0) [0|0] "" Vector__XXX
 SG_ DAS_summonRvsLeashReached : 28|1@1+ (1,0) [0|0] "" Vector__XXX
 SG_ DAS_lssState : 29|3@1+ (1,0) [0|0] "" Vector__XXX
 SG_ DAS_sideCollisionAvoid : 32|2@1+ (1,0) [0|0] "" Vector__XXX
 SG_ DAS_sideCollisionWarning : 34|2@1+ (1,0) [0|0] "" Vector__XXX
 SG_ DAS_sideCollisionInhibit : 36|1@1+ (1,0) [0|0] "" Vector__XXX
 SG_ DAS_laneDepartureWarning : 37|3@1+ (1,0) [0|0] "" Vector__XXX
 SG_ DAS_fleetSpeedState : 40|2@1+ (1,0) [0|0] "" Vector__XXX
 SG_ DAS_autopilotHandsOnState : 42|4@1+ (1,0) [0|0] "" Vector__XXX
 SG_ DAS_autoLaneChangeState : 46|5@1+ (1,0) [0|0] "" Vector__XXX
 SG_ DAS_summonAvailable : 51|1@1+ (1,0) [0|0] "" Vector__XXX
 SG_ DAS_statusCounter : 52|4@1+ (1,0) [0|0] "" Vector__XXX
 SG_ DAS_statusChecksum : 56|8@1+ (1,0) [0|0] "" Vector__XXX

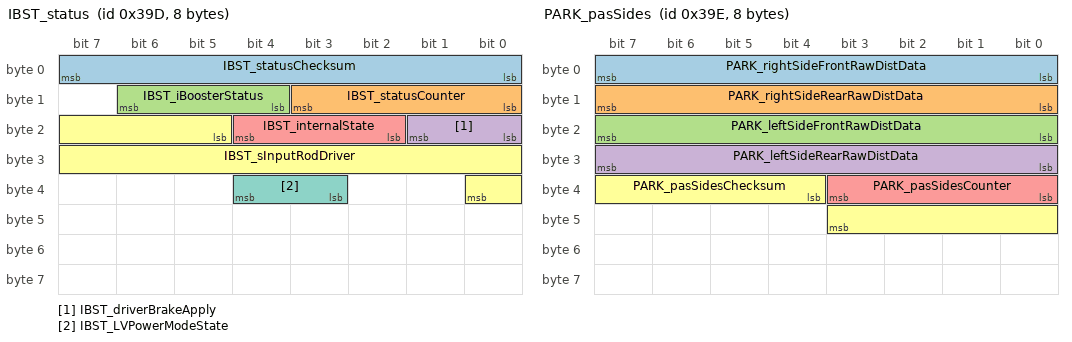
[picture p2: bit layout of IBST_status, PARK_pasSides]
BO_ 925 IBST_status: 8 Vector__XXX
 SG_ IBST_statusChecksum : 0|8@1+ (1,0) [0|0] "" Vector__XXX
 SG_ IBST_statusCounter : 8|4@1+ (1,0) [0|0] "" Vector__XXX
 SG_ IBST_iBoosterStatus : 12|3@1+ (1,0) [0|0] "" Vector__XXX
 SG_ IBST_driverBrakeApply : 16|2@1+ (1,0) [0|0] "" Vector__XXX
 SG_ IBST_internalState : 18|3@1+ (1,0) [0|0] "" Vector__XXX
 SG_ IBST_sInputRodDriver : 21|12@1+ (0.015625,-5) [0|0] "" Vector__XXX
 SG_ IBST_LVPowerModeState : 35|2@1+ (1,0) [0|0] "" Vector__XXX

BO_ 926 PARK_pasSides: 8 Vector__XXX
 SG_ PARK_rightSideFrontRawDistData : 0|8@1+ (1,0) [0|0] "" Vector__XXX
 SG_ PARK_rightSideRearRawDistData : 8|8@1+ (1,0) [0|0] "" Vector__XXX
 SG_ PARK_leftSideFrontRawDistData : 16|8@1+ (1,0) [0|0] "" Vector__XXX
 SG_ PARK_leftSideRearRawDistData : 24|8@1+ (1,0) [0|0] "" Vector__XXX
 SG_ PARK_pasSidesCounter : 32|4@1+ (1,0) [0|0] "" Vector__XXX
 SG_ PARK_pasSidesChecksum : 36|8@1+ (1,0) [0|0] "" Vector__XXX

BO_ 937 DAS_telemetry: 8 Vector__XXX
 SG_ DAS_telemetryMultiplexer M : 0|8@1+ (1,0) [0|0] "" Vector__XXX
 SG_ DAS_MCPObserved m1 : 8|1@1+ (1,0) [0|0] "" Vector__XXX
 SG_ DAS_assPrevSetSpeed m9 : 8|8@1+ (0.25,0) [0|0] "" Vector__XXX
 SG_ DAS_soCamCipvStatus m8 : 8|2@1+ (1,0) [0|0] "" Vector__XXX
 SG_ DAS_stopSignLongitudinalDist m2 : 8|10@1+ (0.1,0) [0|0] "" Vector__XXX
 SG_ DAS_telLeftLaneType m0 : 8|3@1+ (1,0) [0|0] "" Vector__XXX
 SG_ DAS_accReengaged m1 : 9|1@1+ (1,0) [0|0] "" Vector__XXX
 SG_ DAS_csaOverride m7 : 10|1@1+ (1,0) [0|0] "" Vector__XXX
 SG_ DAS_pedestrianInFOVBeforeIntr m1 : 10|1@1+ (1,0) [0|0] "" Vector__XXX
 SG_ DAS_soRad5Status m8 : 10|2@1+ (1,0) [0|0] "" Vector__XXX
 SG_ DAS_csaIntState m7 : 11|3@1+ (1,0) [0|0] "" Vector__XXX
 SG_ DAS_pedestrianInFOVAfterIntr m1 : 11|1@1+ (1,0) [0|0] "" Vector__XXX
 SG_ DAS_telRightLaneType m0 : 11|3@1+ (1,0) [0|0] "" Vector__XXX
 SG_ DAS_camFreeSpaceBeforeIntr m1 : 12|1@1+ (1,0) [0|0] "" Vector__XXX
 SG_ DAS_soRad1Status m8 : 12|2@1+ (1,0) [0|0] "" Vector__XXX
 SG_ DAS_camFreeSpaceAfterIntr m1 : 13|1@1+ (1,0) [0|0] "" Vector__XXX
 SG_ DAS_csaEnableSpeed m7 : 14|12@1+ (0.05,-25) [0|0] "" Vector__XXX
 SG_ DAS_soCamCipvDx m8 : 14|6@1+ (2,0) [0|0] "" Vector__XXX
 SG_ DAS_telLeftMarkerQuality m0 : 14|2@1+ (1,0) [0|0] "" Vector__XXX
 SG_ DAS_timeOfIntervention m1 : 14|6@1+ (0.25,0) [0|0] "" Vector__XXX
 SG_ DAS_assNewSetSpeed m9 : 16|8@1+ (0.25,0) [0|0] "" Vector__XXX
 SG_ DAS_telRightMarkerQuality m0 : 16|2@1+ (1,0) [0|0] "" Vector__XXX
 SG_ DAS_stopSignLateralDist m2 : 18|8@1+ (0.25,-32) [0|0] "" Vector__XXX
 SG_ DAS_telLeftMarkerColor m0 : 18|2@1+ (1,0) [0|0] "" Vector__XXX
 SG_ DAS_soRad1Dx m8 : 20|6@1+ (2,0) [0|0] "" Vector__XXX
 SG_ DAS_telRightMarkerColor m0 : 20|2@1+ (1,0) [0|0] "" Vector__XXX
 SG_ DAS_timeOfFirstPedestrian m1 : 20|6@1+ (0.25,0) [0|0] "" Vector__XXX
 SG_ DAS_telLeftLaneCrossing m0 : 22|1@1+ (1,0) [0|0] "" Vector__XXX
 SG_ DAS_telRightLaneCrossing m0 : 23|1@1+ (1,0) [0|0] "" Vector__XXX
 SG_ DAS_assFusedSpeedLimit m9 : 24|6@1+ (1,0) [0|0] "" Vector__XXX
 SG_ DAS_csaDisableSpeed m7 : 26|12@1+ (0.05,-25) [0|0] "" Vector__XXX
 SG_ DAS_soRad5Dx m8 : 26|6@1+ (2,0) [0|0] "" Vector__XXX
 SG_ DAS_stopSignHeight m2 : 26|6@1+ (0.1,0) [0|0] "" Vector__XXX
 SG_ DAS_timeOfACCReengaging m1 : 26|6@1+ (0.25,0) [0|0] "" Vector__XXX
 SG_ DAS_assAutosteerActive m9 : 30|1@1+ (1,0) [0|0] "" Vector__XXX
 SG_ DAS_assSmartSpeedActive m9 : 31|1@1+ (1,0) [0|0] "" Vector__XXX
 SG_ DAS_durationOfPrevACCStandstill m1 : 32|6@1+ (0.5,0) [0|0] "" Vector__XXX
 SG_ DAS_soCamCipvDy m8 : 32|5@1+ (0.4,-6.4) [0|0] "" Vector__XXX
 SG_ DAS_stopSignStopLineDistance m2 : 32|10@1+ (0.1,-20) [0|0] "" Vector__XXX
 SG_ DAS_soRad5Dy m8 : 37|5@1+ (0.4,-6.4) [0|0] "" Vector__XXX
 SG_ DAS_maxAbsSteeringWheelAngle m1 : 38|7@1+ (2,0) [0|0] "" Vector__XXX
 SG_ DAS_csaFiltCurv m7 : 40|16@1- (1e-06,0) [0|0] "" Vector__XXX
 SG_ DAS_soCamCipvVx m8 : 42|5@1+ (1,0) [0|0] "" Vector__XXX
 SG_ DAS_stopSignCIPVDistance m2 : 42|6@1+ (0.5,0) [0|0] "" Vector__XXX
 SG_ DAS_targetRelvelAtIntervention m1 : 45|6@1+ (0.25,-2) [0|0] "" Vector__XXX
 SG_ DAS_soRad5ObstProb m8 : 47|4@1+ (0.0625,0) [0|0] "" Vector__XXX
 SG_ DAS_stopSignHostAccel m2 : 48|10@1+ (0.01,-5) [0|0] "" Vector__XXX
 SG_ DAS_soRad5Dz m8 : 51|6@1+ (0.25,-5) [0|0] "" Vector__XXX
 SG_ DAS_targetDistAtIntervention m1 : 51|6@1+ (0.5,0) [0|0] "" Vector__XXX
 SG_ DAS_csaMeasLatAccel m7 : 56|8@1+ (0.08,-10.24) [0|0] "" Vector__XXX
 SG_ DAS_egoSpeedAtIntervention m1 : 57|6@1+ (0.5,0) [0|0] "" Vector__XXX
 SG_ DAS_soRad5powerdB m8 : 57|7@1+ (2,0) [0|0] "" Vector__XXX
 SG_ DAS_stopSignCrossingWarning m2 : 58|1@1+ (1,0) [0|0] "" Vector__XXX
 SG_ DAS_stopSignIndex m2 : 59|4@1+ (1,0) [0|0] "" Vector__XXX

BO_ 939 APP_driverMonitorStatus: 8 Vector__XXX
 SG_ APP_cabinCamTelemetryOn : 0|1@1+ (1,0) [0|0] "" Vector__XXX
 SG_ APP_attnMonitorVersion : 1|3@1+ (1,0) [0|0] "" Vector__XXX
 SG_ APP_attnBasedDriverMonitorOn : 4|1@1+ (1,0) [0|0] "" Vector__XXX
 SG_ APP_handsOnDetected : 5|1@1+ (1,0) [0|0] "" Vector__XXX
 SG_ APP_handsOnDetectedSource : 8|3@1+ (1,0) [0|0] "" Vector__XXX
 SG_ APP_cabinCamBlinded : 11|1@1+ (1,0) [0|0] "" Vector__XXX
 SG_ APP_cabinCamDark : 12|1@1+ (1,0) [0|0] "" Vector__XXX
 SG_ APP_driverStateUnknown : 13|1@1+ (1,0) [0|0] "" Vector__XXX
 SG_ APP_driverNotLively : 14|1@1+ (1,0) [0|0] "" Vector__XXX
 SG_ APP_driverStateUnknownHyst : 15|1@1+ (1,0) [0|0] "" Vector__XXX
 SG_ APP_driverLowNominal : 16|1@1+ (1,0) [0|0] "" Vector__XXX
 SG_ APP_driverHeadCappedHyst : 17|1@1+ (1,0) [0|0] "" Vector__XXX
 SG_ APP_driverSunglassesUseHyst : 18|1@1+ (1,0) [0|0] "" Vector__XXX
 SG_ APP_cabinLowLux : 19|1@1+ (1,0) [0|0] "" Vector__XXX
 SG_ APP_cabinCamInconsistent : 20|1@1+ (1,0) [0|0] "" Vector__XXX
 SG_ APP_driverLeaningBack : 21|1@1+ (1,0) [0|0] "" Vector__XXX
 SG_ APP_driverLowEyeVisibility : 22|1@1+ (1,0) [0|0] "" Vector__XXX
 SG_ APP_driverHandsNotReady : 23|1@1+ (1,0) [0|0] "" Vector__XXX
 SG_ APP_driverSeatUnoccupied : 24|1@1+ (1,0) [0|0] "" Vector__XXX
 SG_ APP_handsOnInputRequired : 25|1@1+ (1,0) [0|0] "" Vector__XXX
 SG_ APP_cabinCamDarkHyst : 26|1@1+ (1,0) [0|0] "" Vector__XXX
 SG_ APP_cabinLowLuxHyst : 27|1@1+ (1,0) [0|0] "" Vector__XXX

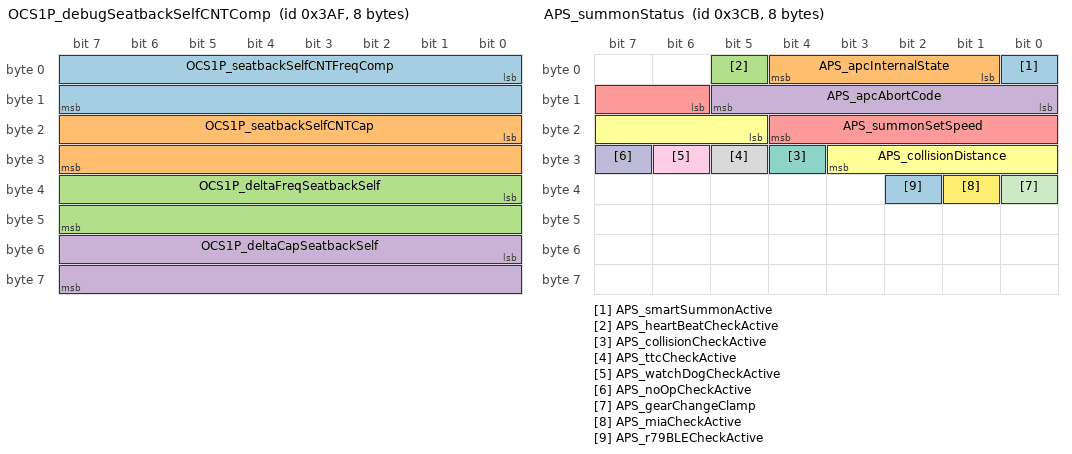
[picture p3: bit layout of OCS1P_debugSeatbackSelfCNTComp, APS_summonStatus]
BO_ 943 OCS1P_debugSeatbackSelfCNTComp: 8 Vector__XXX
 SG_ OCS1P_seatbackSelfCNTFreqComp : 0|16@1+ (1,0) [0|0] "" Vector__XXX
 SG_ OCS1P_seatbackSelfCNTCap : 16|16@1+ (0.005,0) [0|0] "" Vector__XXX
 SG_ OCS1P_deltaFreqSeatbackSelf : 32|16@1- (1,0) [0|0] "" Vector__XXX
 SG_ OCS1P_deltaCapSeatbackSelf : 48|16@1- (0.0025,0) [0|0] "" Vector__XXX

BO_ 945 DAS_telemetryFurniture: 8 Vector__XXX
 SG_ DAS_TF_multiplexer M : 0|5@1+ (1,0) [0|0] "" Vector__XXX
 SG_ DAS_TF_furnitureIndex0 m0 : 5|8@1+ (1,0) [0|0] "" Vector__XXX
 SG_ DAS_TF_furnitureIndex1 m1 : 5|8@1+ (1,0) [0|0] "" Vector__XXX
 SG_ DAS_TF_furnitureIndex2 m2 : 5|8@1+ (1,0) [0|0] "" Vector__XXX
 SG_ DAS_TF_distTraveled m0 : 13|11@1+ (0.1,0) [0|0] "" Vector__XXX
 SG_ DAS_TF_juncStatus m2 : 13|4@1+ (1,0) [0|0] "" Vector__XXX
 SG_ DAS_TF_longitudinalDist m1 : 13|12@1+ (0.1,0) [0|0] "" Vector__XXX
 SG_ DAS_TF_juncDist m2 : 17|11@1+ (0.2,-20) [0|0] "" Vector__XXX
 SG_ DAS_TF_llType m0 : 24|3@1+ (1,0) [0|0] "" Vector__XXX
 SG_ DAS_TF_lateralDist m1 : 25|12@1+ (0.1,-204.8) [0|0] "" Vector__XXX
 SG_ DAS_TF_rlType m0 : 27|3@1+ (1,0) [0|0] "" Vector__XXX
 SG_ DAS_TF_stopLineDist m2 : 28|11@1+ (0.1,-10) [0|0] "" Vector__XXX
 SG_ DAS_TF_cipvDist m0 : 30|9@1+ (0.1,0) [0|0] "" Vector__XXX
 SG_ DAS_TF_height m1 : 37|12@1+ (0.05,0) [0|0] "" Vector__XXX
 SG_ DAS_TF_timeOfDay m0 : 39|3@1+ (1,0) [0|0] "" Vector__XXX
 SG_ DAS_TF_ttc m2 : 39|7@1+ (0.1,0) [0|0] "" Vector__XXX
 SG_ DAS_TF_furnitureType m0 : 42|3@1+ (1,0) [0|0] "" Vector__XXX
 SG_ DAS_TF_color m1 : 49|3@1+ (1,0) [0|0] "" Vector__XXX
 SG_ DAS_TF_shape m1 : 52|3@1+ (1,0) [0|0] "" Vector__XXX
 SG_ DAS_TF_orientation m1 : 55|2@1+ (1,0) [0|0] "" Vector__XXX
 SG_ DAS_TF_transmissionStatus m1 : 57|2@1+ (1,0) [0|0] "" Vector__XXX
 SG_ DAS_TF_isMain m1 : 59|1@1+ (1,0) [0|0] "" Vector__XXX
 SG_ DAS_TF_isTeslaMain m1 : 60|1@1+ (1,0) [0|0] "" Vector__XXX

BO_ 947 UI_vehicleControl2: 8 Vector__XXX
 SG_ UI_gloveboxRequest : 0|1@1+ (1,0) [0|0] "" Vector__XXX
 SG_ UI_trunkRequest : 1|1@1+ (1,0) [0|0] "" Vector__XXX
 SG_ UI_UMCUpdateInhibit : 2|1@1+ (1,0) [0|0] "" Vector__XXX
 SG_ UI_WCUpdateInhibit : 3|1@1+ (1,0) [0|0] "" Vector__XXX
 SG_ UI_soundHornOnLock : 4|1@1+ (1,0) [0|0] "" Vector__XXX
 SG_ UI_locksPanelActive : 5|1@1+ (1,0) [0|0] "" Vector__XXX
 SG_ UI_PINToDriveEnabled : 6|1@1+ (1,0) [0|0] "" Vector__XXX
 SG_ UI_PINToDrivePassed : 7|1@1+ (1,0) [0|0] "" Vector__XXX
 SG_ UI_disableMirrorAutoDim : 8|1@1+ (1,0) [0|0] "" Vector__XXX
 SG_ UI_lightSwitch : 9|3@1+ (1,0) [0|0] "" Vector__XXX
 SG_ UI_readyToAddKey : 12|1@1+ (1,0) [0|0] "" Vector__XXX
 SG_ UI_alarmTriggerRequest : 13|1@1+ (1,0) [0|0] "" Vector__XXX
 SG_ UI_VCSECFeature1 : 14|1@1+ (1,0) [0|0] "" Vector__XXX
 SG_ UI_VCLEFTFeature1 : 15|1@1+ (1,0) [0|0] "" Vector__XXX
 SG_ UI_summonState : 16|2@1+ (1,0) [0|0] "" Vector__XXX
 SG_ UI_displayOnForUser : 18|1@1+ (1,0) [0|0] "" Vector__XXX
 SG_ UI_freeRollModeRequest : 19|1@1+ (1,0) [0|0] "" Vector__XXX
 SG_ UI_BLEPushNotificationRequest : 20|1@1+ (1,0) [0|0] "" Vector__XXX
 SG_ UI_pairKeyQRCodeDisplaying : 21|1@1+ (1,0) [0|0] "" Vector__XXX
 SG_ UI_keepAutopilotAwake : 22|1@1+ (1,0) [0|0] "" Vector__XXX
 SG_ UI_batteryPreconditioningRequest : 23|1@1+ (1,0) [0|0] "" Vector__XXX
 SG_ UI_coastDownMode : 24|1@1+ (1,0) [0|0] "" Vector__XXX
 SG_ UI_autopilotPowerStateRequest : 25|2@1+ (1,0) [0|0] "" Vector__XXX
 SG_ UI_shorted12VCellTestMode : 27|2@1+ (1,0) [0|0] "" Vector__XXX
 SG_ UI_autoRollWindowsOnLockEnable : 29|1@1+ (1,0) [0|0] "" Vector__XXX
 SG_ UI_virtualPitchSensorOverrideOKForAim : 30|1@1+ (1,0) [0|0] "" Vector__XXX
 SG_ UI_conditionalLoggingEnabledVCSEC : 31|1@1+ (1,0) [0|0] "" Vector__XXX
 SG_ UI_WC3UpdateInhibit : 32|1@1+ (1,0) [0|0] "" Vector__XXX
 SG_ UI_steeringWheelHeatReq : 33|1@1+ (1,0) [0|0] "" Vector__XXX
 SG_ UI_disableHorn : 34|1@1+ (1,0) [0|0] "" Vector__XXX
 SG_ UI_frontRightSeatAutoClimateReq : 39|1@1+ (1,0) [0|0] "" Vector__XXX
 SG_ UI_sleepFeature1 : 51|1@1+ (1,0) [0|0] "" Vector__XXX
 SG_ UI_dcr12VThreshold : 52|4@1+ (1,0) [0|0] "" Vector__XXX
 SG_ UI_frontLeftSeatAutoClimateReq : 56|1@1+ (1,0) [0|0] "" Vector__XXX
 SG_ UI_wiperHeaterReq : 57|1@1+ (1,0) [0|0] "" Vector__XXX
 SG_ UI_tireSeason : 59|1@1+ (1,0) [0|0] "" Vector__XXX
 SG_ UI_saveTireConfigReq : 60|1@1+ (1,0) [0|0] "" Vector__XXX
 SG_ UI_silentAlarm : 61|1@1+ (1,0) [0|0] "" Vector__XXX
 SG_ UI_sleepFeature2 : 63|1@1+ (1,0) [0|0] "" Vector__XXX

BO_ 952 UI_tpmsRCPsetting: 8 Vector__XXX
 SG_ UI_setRCPFront : 16|8@1+ (0.025,0) [0|0] "" Vector__XXX
 SG_ UI_setRCPRear : 24|8@1+ (0.025,0) [0|0] "" Vector__XXX

BO_ 954 USM_alertMatrix: 8 Vector__XXX
 SG_ USM_matrixIndex M : 0|4@1+ (1,0) [0|0] "" Vector__XXX
 SG_ USM_a001_WatchdogReset m0 : 4|1@1+ (1,0) [0|0] "" Vector__XXX
 SG_ USM_a061_XCPConnected m1 : 4|1@1+ (1,0) [0|0] "" Vector__XXX
 SG_ USM_a181_s5Blocked m3 : 4|1@1+ (1,0) [0|0] "" Vector__XXX
 SG_ USM_a241_s2HwComErrDiagnostics m4 : 4|1@1+ (1,0) [0|0] "" Vector__XXX
 SG_ USM_a002_PowerLossReset m0 : 5|1@1+ (1,0) [0|0] "" Vector__XXX
 SG_ USM_a062_XCPWasConnected m1 : 5|1@1+ (1,0) [0|0] "" Vector__XXX
 SG_ USM_a182_s6Blocked m3 : 5|1@1+ (1,0) [0|0] "" Vector__XXX
 SG_ USM_a242_s3HwComErrDiagnostics m4 : 5|1@1+ (1,0) [0|0] "" Vector__XXX
 SG_ USM_a003_SWAssertion m0 : 6|1@1+ (1,0) [0|0] "" Vector__XXX
 SG_ USM_a063_SwitchFault m1 : 6|1@1+ (1,0) [0|0] "" Vector__XXX
 SG_ USM_a183_s7Blocked m3 : 6|1@1+ (1,0) [0|0] "" Vector__XXX
 SG_ USM_a243_s4HwComErrDiagnostics m4 : 6|1@1+ (1,0) [0|0] "" Vector__XXX
 SG_ USM_a064_busSleepReqTimeout m1 : 7|1@1+ (1,0) [0|0] "" Vector__XXX
 SG_ USM_a184_s8Blocked m3 : 7|1@1+ (1,0) [0|0] "" Vector__XXX
 SG_ USM_a244_s5HwComErrDiagnostics m4 : 7|1@1+ (1,0) [0|0] "" Vector__XXX
 SG_ USM_a005_CANTXError m0 : 8|1@1+ (1,0) [0|0] "" Vector__XXX
 SG_ USM_a185_s9Blocked m3 : 8|1@1+ (1,0) [0|0] "" Vector__XXX
 SG_ USM_a245_s6HwComErrDiagnostics m4 : 8|1@1+ (1,0) [0|0] "" Vector__XXX
 SG_ USM_a006_CANTX_cyclicError m0 : 9|1@1+ (1,0) [0|0] "" Vector__XXX
 SG_ USM_a186_s10Blocked m3 : 9|1@1+ (1,0) [0|0] "" Vector__XXX
 SG_ USM_a246_s7HwComErrDiagnostics m4 : 9|1@1+ (1,0) [0|0] "" Vector__XXX
 SG_ USM_a187_s11Blocked m3 : 10|1@1+ (1,0) [0|0] "" Vector__XXX
 SG_ USM_a247_s8HwComErrDiagnostics m4 : 10|1@1+ (1,0) [0|0] "" Vector__XXX
 SG_ USM_a188_s12Blocked m3 : 11|1@1+ (1,0) [0|0] "" Vector__XXX
 SG_ USM_a248_s9HwComErrDiagnostics m4 : 11|1@1+ (1,0) [0|0] "" Vector__XXX
 SG_ USM_a189_s1Disconnected m3 : 12|1@1+ (1,0) [0|0] "" Vector__XXX
 SG_ USM_a249_s10HwComErrDiagnostics m4 : 12|1@1+ (1,0) [0|0] "" Vector__XXX
 SG_ USM_a190_s2Disconnected m3 : 13|1@1+ (1,0) [0|0] "" Vector__XXX
 SG_ USM_a250_s11HwComErrDiagnostics m4 : 13|1@1+ (1,0) [0|0] "" Vector__XXX
 SG_ USM_a131_s1ComError m2 : 14|1@1+ (1,0) [0|0] "" Vector__XXX
 SG_ USM_a191_s3Disconnected m3 : 14|1@1+ (1,0) [0|0] "" Vector__XXX
 SG_ USM_a251_s12HwComErrDiagnostics m4 : 14|1@1+ (1,0) [0|0] "" Vector__XXX
 SG_ USM_a012_CPUReset m0 : 15|1@1+ (1,0) [0|0] "" Vector__XXX
 SG_ USM_a132_s2ComError m2 : 15|1@1+ (1,0) [0|0] "" Vector__XXX
 SG_ USM_a192_s4Disconnected m3 : 15|1@1+ (1,0) [0|0] "" Vector__XXX
 SG_ USM_a252_anyComErrorSet m4 : 15|1@1+ (1,0) [0|0] "" Vector__XXX
 SG_ USM_a013_AlertManagerFault m0 : 16|1@1+ (1,0) [0|0] "" Vector__XXX
 SG_ USM_a133_s3ComError m2 : 16|1@1+ (1,0) [0|0] "" Vector__XXX
 SG_ USM_a193_s5Disconnected m3 : 16|1@1+ (1,0) [0|0] "" Vector__XXX
 SG_ USM_a253_anyHwErrorSet m4 : 16|1@1+ (1,0) [0|0] "" Vector__XXX
 SG_ USM_a134_s4ComError m2 : 17|1@1+ (1,0) [0|0] "" Vector__XXX
 SG_ USM_a194_s6Disconnected m3 : 17|1@1+ (1,0) [0|0] "" Vector__XXX
 SG_ USM_a254_frontSensorsOvercurrent m4 : 17|1@1+ (1,0) [0|0] "" Vector__XXX
 SG_ USM_a015_NVMMError m0 : 18|1@1+ (1,0) [0|0] "" Vector__XXX
 SG_ USM_a135_s5ComError m2 : 18|1@1+ (1,0) [0|0] "" Vector__XXX
 SG_ USM_a195_s7Disconnected m3 : 18|1@1+ (1,0) [0|0] "" Vector__XXX
 SG_ USM_a255_rearSensorsOvercurrent m4 : 18|1@1+ (1,0) [0|0] "" Vector__XXX
 SG_ USM_a016_NVMMRecordError m0 : 19|1@1+ (1,0) [0|0] "" Vector__XXX
 SG_ USM_a136_s6ComError m2 : 19|1@1+ (1,0) [0|0] "" Vector__XXX
 SG_ USM_a196_s8Disconnected m3 : 19|1@1+ (1,0) [0|0] "" Vector__XXX
 SG_ USM_a137_s7ComError m2 : 20|1@1+ (1,0) [0|0] "" Vector__XXX
 SG_ USM_a197_s9Disconnected m3 : 20|1@1+ (1,0) [0|0] "" Vector__XXX
 SG_ USM_a138_s8ComError m2 : 21|1@1+ (1,0) [0|0] "" Vector__XXX
 SG_ USM_a198_s10Disconnected m3 : 21|1@1+ (1,0) [0|0] "" Vector__XXX
 SG_ USM_a139_s9ComError m2 : 22|1@1+ (1,0) [0|0] "" Vector__XXX
 SG_ USM_a199_s11Disconnected m3 : 22|1@1+ (1,0) [0|0] "" Vector__XXX
 SG_ USM_a140_s10ComError m2 : 23|1@1+ (1,0) [0|0] "" Vector__XXX
 SG_ USM_a200_s12Disconnected m3 : 23|1@1+ (1,0) [0|0] "" Vector__XXX
 SG_ USM_a021_TaskSchedulerError m0 : 24|1@1+ (1,0) [0|0] "" Vector__XXX
 SG_ USM_a141_s11ComError m2 : 24|1@1+ (1,0) [0|0] "" Vector__XXX
 SG_ USM_a201_e52142Fault m3 : 24|1@1+ (1,0) [0|0] "" Vector__XXX
 SG_ USM_a022_TaskInitError m0 : 25|1@1+ (1,0) [0|0] "" Vector__XXX
 SG_ USM_a082_VCRIGHT_IPC_MIA m1 : 25|1@1+ (1,0) [0|0] "" Vector__XXX
 SG_ USM_a142_s12ComError m2 : 25|1@1+ (1,0) [0|0] "" Vector__XXX
 SG_ USM_a202_e52417Fault m3 : 25|1@1+ (1,0) [0|0] "" Vector__XXX
 SG_ USM_a083_VCLEFT_IPC_MIA m1 : 26|1@1+ (1,0) [0|0] "" Vector__XXX
 SG_ USM_a143_s1HwError m2 : 26|1@1+ (1,0) [0|0] "" Vector__XXX
 SG_ USM_a203_s1NearFieldDetected m3 : 26|1@1+ (1,0) [0|0] "" Vector__XXX
 SG_ USM_a084_TPMS_MIA m1 : 27|1@1+ (1,0) [0|0] "" Vector__XXX
 SG_ USM_a144_s2HwError m2 : 27|1@1+ (1,0) [0|0] "" Vector__XXX
 SG_ USM_a204_s2NearFieldDetected m3 : 27|1@1+ (1,0) [0|0] "" Vector__XXX
 SG_ USM_a085_CCCM_MIA m1 : 28|1@1+ (1,0) [0|0] "" Vector__XXX
 SG_ USM_a145_s3HwError m2 : 28|1@1+ (1,0) [0|0] "" Vector__XXX
 SG_ USM_a205_s3NearFieldDetected m3 : 28|1@1+ (1,0) [0|0] "" Vector__XXX
 SG_ USM_a086_VCBATT_MIA m1 : 29|1@1+ (1,0) [0|0] "" Vector__XXX
 SG_ USM_a146_s4HwError m2 : 29|1@1+ (1,0) [0|0] "" Vector__XXX
 SG_ USM_a206_s4NearFieldDetected m3 : 29|1@1+ (1,0) [0|0] "" Vector__XXX
 SG_ USM_a087_DIREL_MIA m1 : 30|1@1+ (1,0) [0|0] "" Vector__XXX
 SG_ USM_a147_s5HwError m2 : 30|1@1+ (1,0) [0|0] "" Vector__XXX
 SG_ USM_a207_s5NearFieldDetected m3 : 30|1@1+ (1,0) [0|0] "" Vector__XXX
 SG_ USM_a088_DIRER_MIA m1 : 31|1@1+ (1,0) [0|0] "" Vector__XXX
 SG_ USM_a148_s6HwError m2 : 31|1@1+ (1,0) [0|0] "" Vector__XXX
 SG_ USM_a208_s6NearFieldDetected m3 : 31|1@1+ (1,0) [0|0] "" Vector__XXX
 SG_ USM_a029_CoreDump m0 : 32|1@1+ (1,0) [0|0] "" Vector__XXX
 SG_ USM_a089_IBST_MIA m1 : 32|1@1+ (1,0) [0|0] "" Vector__XXX
 SG_ USM_a149_s7HwError m2 : 32|1@1+ (1,0) [0|0] "" Vector__XXX
 SG_ USM_a209_s7NearFieldDetected m3 : 32|1@1+ (1,0) [0|0] "" Vector__XXX
 SG_ USM_a030_ECULogUploadRequest m0 : 33|1@1+ (1,0) [0|0] "" Vector__XXX
 SG_ USM_a090_APS_MIA m1 : 33|1@1+ (1,0) [0|0] "" Vector__XXX
 SG_ USM_a150_s8HwError m2 : 33|1@1+ (1,0) [0|0] "" Vector__XXX
 SG_ USM_a210_s8NearFieldDetected m3 : 33|1@1+ (1,0) [0|0] "" Vector__XXX
 SG_ USM_a031_UDSActive m0 : 34|1@1+ (1,0) [0|0] "" Vector__XXX
 SG_ USM_a091_CMPD_MIA m1 : 34|1@1+ (1,0) [0|0] "" Vector__XXX
 SG_ USM_a151_s9HwError m2 : 34|1@1+ (1,0) [0|0] "" Vector__XXX
 SG_ USM_a211_s9NearFieldDetected m3 : 34|1@1+ (1,0) [0|0] "" Vector__XXX
 SG_ USM_a092_VCSEATD_MIA m1 : 35|1@1+ (1,0) [0|0] "" Vector__XXX
 SG_ USM_a152_s10HwError m2 : 35|1@1+ (1,0) [0|0] "" Vector__XXX
 SG_ USM_a212_s10NearFieldDetected m3 : 35|1@1+ (1,0) [0|0] "" Vector__XXX
 SG_ USM_a093_VCSEATP_MIA m1 : 36|1@1+ (1,0) [0|0] "" Vector__XXX
 SG_ USM_a153_s11HwError m2 : 36|1@1+ (1,0) [0|0] "" Vector__XXX
 SG_ USM_a213_s11NearFieldDetected m3 : 36|1@1+ (1,0) [0|0] "" Vector__XXX
 SG_ USM_a094_EPAS3P_MIA m1 : 37|1@1+ (1,0) [0|0] "" Vector__XXX
 SG_ USM_a154_s12HwError m2 : 37|1@1+ (1,0) [0|0] "" Vector__XXX
 SG_ USM_a214_s12NearFieldDetected m3 : 37|1@1+ (1,0) [0|0] "" Vector__XXX
 SG_ USM_a095_CHG_MIA m1 : 38|1@1+ (1,0) [0|0] "" Vector__XXX
 SG_ USM_a155_s1OverTemp m2 : 38|1@1+ (1,0) [0|0] "" Vector__XXX
 SG_ USM_a215_s1DebugEepromInvalid m3 : 38|1@1+ (1,0) [0|0] "" Vector__XXX
 SG_ USM_a096_OCS1P_MIA m1 : 39|1@1+ (1,0) [0|0] "" Vector__XXX
 SG_ USM_a156_s2OverTemp m2 : 39|1@1+ (1,0) [0|0] "" Vector__XXX
 SG_ USM_a216_s2DebugEepromInvalid m3 : 39|1@1+ (1,0) [0|0] "" Vector__XXX
 SG_ USM_a097_CMP_MIA m1 : 40|1@1+ (1,0) [0|0] "" Vector__XXX
 SG_ USM_a157_s3OverTemp m2 : 40|1@1+ (1,0) [0|0] "" Vector__XXX
 SG_ USM_a217_s3DebugEepromInvalid m3 : 40|1@1+ (1,0) [0|0] "" Vector__XXX
 SG_ USM_a098_DIR_MIA m1 : 41|1@1+ (1,0) [0|0] "" Vector__XXX
 SG_ USM_a158_s4OverTemp m2 : 41|1@1+ (1,0) [0|0] "" Vector__XXX
 SG_ USM_a218_s4DebugEepromInvalid m3 : 41|1@1+ (1,0) [0|0] "" Vector__XXX
 SG_ USM_a099_PARK_MIA m1 : 42|1@1+ (1,0) [0|0] "" Vector__XXX
 SG_ USM_a159_s5OverTemp m2 : 42|1@1+ (1,0) [0|0] "" Vector__XXX
 SG_ USM_a219_s5DebugEepromInvalid m3 : 42|1@1+ (1,0) [0|0] "" Vector__XXX
 SG_ USM_a100_CANbus_MIA m1 : 43|1@1+ (1,0) [0|0] "" Vector__XXX
 SG_ USM_a160_s6OverTemp m2 : 43|1@1+ (1,0) [0|0] "" Vector__XXX
 SG_ USM_a220_s6DebugEepromInvalid m3 : 43|1@1+ (1,0) [0|0] "" Vector__XXX
 SG_ USM_a041_HighCPULoad m0 : 44|1@1+ (1,0) [0|0] "" Vector__XXX
 SG_ USM_a101_PM_MIA m1 : 44|1@1+ (1,0) [0|0] "" Vector__XXX
 SG_ USM_a161_s7OverTemp m2 : 44|1@1+ (1,0) [0|0] "" Vector__XXX
 SG_ USM_a221_s7DebugEepromInvalid m3 : 44|1@1+ (1,0) [0|0] "" Vector__XXX
 SG_ USM_a042_HighStackUsage m0 : 45|1@1+ (1,0) [0|0] "" Vector__XXX
 SG_ USM_a102_PTC_MIA m1 : 45|1@1+ (1,0) [0|0] "" Vector__XXX
 SG_ USM_a162_s8OverTemp m2 : 45|1@1+ (1,0) [0|0] "" Vector__XXX
 SG_ USM_a222_s8DebugEepromInvalid m3 : 45|1@1+ (1,0) [0|0] "" Vector__XXX
 SG_ USM_a043_Task1msError m0 : 46|1@1+ (1,0) [0|0] "" Vector__XXX
 SG_ USM_a103_CP_MIA m1 : 46|1@1+ (1,0) [0|0] "" Vector__XXX
 SG_ USM_a163_s9OverTemp m2 : 46|1@1+ (1,0) [0|0] "" Vector__XXX
 SG_ USM_a223_s9DebugEepromInvalid m3 : 46|1@1+ (1,0) [0|0] "" Vector__XXX
 SG_ USM_a044_Task10msError m0 : 47|1@1+ (1,0) [0|0] "" Vector__XXX
 SG_ USM_a104_DAS_MIA m1 : 47|1@1+ (1,0) [0|0] "" Vector__XXX
 SG_ USM_a164_s10OverTemp m2 : 47|1@1+ (1,0) [0|0] "" Vector__XXX
 SG_ USM_a224_s10DebugEepromInvalid m3 : 47|1@1+ (1,0) [0|0] "" Vector__XXX
 SG_ USM_a045_Task100msError m0 : 48|1@1+ (1,0) [0|0] "" Vector__XXX
 SG_ USM_a105_TAS_MIA m1 : 48|1@1+ (1,0) [0|0] "" Vector__XXX
 SG_ USM_a165_s11OverTemp m2 : 48|1@1+ (1,0) [0|0] "" Vector__XXX
 SG_ USM_a225_s11DebugEepromInvalid m3 : 48|1@1+ (1,0) [0|0] "" Vector__XXX
 SG_ USM_a046_Task1000msError m0 : 49|1@1+ (1,0) [0|0] "" Vector__XXX
 SG_ USM_a106_PCS_MIA m1 : 49|1@1+ (1,0) [0|0] "" Vector__XXX
 SG_ USM_a166_s12OverTemp m2 : 49|1@1+ (1,0) [0|0] "" Vector__XXX
 SG_ USM_a226_s12DebugEepromInvalid m3 : 49|1@1+ (1,0) [0|0] "" Vector__XXX
 SG_ USM_a107_BMS_MIA m1 : 50|1@1+ (1,0) [0|0] "" Vector__XXX
 SG_ USM_a227_s1InitError m3 : 50|1@1+ (1,0) [0|0] "" Vector__XXX
 SG_ USM_a108_DIF_MIA m1 : 51|1@1+ (1,0) [0|0] "" Vector__XXX
 SG_ USM_a228_s2InitError m3 : 51|1@1+ (1,0) [0|0] "" Vector__XXX
 SG_ USM_a109_RCM_MIA m1 : 52|1@1+ (1,0) [0|0] "" Vector__XXX
 SG_ USM_a229_s3InitError m3 : 52|1@1+ (1,0) [0|0] "" Vector__XXX
 SG_ USM_a110_GTW_MIA m1 : 53|1@1+ (1,0) [0|0] "" Vector__XXX
 SG_ USM_a230_s4InitError m3 : 53|1@1+ (1,0) [0|0] "" Vector__XXX
 SG_ USM_a111_EPBR_MIA m1 : 54|1@1+ (1,0) [0|0] "" Vector__XXX
 SG_ USM_a231_s5InitError m3 : 54|1@1+ (1,0) [0|0] "" Vector__XXX
 SG_ USM_a112_EPBL_MIA m1 : 55|1@1+ (1,0) [0|0] "" Vector__XXX
 SG_ USM_a232_s6InitError m3 : 55|1@1+ (1,0) [0|0] "" Vector__XXX
 SG_ USM_a113_UI_MIA m1 : 56|1@1+ (1,0) [0|0] "" Vector__XXX
 SG_ USM_a233_s7InitError m3 : 56|1@1+ (1,0) [0|0] "" Vector__XXX
 SG_ USM_a114_ESP_MIA m1 : 57|1@1+ (1,0) [0|0] "" Vector__XXX
 SG_ USM_a234_s8InitError m3 : 57|1@1+ (1,0) [0|0] "" Vector__XXX
 SG_ USM_a115_VCSEC_MIA m1 : 58|1@1+ (1,0) [0|0] "" Vector__XXX
 SG_ USM_a235_s9InitError m3 : 58|1@1+ (1,0) [0|0] "" Vector__XXX
 SG_ USM_a116_VCRIGHT_MIA m1 : 59|1@1+ (1,0) [0|0] "" Vector__XXX
 SG_ USM_a236_s10InitError m3 : 59|1@1+ (1,0) [0|0] "" Vector__XXX
 SG_ USM_a057_HVP_MIA m0 : 60|1@1+ (1,0) [0|0] "" Vector__XXX
 SG_ USM_a117_VCLEFT_MIA m1 : 60|1@1+ (1,0) [0|0] "" Vector__XXX
 SG_ USM_a177_s1Blocked m2 : 60|1@1+ (1,0) [0|0] "" Vector__XXX
 SG_ USM_a237_s11InitError m3 : 60|1@1+ (1,0) [0|0] "" Vector__XXX
 SG_ USM_a058_inputRHighSyncDebug m0 : 61|1@1+ (1,0) [0|0] "" Vector__XXX
 SG_ USM_a118_VCFRONT_MIA m1 : 61|1@1+ (1,0) [0|0] "" Vector__XXX
 SG_ USM_a178_s2Blocked m2 : 61|1@1+ (1,0) [0|0] "" Vector__XXX
 SG_ USM_a238_s12InitError m3 : 61|1@1+ (1,0) [0|0] "" Vector__XXX
 SG_ USM_a059_inputResistanceHigh m0 : 62|1@1+ (1,0) [0|0] "" Vector__XXX
 SG_ USM_a119_SCCM_MIA m1 : 62|1@1+ (1,0) [0|0] "" Vector__XXX
 SG_ USM_a179_s3Blocked m2 : 62|1@1+ (1,0) [0|0] "" Vector__XXX
 SG_ USM_a060_engineeringBuild m0 : 63|1@1+ (1,0) [0|0] "" Vector__XXX
 SG_ USM_a120_DI_DRIVE_MIA m1 : 63|1@1+ (1,0) [0|0] "" Vector__XXX
 SG_ USM_a180_s4Blocked m2 : 63|1@1+ (1,0) [0|0] "" Vector__XXX
 SG_ USM_a240_s1HwComErrDiagnostics m3 : 63|1@1+ (1,0) [0|0] "" Vector__XXX

BO_ 962 VCLEFT_switchStatus: 8 Vector__XXX
 SG_ VCLEFT_switchStatusIndex M : 0|1@1+ (1,0) [0|0] "" Vector__XXX
 SG_ VCLEFT_hornSwitchPressed m0 : 2|1@1+ (1,0) [0|0] "" Vector__XXX
 SG_ VCLEFT_isAlcoholInterlockSet m1 : 2|1@1+ (1,0) [0|0] "" Vector__XXX
 SG_ VCLEFT_hazardButtonPressed m0 : 3|1@1+ (1,0) [0|0] "" Vector__XXX
 SG_ VCLEFT_swcLeftTiltRight m1 : 3|2@1+ (1,0) [0|0] "" Vector__XXX
 SG_ VCLEFT_brakeSwitchPressed m0 : 4|1@1+ (1,0) [0|0] "" Vector__XXX
 SG_ VCLEFT_rightMirrorTilt m0 : 5|3@1+ (1,0) [0|0] "" Vector__XXX
 SG_ VCLEFT_swcLeftPressed m1 : 5|2@1+ (1,0) [0|0] "" Vector__XXX
 SG_ VCLEFT_frontSeatTrackBack m0 : 8|2@1+ (1,0) [0|0] "" Vector__XXX
 SG_ VCLEFT_swcRightTiltLeft m1 : 8|2@1+ (1,0) [0|0] "" Vector__XXX
 SG_ VCLEFT_frontSeatTrackForward m0 : 10|2@1+ (1,0) [0|0] "" Vector__XXX
 SG_ VCLEFT_swcRightTiltRight m1 : 10|2@1+ (1,0) [0|0] "" Vector__XXX
 SG_ VCLEFT_frontSeatTiltDown m0 : 12|2@1+ (1,0) [0|0] "" Vector__XXX
 SG_ VCLEFT_swcRightPressed m1 : 12|2@1+ (1,0) [0|0] "" Vector__XXX
 SG_ VCLEFT_frontSeatTiltUp m0 : 14|2@1+ (1,0) [0|0] "" Vector__XXX
 SG_ VCLEFT_swcLeftTiltLeft m1 : 14|2@1+ (1,0) [0|0] "" Vector__XXX
 SG_ VCLEFT_frontSeatLiftDown m0 : 16|2@1+ (1,0) [0|0] "" Vector__XXX
 SG_ VCLEFT_swcLeftScrollTicks m1 : 16|6@1- (1,0) [0|0] "" Vector__XXX
 SG_ VCLEFT_frontSeatLiftUp m0 : 18|2@1+ (1,0) [0|0] "" Vector__XXX
 SG_ VCLEFT_frontSeatBackrestBack m0 : 20|2@1+ (1,0) [0|0] "" Vector__XXX
 SG_ VCLEFT_frontSeatBackrestForward m0 : 22|2@1+ (1,0) [0|0] "" Vector__XXX
 SG_ VCLEFT_frontSeatLumbarDown m0 : 24|2@1+ (1,0) [0|0] "" Vector__XXX
 SG_ VCLEFT_swcRightScrollTicks m1 : 24|6@1- (1,0) [0|0] "" Vector__XXX
 SG_ VCLEFT_frontSeatLumbarUp m0 : 26|2@1+ (1,0) [0|0] "" Vector__XXX
 SG_ VCLEFT_frontSeatLumbarIn m0 : 28|2@1+ (1,0) [0|0] "" Vector__XXX
 SG_ VCLEFT_frontSeatLumbarOut m0 : 30|2@1+ (1,0) [0|0] "" Vector__XXX
 SG_ VCLEFT_btnWindowSwPackUpLF m0 : 32|1@1+ (1,0) [0|0] "" Vector__XXX
 SG_ VCLEFT_btnWindowUpLR m1 : 32|1@1+ (1,0) [0|0] "" Vector__XXX
 SG_ VCLEFT_btnWindowAutoUpLR m1 : 33|1@1+ (1,0) [0|0] "" Vector__XXX
 SG_ VCLEFT_btnWindowSwPackAutoUpLF m0 : 33|1@1+ (1,0) [0|0] "" Vector__XXX
 SG_ VCLEFT_btnWindowDownLR m1 : 34|1@1+ (1,0) [0|0] "" Vector__XXX
 SG_ VCLEFT_btnWindowSwPackDownLF m0 : 34|1@1+ (1,0) [0|0] "" Vector__XXX
 SG_ VCLEFT_btnWindowAutoDownLR m1 : 35|1@1+ (1,0) [0|0] "" Vector__XXX
 SG_ VCLEFT_btnWindowSwPackAutoDownLF m0 : 35|1@1+ (1,0) [0|0] "" Vector__XXX
 SG_ VCLEFT_2RowSeatReclineSwitch m1 : 36|1@1+ (1,0) [0|0] "" Vector__XXX
 SG_ VCLEFT_btnWindowSwPackUpLR m0 : 36|1@1+ (1,0) [0|0] "" Vector__XXX
 SG_ VCLEFT_2RowSeatCenterSwitch m1 : 37|1@1+ (1,0) [0|0] "" Vector__XXX
 SG_ VCLEFT_btnWindowSwPackAutoUpLR m0 : 37|1@1+ (1,0) [0|0] "" Vector__XXX
 SG_ VCLEFT_2RowSeatLeftFoldFlatSwitch m1 : 38|1@1+ (1,0) [0|0] "" Vector__XXX
 SG_ VCLEFT_btnWindowSwPackDownLR m0 : 38|1@1+ (1,0) [0|0] "" Vector__XXX
 SG_ VCLEFT_2RowSeatRightFoldFlatSwitch m1 : 39|1@1+ (1,0) [0|0] "" Vector__XXX
 SG_ VCLEFT_btnWindowSwPackAutoDownLR m0 : 39|1@1+ (1,0) [0|0] "" Vector__XXX
 SG_ VCLEFT_2RowSeatBothFoldFlatSwitch m1 : 40|1@1+ (1,0) [0|0] "" Vector__XXX
 SG_ VCLEFT_btnWindowSwPackUpRF m0 : 40|1@1+ (1,0) [0|0] "" Vector__XXX
 SG_ VCLEFT_btnWindowSwPackAutoUpRF m0 : 41|1@1+ (1,0) [0|0] "" Vector__XXX
 SG_ VCLEFT_swcLeftDoublePress m1 : 41|1@1+ (1,0) [0|0] "" Vector__XXX
 SG_ VCLEFT_btnWindowSwPackDownRF m0 : 42|1@1+ (1,0) [0|0] "" Vector__XXX
 SG_ VCLEFT_swcRightDoublePress m1 : 42|1@1+ (1,0) [0|0] "" Vector__XXX
 SG_ VCLEFT_2RowSeatBackrestFoldSwitch m1 : 43|1@1+ (1,0) [0|0] "" Vector__XXX
 SG_ VCLEFT_btnWindowSwPackAutoDownRF m0 : 43|1@1+ (1,0) [0|0] "" Vector__XXX
 SG_ VCLEFT_btnWindowSwPackUpRR m0 : 44|1@1+ (1,0) [0|0] "" Vector__XXX
 SG_ VCLEFT_btnWindowSwPackAutoUpRR m0 : 45|1@1+ (1,0) [0|0] "" Vector__XXX
 SG_ VCLEFT_btnWindowSwPackDownRR m0 : 46|1@1+ (1,0) [0|0] "" Vector__XXX
 SG_ VCLEFT_btnWindowSwPackAutoDownRR m0 : 47|1@1+ (1,0) [0|0] "" Vector__XXX
 SG_ VCLEFT_frontBuckleSwitch m0 : 48|2@1+ (1,0) [0|0] "" Vector__XXX
 SG_ VCLEFT_frontOccupancySwitch m0 : 50|2@1+ (1,0) [0|0] "" Vector__XXX
 SG_ VCLEFT_rearLeftBuckleSwitch m0 : 52|2@1+ (1,0) [0|0] "" Vector__XXX
 SG_ VCLEFT_rearCenterOccupancySwitch m0 : 54|2@1+ (1,0) [0|0] "" Vector__XXX
 SG_ VCLEFT_rearLeftOccupancySwitch m0 : 56|2@1+ (1,0) [0|0] "" Vector__XXX
 SG_ VCLEFT_rearRightOccupancySwitch m0 : 58|2@1+ (1,0) [0|0] "" Vector__XXX
 SG_ VCLEFT_brakePressed m0 : 60|1@1+ (1,0) [0|0] "" Vector__XXX
 SG_ VCLEFT_rearHVACButtonPressed m0 : 61|1@1+ (1,0) [0|0] "" Vector__XXX
 SG_ VCLEFT_frontSeatResistiveOccupancy m1 : 62|2@1+ (1,0) [0|0] "" Vector__XXX
 SG_ VCLEFT_rearCenterBuckleSwitch m0 : 62|2@1+ (1,0) [0|0] "" Vector__XXX

BO_ 963 VCRIGHT_switchStatus: 8 Vector__XXX
 SG_ VCRIGHT_switchStatusIndex M : 0|1@1+ (1,0) [0|0] "" Vector__XXX
 SG_ VCRIGHT_trunkExtReleasePressedPersist m1 : 1|1@1+ (1,0) [0|0] "" Vector__XXX
 SG_ VCRIGHT_frontSeatTrackBack m1 : 2|2@1+ (1,0) [0|0] "" Vector__XXX
 SG_ VCRIGHT_frontSeatTrackForward m1 : 4|2@1+ (1,0) [0|0] "" Vector__XXX
 SG_ VCRIGHT_frontSeatTiltDown m1 : 6|2@1+ (1,0) [0|0] "" Vector__XXX
 SG_ VCRIGHT_frontSeatTiltUp m1 : 8|2@1+ (1,0) [0|0] "" Vector__XXX
 SG_ VCRIGHT_frontSeatLiftDown m1 : 10|2@1+ (1,0) [0|0] "" Vector__XXX
 SG_ VCRIGHT_frontSeatLiftUp m1 : 12|2@1+ (1,0) [0|0] "" Vector__XXX
 SG_ VCRIGHT_frontSeatBackrestBack m1 : 14|2@1+ (1,0) [0|0] "" Vector__XXX
 SG_ VCRIGHT_frontSeatBackrestForward m1 : 16|2@1+ (1,0) [0|0] "" Vector__XXX
 SG_ VCRIGHT_frontSeatLumbarDown m1 : 18|2@1+ (1,0) [0|0] "" Vector__XXX
 SG_ VCRIGHT_frontSeatLumbarUp m1 : 20|2@1+ (1,0) [0|0] "" Vector__XXX
 SG_ VCRIGHT_frontSeatLumbarIn m1 : 22|2@1+ (1,0) [0|0] "" Vector__XXX
 SG_ VCRIGHT_btnWindowUpRF m0 : 24|1@1+ (1,0) [0|0] "" Vector__XXX
 SG_ VCRIGHT_frontSeatLumbarOut m1 : 24|2@1+ (1,0) [0|0] "" Vector__XXX
 SG_ VCRIGHT_btnWindowAutoUpRF m0 : 25|1@1+ (1,0) [0|0] "" Vector__XXX
 SG_ VCRIGHT_2RowSeatReclineSwitch m1 : 26|1@1+ (1,0) [0|0] "" Vector__XXX
 SG_ VCRIGHT_btnWindowDownRF m0 : 26|1@1+ (1,0) [0|0] "" Vector__XXX
 SG_ VCRIGHT_2RowSeatBackrestFoldSwitch m1 : 27|1@1+ (1,0) [0|0] "" Vector__XXX
 SG_ VCRIGHT_btnWindowAutoDownRF m0 : 27|1@1+ (1,0) [0|0] "" Vector__XXX
 SG_ VCRIGHT_btnWindowUpRR m0 : 28|1@1+ (1,0) [0|0] "" Vector__XXX
 SG_ VCRIGHT_btnWindowAutoUpRR m0 : 29|1@1+ (1,0) [0|0] "" Vector__XXX
 SG_ VCRIGHT_btnWindowDownRR m0 : 30|1@1+ (1,0) [0|0] "" Vector__XXX
 SG_ VCRIGHT_btnWindowAutoDownRR m0 : 31|1@1+ (1,0) [0|0] "" Vector__XXX
 SG_ VCRIGHT_btnWindowSwPackUpLF m0 : 32|1@1+ (1,0) [0|0] "" Vector__XXX
 SG_ VCRIGHT_frontHandlePWM m1 : 32|7@1+ (1,0) [0|0] "" Vector__XXX
 SG_ VCRIGHT_btnWindowSwPackAutoUpLF m0 : 33|1@1+ (1,0) [0|0] "" Vector__XXX
 SG_ VCRIGHT_btnWindowSwPackDownLF m0 : 34|1@1+ (1,0) [0|0] "" Vector__XXX
 SG_ VCRIGHT_btnWindowSwPackAutoDwnLF m0 : 35|1@1+ (1,0) [0|0] "" Vector__XXX
 SG_ VCRIGHT_btnWindowSwPackUpLR m0 : 36|1@1+ (1,0) [0|0] "" Vector__XXX
 SG_ VCRIGHT_btnWindowSwPackAutoUpLR m0 : 37|1@1+ (1,0) [0|0] "" Vector__XXX
 SG_ VCRIGHT_btnWindowSwPackDownLR m0 : 38|1@1+ (1,0) [0|0] "" Vector__XXX
 SG_ VCRIGHT_btnWindowSwPackAutoDwnLR m0 : 39|1@1+ (1,0) [0|0] "" Vector__XXX
 SG_ VCRIGHT_hvacHeatingAllowedLeft m1 : 39|1@1+ (1,0) [0|0] "" Vector__XXX
 SG_ VCRIGHT_frontBuckleSwitch m0 : 40|2@1+ (1,0) [0|0] "" Vector__XXX
 SG_ VCRIGHT_rearHandlePWM m1 : 40|7@1+ (1,0) [0|0] "" Vector__XXX
 SG_ VCRIGHT_frontOccupancySwitch m0 : 42|2@1+ (1,0) [0|0] "" Vector__XXX
 SG_ VCRIGHT_rearCenterBuckleSwitch m0 : 44|2@1+ (1,0) [0|0] "" Vector__XXX
 SG_ VCRIGHT_rearRightBuckleSwitch m0 : 46|2@1+ (1,0) [0|0] "" Vector__XXX
 SG_ VCRIGHT_gloveboxLightCurrent m1 : 47|5@1+ (2,0) [0|0] "" Vector__XXX
 SG_ VCRIGHT_trunkExtReleasePressed m0 : 48|1@1+ (1,0) [0|0] "" Vector__XXX
 SG_ VCRIGHT_btnWindowSwPackUpRR m0 : 49|1@1+ (1,0) [0|0] "" Vector__XXX
 SG_ VCRIGHT_btnWindowSwPackAutoUpRR m0 : 50|1@1+ (1,0) [0|0] "" Vector__XXX
 SG_ VCRIGHT_btnWindowSwPackDownRR m0 : 51|1@1+ (1,0) [0|0] "" Vector__XXX
 SG_ VCRIGHT_btnWindowSwPackAutoDwnRR m0 : 52|1@1+ (1,0) [0|0] "" Vector__XXX
 SG_ VCRIGHT_liftgateShutfaceSwitchPressed m0 : 53|1@1+ (1,0) [0|0] "" Vector__XXX
 SG_ VCRIGHT_frontSeatResistiveOccupancy m1 : 54|2@1+ (1,0) [0|0] "" Vector__XXX
 SG_ VCRIGHT_rearRightOccupancySwitch m0 : 54|2@1+ (1,0) [0|0] "" Vector__XXX
 SG_ VCRIGHT_3RowLeftOccupancySwitch m0 : 56|2@1+ (1,0) [0|0] "" Vector__XXX
 SG_ VCRIGHT_3RowRightOccupancySwitch m0 : 58|2@1+ (1,0) [0|0] "" Vector__XXX
 SG_ VCRIGHT_hvacHeatingAllowedRight m1 : 59|1@1+ (1,0) [0|0] "" Vector__XXX
 SG_ VCRIGHT_3RowLeftBuckleSwitch m0 : 60|2@1+ (1,0) [0|0] "" Vector__XXX
 SG_ VCRIGHT_3RowRightBuckleSwitch m0 : 62|2@1+ (1,0) [0|0] "" Vector__XXX

BO_ 969 APS_status: 8 Vector__XXX
 SG_ APS_appStatusMonitorState : 0|3@1+ (1,0) [0|0] "" Vector__XXX
 SG_ APS_vehBehaviorState : 4|4@1+ (1,0) [0|0] "" Vector__XXX
 SG_ APS_canMaster : 8|2@1+ (1,0) [0|0] "" Vector__XXX
 SG_ APS_appGpioState : 10|2@1+ (1,0) [0|0] "" Vector__XXX
 SG_ APS_eacInternalState : 12|3@1+ (1,0) [0|0] "" Vector__XXX
 SG_ APS_switchState : 15|1@1+ (1,0) [0|0] "" Vector__XXX
 SG_ APS_apbStatusMonitorState : 16|3@1+ (1,0) [0|0] "" Vector__XXX
 SG_ APS_apbGpioState : 20|2@1+ (1,0) [0|0] "" Vector__XXX
 SG_ APS_statusCounter : 22|4@1+ (1,0) [0|0] "" Vector__XXX
 SG_ APS_locLimitReason : 26|3@1+ (1,0) [0|0] "" Vector__XXX
 SG_ APS_appPowerStateRequest : 29|2@1+ (1,0) [0|0] "" Vector__XXX
 SG_ APS_appPowerStateReason : 31|4@1+ (1,0) [0|0] "" Vector__XXX
 SG_ APS_apbPowerStateRequest : 36|2@1+ (1,0) [0|0] "" Vector__XXX
 SG_ APS_apbPowerStateReason : 38|4@1+ (1,0) [0|0] "" Vector__XXX
 SG_ APS_heaterStateDebug : 43|3@1+ (1,0) [0|0] "" Vector__XXX
 SG_ APS_autosummonCounter : 46|3@1+ (1,0) [0|0] "" Vector__XXX
 SG_ APS_autosummonAlert : 49|1@1+ (1,0) [0|0] "" Vector__XXX
 SG_ APS_gpsAntennaState : 50|2@1+ (1,0) [0|0] "" Vector__XXX
 SG_ APS_arbState : 52|3@1+ (1,0) [0|0] "" Vector__XXX
 SG_ APS_socPowerOperatingMode : 55|2@1+ (1,0) [0|0] "" Vector__XXX
 SG_ APS_otherArbState : 57|3@1+ (1,0) [0|0] "" Vector__XXX

BO_ 970 DAS_gpsStatus: 8 Vector__XXX
 SG_ DAS_gpsStatusMultiplexer M : 0|4@1+ (1,0) [0|0] "" Vector__XXX
 SG_ DAS_gnssMaxInstantaneousCnorGps m2 : 4|6@1+ (1,0) [0|0] "" Vector__XXX
 SG_ DAS_gnssNumSatsGps m3 : 4|4@1+ (1,0) [0|0] "" Vector__XXX
 SG_ DAS_gpsRxmRawxMia m1 : 4|1@1+ (1,0) [0|0] "" Vector__XXX
 SG_ DAS_gpsTransportModeState m0 : 4|1@1+ (1,0) [0|0] "" Vector__XXX
 SG_ DAS_gpsRxmSfrbxMia m1 : 5|1@1+ (1,0) [0|0] "" Vector__XXX
 SG_ DAS_gpsSatsInUseHardware m0 : 5|4@1+ (1,0) [0|0] "" Vector__XXX
 SG_ DAS_gpsEsfMeasMia m1 : 6|1@1+ (1,0) [0|0] "" Vector__XXX
 SG_ DAS_gpsEsfRawMia m1 : 7|1@1+ (1,0) [0|0] "" Vector__XXX
 SG_ DAS_gnssNumSatsGal m3 : 8|4@1+ (1,0) [0|0] "" Vector__XXX
 SG_ DAS_gpsNavStatusMia m1 : 8|1@1+ (1,0) [0|0] "" Vector__XXX
 SG_ DAS_gpsSoftwareConfigured m1 : 9|1@1+ (1,0) [0|0] "" Vector__XXX
 SG_ DAS_gpsWheeltickCounter m0 : 9|16@1+ (1,0) [0|0] "" Vector__XXX
 SG_ DAS_gnssMaxInstantaneousCnorGal m2 : 10|6@1+ (1,0) [0|0] "" Vector__XXX
 SG_ DAS_gpsSoftwareUsed m1 : 10|1@1+ (1,0) [0|0] "" Vector__XXX
 SG_ DAS_gpsSoftwareFastStartReady m1 : 11|1@1+ (1,0) [0|0] "" Vector__XXX
 SG_ DAS_gnssNumSatsBds m3 : 12|4@1+ (1,0) [0|0] "" Vector__XXX
 SG_ DAS_gpsSatsInUseSoftware m1 : 12|4@1+ (1,0) [0|0] "" Vector__XXX
 SG_ DAS_gnssAvgInstantaneousCnorGps m3 : 16|6@1+ (1,0) [0|0] "" Vector__XXX
 SG_ DAS_gnssMaxInstantaneousCnorBds m2 : 16|6@1+ (1,0) [0|0] "" Vector__XXX
 SG_ DAS_gpsFixTypeSoftware m1 : 16|3@1+ (1,0) [0|0] "" Vector__XXX
 SG_ DAS_gpsCWJammingInidcator m1 : 19|5@1+ (8,0) [0|0] "" Vector__XXX
 SG_ DAS_gnssAvgInstantaneousCnorGal m3 : 22|6@1+ (1,0) [0|0] "" Vector__XXX
 SG_ DAS_gpsResetReason m2 : 22|4@1+ (1,0) [0|0] "" Vector__XXX
 SG_ DAS_gpsJammingState m1 : 24|2@1+ (1,0) [0|0] "" Vector__XXX
 SG_ DAS_gpsWheeltickPulsePeriod m0 : 25|32@1+ (1,0) [0|0] "" Vector__XXX
 SG_ DAS_gpsAccuracyHorizontal m2 : 26|6@1+ (1,0) [0|0] "" Vector__XXX
 SG_ DAS_gpsSpoofDetectorState m1 : 26|2@1+ (1,0) [0|0] "" Vector__XXX
 SG_ DAS_gnssAvgInstantaneousCnorBds m3 : 28|6@1+ (1,0) [0|0] "" Vector__XXX
 SG_ DAS_gpsInvalidMsgPercentage m1 : 28|4@1+ (6,0) [0|0] "" Vector__XXX
 SG_ DAS_gnssConstellationsState m1 : 32|2@1+ (1,0) [0|0] "" Vector__XXX
 SG_ DAS_gpsAccuracyVertical m2 : 32|6@1+ (1,0) [0|0] "" Vector__XXX
 SG_ DAS_gnssAvgInstantCnorGpsSocB m3 : 34|6@1+ (1,0) [0|0] "" Vector__XXX
 SG_ DAS_gpsReceiverNoiseLevel m1 : 34|6@1+ (8,0) [0|0] "" Vector__XXX
 SG_ DAS_gpsSolutionFallback m2 : 38|1@1+ (1,0) [0|0] "" Vector__XXX
 SG_ DAS_gpsToMcuSource m2 : 39|3@1+ (1,0) [0|0] "" Vector__XXX
 SG_ DAS_gnssAvgInstantCnorBdsSocB m3 : 40|6@1+ (1,0) [0|0] "" Vector__XXX
 SG_ DAS_gpsAutomaticGainControl m1 : 40|8@1+ (32,0) [0|0] "" Vector__XXX
 SG_ DAS_gpsSolutionSoc m2 : 42|2@1+ (1,0) [0|0] "" Vector__XXX
 SG_ DAS_gpsRedundancyActive m2 : 44|1@1+ (1,0) [0|0] "" Vector__XXX
 SG_ DAS_gpsFixTypeSoftwareSocB m2 : 45|3@1+ (1,0) [0|0] "" Vector__XXX
 SG_ DAS_gnssAvgInstantaneousCnorGpsLowBand m3 : 46|6@1+ (1,0) [0|0] "" Vector__XXX
 SG_ DAS_gpsPreviousPositionDeltaHw m1 : 48|6@1+ (3,0) [0|0] "" Vector__XXX
 SG_ DAS_gpsSatsInUseSoftwareSocB m2 : 48|4@1+ (1,0) [0|0] "" Vector__XXX
 SG_ DAS_gnssAvgInstantaneousCnorGalLowBand m3 : 52|6@1+ (1,0) [0|0] "" Vector__XXX
 SG_ DAS_gpsPreviousPositionDeltaSw m1 : 54|6@1+ (3,0) [0|0] "" Vector__XXX
 SG_ DAS_gpsRejectingSatData m0 : 57|1@1+ (1,0) [0|0] "" Vector__XXX
 SG_ DAS_gnssAvgInstantaneousCnorBdsLowBand m3 : 58|6@1+ (1,0) [0|0] "" Vector__XXX
 SG_ DAS_gpsWheelsOffMotionDetected m0 : 58|1@1+ (1,0) [0|0] "" Vector__XXX
 SG_ DAS_gpsFixTypeHardware m0 : 59|3@1+ (1,0) [0|0] "" Vector__XXX
 SG_ DAS_gpsNmeaDispatchFailureCount m1 : 60|4@1+ (5,0) [0|0] "" Vector__XXX
 SG_ DAS_gpsRawxEnabled m0 : 62|1@1+ (1,0) [0|0] "" Vector__XXX

BO_ 971 APS_summonStatus: 8 Vector__XXX
 SG_ APS_smartSummonActive : 0|1@1+ (1,0) [0|0] "" Vector__XXX
 SG_ APS_apcInternalState : 1|4@1+ (1,0) [0|0] "" Vector__XXX
 SG_ APS_heartBeatCheckActive : 5|1@1+ (1,0) [0|0] "" Vector__XXX
 SG_ APS_apcAbortCode : 8|6@1+ (1,0) [0|0] "" Vector__XXX
 SG_ APS_summonSetSpeed : 14|7@1+ (0.1,0) [0|0] "" Vector__XXX
 SG_ APS_collisionDistance : 21|7@1+ (0.05,0) [0|0] "" Vector__XXX
 SG_ APS_collisionCheckActive : 28|1@1+ (1,0) [0|0] "" Vector__XXX
 SG_ APS_ttcCheckActive : 29|1@1+ (1,0) [0|0] "" Vector__XXX
 SG_ APS_watchDogCheckActive : 30|1@1+ (1,0) [0|0] "" Vector__XXX
 SG_ APS_noOpCheckActive : 31|1@1+ (1,0) [0|0] "" Vector__XXX
 SG_ APS_gearChangeClamp : 32|1@1+ (1,0) [0|0] "" Vector__XXX
 SG_ APS_miaCheckActive : 33|1@1+ (1,0) [0|0] "" Vector__XXX
 SG_ APS_r79BLECheckActive : 34|1@1+ (1,0) [0|0] "" Vector__XXX

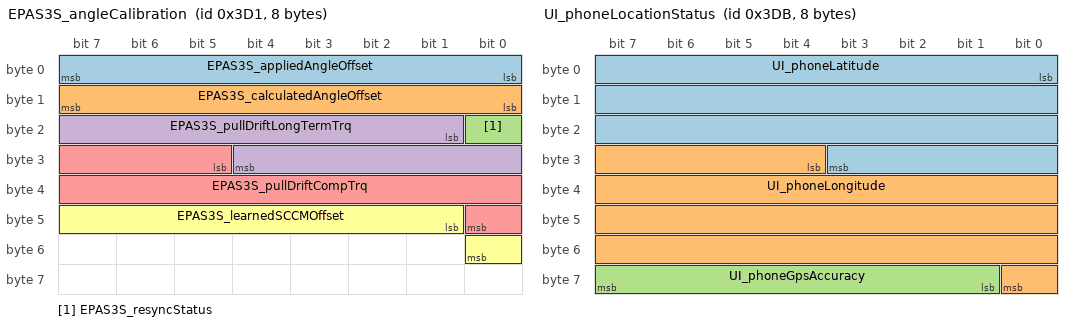
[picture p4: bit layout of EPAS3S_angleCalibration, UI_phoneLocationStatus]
BO_ 977 EPAS3S_angleCalibration: 8 Vector__XXX
 SG_ EPAS3S_appliedAngleOffset : 0|8@1+ (0.1,-12.8) [0|0] "" Vector__XXX
 SG_ EPAS3S_calculatedAngleOffset : 8|8@1+ (0.1,-12.8) [0|0] "" Vector__XXX
 SG_ EPAS3S_resyncStatus : 16|1@1+ (1,0) [0|0] "" Vector__XXX
 SG_ EPAS3S_pullDriftLongTermTrq : 17|12@1+ (0.01,-10) [0|0] "" Vector__XXX
 SG_ EPAS3S_pullDriftCompTrq : 29|12@1+ (0.01,-10) [0|0] "" Vector__XXX
 SG_ EPAS3S_learnedSCCMOffset : 41|8@1+ (0.1,-12.8) [0|0] "" Vector__XXX

BO_ 981 ESP_alertMatrix: 8 Vector__XXX
 SG_ ESP_matrixIndex M : 0|4@1+ (1,0) [0|0] "" Vector__XXX
 SG_ ESP_a001_ecuGenericFault m0 : 4|1@1+ (1,0) [0|0] "" Vector__XXX
 SG_ ESP_a061_ReLWSSSignalNoise m1 : 4|1@1+ (1,0) [0|0] "" Vector__XXX
 SG_ ESP_a121_regenTcActive m2 : 4|1@1+ (1,0) [0|0] "" Vector__XXX
 SG_ ESP_a181_IBSTparty2DLC m3 : 4|1@1+ (1,0) [0|0] "" Vector__XXX
 SG_ ESP_a241_LVPowerStateChecksum m4 : 4|1@1+ (1,0) [0|0] "" Vector__XXX
 SG_ ESP_a301_PEPSstatusCounter m5 : 4|1@1+ (1,0) [0|0] "" Vector__XXX
 SG_ ESP_a002_valvesGenericFault m0 : 5|1@1+ (1,0) [0|0] "" Vector__XXX
 SG_ ESP_a062_ReLWSSVDiffFault m1 : 5|1@1+ (1,0) [0|0] "" Vector__XXX
 SG_ ESP_a122_bdwActive m2 : 5|1@1+ (1,0) [0|0] "" Vector__XXX
 SG_ ESP_a182_IBSTparty2Counter m3 : 5|1@1+ (1,0) [0|0] "" Vector__XXX
 SG_ ESP_a242_LVPowerStateDLC m4 : 5|1@1+ (1,0) [0|0] "" Vector__XXX
 SG_ ESP_a302_rearRoadWheelAngleHealthDegraded m5 : 5|1@1+ (1,0) [0|0] "" Vector__XXX
 SG_ ESP_a003_outletValvesFault m0 : 6|1@1+ (1,0) [0|0] "" Vector__XXX
 SG_ ESP_a063_ReLWSSDirectionFault m1 : 6|1@1+ (1,0) [0|0] "" Vector__XXX
 SG_ ESP_a123_ebrActive m2 : 6|1@1+ (1,0) [0|0] "" Vector__XXX
 SG_ ESP_a183_IBSTStatusOff m3 : 6|1@1+ (1,0) [0|0] "" Vector__XXX
 SG_ ESP_a243_LVPowerStateCounter m4 : 6|1@1+ (1,0) [0|0] "" Vector__XXX
 SG_ ESP_a303_rearRoadWheelAngleHealthFaulted m5 : 6|1@1+ (1,0) [0|0] "" Vector__XXX
 SG_ ESP_a004_inletValvesFault m0 : 7|1@1+ (1,0) [0|0] "" Vector__XXX
 SG_ ESP_a064_ReLWSSLargeAirGap m1 : 7|1@1+ (1,0) [0|0] "" Vector__XXX
 SG_ ESP_a124_ebrSkidActive m2 : 7|1@1+ (1,0) [0|0] "" Vector__XXX
 SG_ ESP_a184_IBSTpRunoutInvalid m3 : 7|1@1+ (1,0) [0|0] "" Vector__XXX
 SG_ ESP_a244_LVOffStateInvalid m4 : 7|1@1+ (1,0) [0|0] "" Vector__XXX
 SG_ ESP_a304_rearVCLVPowerStateTimeout m5 : 7|1@1+ (1,0) [0|0] "" Vector__XXX
 SG_ ESP_a005_HSVValvesFault m0 : 8|1@1+ (1,0) [0|0] "" Vector__XXX
 SG_ ESP_a065_ReLWSSSupplyShortToGnd m1 : 8|1@1+ (1,0) [0|0] "" Vector__XXX
 SG_ ESP_a125_reserved125 m2 : 8|1@1+ (1,0) [0|0] "" Vector__XXX
 SG_ ESP_a185_IBSTFeedforwardBackup m3 : 8|1@1+ (1,0) [0|0] "" Vector__XXX
 SG_ ESP_a245_LVGoingDownStateInvalid m4 : 8|1@1+ (1,0) [0|0] "" Vector__XXX
 SG_ ESP_a305_rearVCLVPowerStateDLC m5 : 8|1@1+ (1,0) [0|0] "" Vector__XXX
 SG_ ESP_a006_USVValvesFault m0 : 9|1@1+ (1,0) [0|0] "" Vector__XXX
 SG_ ESP_a066_ReLWSSGeneralFault m1 : 9|1@1+ (1,0) [0|0] "" Vector__XXX
 SG_ ESP_a126_reserved126 m2 : 9|1@1+ (1,0) [0|0] "" Vector__XXX
 SG_ ESP_a186_IBSTBrakeAppliedInvalid m3 : 9|1@1+ (1,0) [0|0] "" Vector__XXX
 SG_ ESP_a246_VCFRONTsensorTimeout m4 : 9|1@1+ (1,0) [0|0] "" Vector__XXX
 SG_ ESP_a306_rearVCLVPowerStateChecksum m5 : 9|1@1+ (1,0) [0|0] "" Vector__XXX
 SG_ ESP_a007_pumpMotorFault m0 : 10|1@1+ (1,0) [0|0] "" Vector__XXX
 SG_ ESP_a067_ReRWSSOpenOrShortToGnd m1 : 10|1@1+ (1,0) [0|0] "" Vector__XXX
 SG_ ESP_a127_reserved127 m2 : 10|1@1+ (1,0) [0|0] "" Vector__XXX
 SG_ ESP_a187_DIbtcRequestTimeout m3 : 10|1@1+ (1,0) [0|0] "" Vector__XXX
 SG_ ESP_a247_VCFRONTsensorDLC m4 : 10|1@1+ (1,0) [0|0] "" Vector__XXX
 SG_ ESP_a307_rearVCLVPowerStateCounter m5 : 10|1@1+ (1,0) [0|0] "" Vector__XXX
 SG_ ESP_a008_pumpMotor12VsupplyLow m0 : 11|1@1+ (1,0) [0|0] "" Vector__XXX
 SG_ ESP_a068_ReRWSSShortTo12V m1 : 11|1@1+ (1,0) [0|0] "" Vector__XXX
 SG_ ESP_a128_reserved128 m2 : 11|1@1+ (1,0) [0|0] "" Vector__XXX
 SG_ ESP_a188_DIbtcRequestDLC m3 : 11|1@1+ (1,0) [0|0] "" Vector__XXX
 SG_ ESP_a248_vdcBrkeTrqTarFrLInvalid m4 : 11|1@1+ (1,0) [0|0] "" Vector__XXX
 SG_ ESP_a308_evacFillNotComplete m5 : 11|1@1+ (1,0) [0|0] "" Vector__XXX
 SG_ ESP_a009_12VHardUndervoltage m0 : 12|1@1+ (1,0) [0|0] "" Vector__XXX
 SG_ ESP_a069_ReRWSSLineInterruption m1 : 12|1@1+ (1,0) [0|0] "" Vector__XXX
 SG_ ESP_a129_reserved129 m2 : 12|1@1+ (1,0) [0|0] "" Vector__XXX
 SG_ ESP_a189_DIbtcRequestChecksum m3 : 12|1@1+ (1,0) [0|0] "" Vector__XXX
 SG_ ESP_a249_vdcBrkeTrqTarFrRInvalid m4 : 12|1@1+ (1,0) [0|0] "" Vector__XXX
 SG_ ESP_a309_factoryModeActive m5 : 12|1@1+ (1,0) [0|0] "" Vector__XXX
 SG_ ESP_a010_12VUndervoltage m0 : 13|1@1+ (1,0) [0|0] "" Vector__XXX
 SG_ ESP_a070_ReRWSSMaxSpeedExceeded m1 : 13|1@1+ (1,0) [0|0] "" Vector__XXX
 SG_ ESP_a130_EPAS3PsysStatusTimeout m2 : 13|1@1+ (1,0) [0|0] "" Vector__XXX
 SG_ ESP_a190_DIbtcRequestCounter m3 : 13|1@1+ (1,0) [0|0] "" Vector__XXX
 SG_ ESP_a250_vdcBrkeTrqTarReLInvalid m4 : 13|1@1+ (1,0) [0|0] "" Vector__XXX
 SG_ ESP_a310_brakeLatencyReductionActive m5 : 13|1@1+ (1,0) [0|0] "" Vector__XXX
 SG_ ESP_a011_12VSystemUndervoltage m0 : 14|1@1+ (1,0) [0|0] "" Vector__XXX
 SG_ ESP_a071_ReRWSSTooManyPulses m1 : 14|1@1+ (1,0) [0|0] "" Vector__XXX
 SG_ ESP_a131_EPAS3PsysStatusDLC m2 : 14|1@1+ (1,0) [0|0] "" Vector__XXX
 SG_ ESP_a191_DIchassisControlTimeout m3 : 14|1@1+ (1,0) [0|0] "" Vector__XXX
 SG_ ESP_a251_vdcBrkeTrqTarReRInvalid m4 : 14|1@1+ (1,0) [0|0] "" Vector__XXX
 SG_ ESP_a311_aesActive m5 : 14|1@1+ (1,0) [0|0] "" Vector__XXX
 SG_ ESP_a012_netUndervoltage m0 : 15|1@1+ (1,0) [0|0] "" Vector__XXX
 SG_ ESP_a072_ReRWSSLostSignal m1 : 15|1@1+ (1,0) [0|0] "" Vector__XXX
 SG_ ESP_a132_EPAS3PsysStatusChecksum m2 : 15|1@1+ (1,0) [0|0] "" Vector__XXX
 SG_ ESP_a192_DIchassisControlDLC m3 : 15|1@1+ (1,0) [0|0] "" Vector__XXX
 SG_ ESP_a252_vdcWhlSlipLimFrLInvalid m4 : 15|1@1+ (1,0) [0|0] "" Vector__XXX
 SG_ ESP_a312_undefinedAlertDetected m5 : 15|1@1+ (1,0) [0|0] "" Vector__XXX
 SG_ ESP_a013_valveRelayUndervoltage m0 : 16|1@1+ (1,0) [0|0] "" Vector__XXX
 SG_ ESP_a073_ReRWSSNoPulsesDetected m1 : 16|1@1+ (1,0) [0|0] "" Vector__XXX
 SG_ ESP_a133_EPAS3PsysStatusCounter m2 : 16|1@1+ (1,0) [0|0] "" Vector__XXX
 SG_ ESP_a193_DIchassisControlChecksum m3 : 16|1@1+ (1,0) [0|0] "" Vector__XXX
 SG_ ESP_a253_vdcWhlSlipLimFrRInvalid m4 : 16|1@1+ (1,0) [0|0] "" Vector__XXX
 SG_ ESP_a313_cdpRequestStateInvalid m5 : 16|1@1+ (1,0) [0|0] "" Vector__XXX
 SG_ ESP_a014_WSSSupplyUndervoltage m0 : 17|1@1+ (1,0) [0|0] "" Vector__XXX
 SG_ ESP_a074_ReRWSSWrongSensorType m1 : 17|1@1+ (1,0) [0|0] "" Vector__XXX
 SG_ ESP_a134_steeringAngleInvalid m2 : 17|1@1+ (1,0) [0|0] "" Vector__XXX
 SG_ ESP_a194_DIchassisControlCounter m3 : 17|1@1+ (1,0) [0|0] "" Vector__XXX
 SG_ ESP_a254_vdcWhlSlipLimReLInvalid m4 : 17|1@1+ (1,0) [0|0] "" Vector__XXX
 SG_ ESP_a314_aesFault m5 : 17|1@1+ (1,0) [0|0] "" Vector__XXX
 SG_ ESP_a015_12VSupplyOvervoltage m0 : 18|1@1+ (1,0) [0|0] "" Vector__XXX
 SG_ ESP_a075_ReRWSSSignalNoise m1 : 18|1@1+ (1,0) [0|0] "" Vector__XXX
 SG_ ESP_a135_steeringAngleNoCenter m2 : 18|1@1+ (1,0) [0|0] "" Vector__XXX
 SG_ ESP_a195_ptcStateInvalid m3 : 18|1@1+ (1,0) [0|0] "" Vector__XXX
 SG_ ESP_a255_vdcWhlSlipLimReRInvalid m4 : 18|1@1+ (1,0) [0|0] "" Vector__XXX
 SG_ ESP_a315_EMCBackup11Timeout m5 : 18|1@1+ (1,0) [0|0] "" Vector__XXX
 SG_ ESP_a016_12VSystemOvervoltage m0 : 19|1@1+ (1,0) [0|0] "" Vector__XXX
 SG_ ESP_a076_ReRWSSVDiffFault m1 : 19|1@1+ (1,0) [0|0] "" Vector__XXX
 SG_ ESP_a136_steeringAngleFrozen m2 : 19|1@1+ (1,0) [0|0] "" Vector__XXX
 SG_ ESP_a196_DIsystemStatusTimeout m3 : 19|1@1+ (1,0) [0|0] "" Vector__XXX
 SG_ ESP_a256_epbmStatusTimeout m4 : 19|1@1+ (1,0) [0|0] "" Vector__XXX
 SG_ ESP_a316_EMCBackup11DLC m5 : 19|1@1+ (1,0) [0|0] "" Vector__XXX
 SG_ ESP_a017_netOvervoltage m0 : 20|1@1+ (1,0) [0|0] "" Vector__XXX
 SG_ ESP_a077_ReRWSSDirectionFault m1 : 20|1@1+ (1,0) [0|0] "" Vector__XXX
 SG_ ESP_a137_steeringOffsetTooLarge m2 : 20|1@1+ (1,0) [0|0] "" Vector__XXX
 SG_ ESP_a197_DIsystemStatusDLC m3 : 20|1@1+ (1,0) [0|0] "" Vector__XXX
 SG_ ESP_a257_epbmStatusChecksum m4 : 20|1@1+ (1,0) [0|0] "" Vector__XXX
 SG_ ESP_a317_EMCBackup11Checksum m5 : 20|1@1+ (1,0) [0|0] "" Vector__XXX
 SG_ ESP_a018_WSSSignFrontAxle m0 : 21|1@1+ (1,0) [0|0] "" Vector__XXX
 SG_ ESP_a078_ReRWSSLargeAirGap m1 : 21|1@1+ (1,0) [0|0] "" Vector__XXX
 SG_ ESP_a138_steeringAngleImplaus m2 : 21|1@1+ (1,0) [0|0] "" Vector__XXX
 SG_ ESP_a198_DIsystemStatusChecksum m3 : 21|1@1+ (1,0) [0|0] "" Vector__XXX
 SG_ ESP_a258_epbmStatusDLC m4 : 21|1@1+ (1,0) [0|0] "" Vector__XXX
 SG_ ESP_a318_EMCBackup11Counter m5 : 21|1@1+ (1,0) [0|0] "" Vector__XXX
 SG_ ESP_a019_WSSSignRearAxle m0 : 22|1@1+ (1,0) [0|0] "" Vector__XXX
 SG_ ESP_a079_ReRWSSSupplyShortToGnd m1 : 22|1@1+ (1,0) [0|0] "" Vector__XXX
 SG_ ESP_a139_steeringAngleWrongSign m2 : 22|1@1+ (1,0) [0|0] "" Vector__XXX
 SG_ ESP_a199_DIsystemStatusCounter m3 : 22|1@1+ (1,0) [0|0] "" Vector__XXX
 SG_ ESP_a259_epbmStatusCounter m4 : 22|1@1+ (1,0) [0|0] "" Vector__XXX
 SG_ ESP_a319_AES_BackupActuatorActive m5 : 22|1@1+ (1,0) [0|0] "" Vector__XXX
 SG_ ESP_a020_WSSGenericTempFault m0 : 23|1@1+ (1,0) [0|0] "" Vector__XXX
 SG_ ESP_a080_ReRWSSGeneralFault m1 : 23|1@1+ (1,0) [0|0] "" Vector__XXX
 SG_ ESP_a140_RCMInertial1Timeout m2 : 23|1@1+ (1,0) [0|0] "" Vector__XXX
 SG_ ESP_a200_reverseGearStuckHigh m3 : 23|1@1+ (1,0) [0|0] "" Vector__XXX
 SG_ ESP_a260_epblStatusTimeout m4 : 23|1@1+ (1,0) [0|0] "" Vector__XXX
 SG_ ESP_a021_WSSGeneralVDiffFault m0 : 24|1@1+ (1,0) [0|0] "" Vector__XXX
 SG_ ESP_a081_PressureSensorShort m1 : 24|1@1+ (1,0) [0|0] "" Vector__XXX
 SG_ ESP_a141_RCMInertial1DLC m2 : 24|1@1+ (1,0) [0|0] "" Vector__XXX
 SG_ ESP_a201_reverseGearStuckLow m3 : 24|1@1+ (1,0) [0|0] "" Vector__XXX
 SG_ ESP_a261_epblStatusChecksum m4 : 24|1@1+ (1,0) [0|0] "" Vector__XXX
 SG_ ESP_a022_WSSDirectionFault m0 : 25|1@1+ (1,0) [0|0] "" Vector__XXX
 SG_ ESP_a082_PMCSensorOffsetHigh m1 : 25|1@1+ (1,0) [0|0] "" Vector__XXX
 SG_ ESP_a142_RCMInertial1Checksum m2 : 25|1@1+ (1,0) [0|0] "" Vector__XXX
 SG_ ESP_a202_accelPedalInvalid m3 : 25|1@1+ (1,0) [0|0] "" Vector__XXX
 SG_ ESP_a262_epblStatusDLC m4 : 25|1@1+ (1,0) [0|0] "" Vector__XXX
 SG_ ESP_a023_WSSSeveralSuspected m0 : 26|1@1+ (1,0) [0|0] "" Vector__XXX
 SG_ ESP_a083_PMCSensorFault m1 : 26|1@1+ (1,0) [0|0] "" Vector__XXX
 SG_ ESP_a143_RCMInertial1Counter m2 : 26|1@1+ (1,0) [0|0] "" Vector__XXX
 SG_ ESP_a203_DItorqueTimeout m3 : 26|1@1+ (1,0) [0|0] "" Vector__XXX
 SG_ ESP_a263_epblStatusCounter m4 : 26|1@1+ (1,0) [0|0] "" Vector__XXX
 SG_ ESP_a024_WSSReverseCurrent m0 : 27|1@1+ (1,0) [0|0] "" Vector__XXX
 SG_ ESP_a084_BrakeFluidReservoirLow m1 : 27|1@1+ (1,0) [0|0] "" Vector__XXX
 SG_ ESP_a144_yawMaxLatency m2 : 27|1@1+ (1,0) [0|0] "" Vector__XXX
 SG_ ESP_a204_DItorqueDLC m3 : 27|1@1+ (1,0) [0|0] "" Vector__XXX
 SG_ ESP_a264_pumpSpeedLimitInvalid m4 : 27|1@1+ (1,0) [0|0] "" Vector__XXX
 SG_ ESP_a025_FrLWSSOpenOrShortToGnd m0 : 28|1@1+ (1,0) [0|0] "" Vector__XXX
 SG_ ESP_a085_BrakeSwitchStuckHigh m1 : 28|1@1+ (1,0) [0|0] "" Vector__XXX
 SG_ ESP_a145_yawInitFault m2 : 28|1@1+ (1,0) [0|0] "" Vector__XXX
 SG_ ESP_a205_DItorqueChecksum m3 : 28|1@1+ (1,0) [0|0] "" Vector__XXX
 SG_ ESP_a265_DIRELtorqueTimeout m4 : 28|1@1+ (1,0) [0|0] "" Vector__XXX
 SG_ ESP_a026_FrLWSSShortTo12V m0 : 29|1@1+ (1,0) [0|0] "" Vector__XXX
 SG_ ESP_a086_BrakeSwitchImplausible1 m1 : 29|1@1+ (1,0) [0|0] "" Vector__XXX
 SG_ ESP_a146_yawInvalidValue m2 : 29|1@1+ (1,0) [0|0] "" Vector__XXX
 SG_ ESP_a206_DItorqueCounter m3 : 29|1@1+ (1,0) [0|0] "" Vector__XXX
 SG_ ESP_a266_DIRELtorqueDLC m4 : 29|1@1+ (1,0) [0|0] "" Vector__XXX
 SG_ ESP_a027_FrLWSSLineInterruption m0 : 30|1@1+ (1,0) [0|0] "" Vector__XXX
 SG_ ESP_a087_BrakeSwitchImplausible3 m1 : 30|1@1+ (1,0) [0|0] "" Vector__XXX
 SG_ ESP_a147_yawSensorNotAvailable m2 : 30|1@1+ (1,0) [0|0] "" Vector__XXX
 SG_ ESP_a207_DITorqueCommandInvalid m3 : 30|1@1+ (1,0) [0|0] "" Vector__XXX
 SG_ ESP_a267_DIRELtorqueChecksum m4 : 30|1@1+ (1,0) [0|0] "" Vector__XXX
 SG_ ESP_a028_FrLWSSMaxSpeedExceeded m0 : 31|1@1+ (1,0) [0|0] "" Vector__XXX
 SG_ ESP_a088_absContinuousControl m1 : 31|1@1+ (1,0) [0|0] "" Vector__XXX
 SG_ ESP_a148_yawSignalFault m2 : 31|1@1+ (1,0) [0|0] "" Vector__XXX
 SG_ ESP_a208_DIRPMInvalid m3 : 31|1@1+ (1,0) [0|0] "" Vector__XXX
 SG_ ESP_a268_DIRELtorqueCounter m4 : 31|1@1+ (1,0) [0|0] "" Vector__XXX
 SG_ ESP_a029_FrLWSSTooManyPulses m0 : 32|1@1+ (1,0) [0|0] "" Vector__XXX
 SG_ ESP_a089_absNoPressureIncrease m1 : 32|1@1+ (1,0) [0|0] "" Vector__XXX
 SG_ ESP_a149_yawInvalidSign m2 : 32|1@1+ (1,0) [0|0] "" Vector__XXX
 SG_ ESP_a209_DITorqueActualInvalid m3 : 32|1@1+ (1,0) [0|0] "" Vector__XXX
 SG_ ESP_a269_DIRELTorqueCommandInvalid m4 : 32|1@1+ (1,0) [0|0] "" Vector__XXX
 SG_ ESP_a030_FrLWSSLostSignal m0 : 33|1@1+ (1,0) [0|0] "" Vector__XXX
 SG_ ESP_a090_vdcContinuousControl m1 : 33|1@1+ (1,0) [0|0] "" Vector__XXX
 SG_ ESP_a150_yawImplausible m2 : 33|1@1+ (1,0) [0|0] "" Vector__XXX
 SG_ ESP_a210_DIStorqueTimeout m3 : 33|1@1+ (1,0) [0|0] "" Vector__XXX
 SG_ ESP_a270_DIRELRPMInvalid m4 : 33|1@1+ (1,0) [0|0] "" Vector__XXX
 SG_ ESP_a031_FrLWSSNoPulsesDetected m0 : 34|1@1+ (1,0) [0|0] "" Vector__XXX
 SG_ ESP_a091_CANUndervoltage m1 : 34|1@1+ (1,0) [0|0] "" Vector__XXX
 SG_ ESP_a151_RCMInertial2Timeout m2 : 34|1@1+ (1,0) [0|0] "" Vector__XXX
 SG_ ESP_a211_DIStorqueDLC m3 : 34|1@1+ (1,0) [0|0] "" Vector__XXX
 SG_ ESP_a271_DIRELTorqueActualInvalid m4 : 34|1@1+ (1,0) [0|0] "" Vector__XXX
 SG_ ESP_a032_FrLWSSWrongSensorType m0 : 35|1@1+ (1,0) [0|0] "" Vector__XXX
 SG_ ESP_a092_CANOvervoltage m1 : 35|1@1+ (1,0) [0|0] "" Vector__XXX
 SG_ ESP_a152_RCMInertial2DLC m2 : 35|1@1+ (1,0) [0|0] "" Vector__XXX
 SG_ ESP_a212_DIStorqueChecksum m3 : 35|1@1+ (1,0) [0|0] "" Vector__XXX
 SG_ ESP_a272_DIRERtorqueTimeout m4 : 35|1@1+ (1,0) [0|0] "" Vector__XXX
 SG_ ESP_a033_FrLWSSSignalNoise m0 : 36|1@1+ (1,0) [0|0] "" Vector__XXX
 SG_ ESP_a093_partyBusOff m1 : 36|1@1+ (1,0) [0|0] "" Vector__XXX
 SG_ ESP_a153_RCMInertial2Checksum m2 : 36|1@1+ (1,0) [0|0] "" Vector__XXX
 SG_ ESP_a213_DIStorqueCounter m3 : 36|1@1+ (1,0) [0|0] "" Vector__XXX
 SG_ ESP_a273_DIRERtorqueDLC m4 : 36|1@1+ (1,0) [0|0] "" Vector__XXX
 SG_ ESP_a034_FrLWSSVDiffFault m0 : 37|1@1+ (1,0) [0|0] "" Vector__XXX
 SG_ ESP_a094_partyBusPassive m1 : 37|1@1+ (1,0) [0|0] "" Vector__XXX
 SG_ ESP_a154_RCMInertial2Counter m2 : 37|1@1+ (1,0) [0|0] "" Vector__XXX
 SG_ ESP_a214_DISTorqueCommandInvalid m3 : 37|1@1+ (1,0) [0|0] "" Vector__XXX
 SG_ ESP_a274_DIRERtorqueChecksum m4 : 37|1@1+ (1,0) [0|0] "" Vector__XXX
 SG_ ESP_a035_FrLWSSDirectionFault m0 : 38|1@1+ (1,0) [0|0] "" Vector__XXX
 SG_ ESP_a095_chassisBusOff m1 : 38|1@1+ (1,0) [0|0] "" Vector__XXX
 SG_ ESP_a155_ayMaxLatency m2 : 38|1@1+ (1,0) [0|0] "" Vector__XXX
 SG_ ESP_a215_DISRPMInvalid m3 : 38|1@1+ (1,0) [0|0] "" Vector__XXX
 SG_ ESP_a275_DIRERtorqueCounter m4 : 38|1@1+ (1,0) [0|0] "" Vector__XXX
 SG_ ESP_a036_FrLWSSLargeAirGap m0 : 39|1@1+ (1,0) [0|0] "" Vector__XXX
 SG_ ESP_a096_chassisBusPassive m1 : 39|1@1+ (1,0) [0|0] "" Vector__XXX
 SG_ ESP_a156_ayInitFault m2 : 39|1@1+ (1,0) [0|0] "" Vector__XXX
 SG_ ESP_a216_DISTorqueActualInvalid m3 : 39|1@1+ (1,0) [0|0] "" Vector__XXX
 SG_ ESP_a276_DIRERTorqueCommandInvalid m4 : 39|1@1+ (1,0) [0|0] "" Vector__XXX
 SG_ ESP_a037_FrLWSSSupplyShortToGnd m0 : 40|1@1+ (1,0) [0|0] "" Vector__XXX
 SG_ ESP_a097_tcsRefSpeedNotInit m1 : 40|1@1+ (1,0) [0|0] "" Vector__XXX
 SG_ ESP_a157_ayInvalidValue m2 : 40|1@1+ (1,0) [0|0] "" Vector__XXX
 SG_ ESP_a217_DIvdcLeftTimeout m3 : 40|1@1+ (1,0) [0|0] "" Vector__XXX
 SG_ ESP_a277_DIRERRPMInvalid m4 : 40|1@1+ (1,0) [0|0] "" Vector__XXX
 SG_ ESP_a038_FrLWSSGeneralFault m0 : 41|1@1+ (1,0) [0|0] "" Vector__XXX
 SG_ ESP_a098_vdcRefSpeedNotInit m1 : 41|1@1+ (1,0) [0|0] "" Vector__XXX
 SG_ ESP_a158_aySensorNotAvailable m2 : 41|1@1+ (1,0) [0|0] "" Vector__XXX
 SG_ ESP_a218_DIvdcLeftDLC m3 : 41|1@1+ (1,0) [0|0] "" Vector__XXX
 SG_ ESP_a278_DIRERTorqueActualInvalid m4 : 41|1@1+ (1,0) [0|0] "" Vector__XXX
 SG_ ESP_a039_FrRWSSOpenOrShortToGnd m0 : 42|1@1+ (1,0) [0|0] "" Vector__XXX
 SG_ ESP_a099_brakeTempModelOverheat m1 : 42|1@1+ (1,0) [0|0] "" Vector__XXX
 SG_ ESP_a159_aySignalFault m2 : 42|1@1+ (1,0) [0|0] "" Vector__XXX
 SG_ ESP_a219_DIvdcLeftChecksum m3 : 42|1@1+ (1,0) [0|0] "" Vector__XXX
 SG_ ESP_a279_lifetimeManagementOverrun m4 : 42|1@1+ (1,0) [0|0] "" Vector__XXX
 SG_ ESP_a040_FrRWSSShortTo12V m0 : 43|1@1+ (1,0) [0|0] "" Vector__XXX
 SG_ ESP_a100_brakeTempModelDisabled m1 : 43|1@1+ (1,0) [0|0] "" Vector__XXX
 SG_ ESP_a160_ayRangeExceeded m2 : 43|1@1+ (1,0) [0|0] "" Vector__XXX
 SG_ ESP_a220_DIvdcLeftCounter m3 : 43|1@1+ (1,0) [0|0] "" Vector__XXX
 SG_ ESP_a280_trackModeABSEnabled m4 : 43|1@1+ (1,0) [0|0] "" Vector__XXX
 SG_ ESP_a041_FrRWSSLineInterruption m0 : 44|1@1+ (1,0) [0|0] "" Vector__XXX
 SG_ ESP_a101_ebdFault m1 : 44|1@1+ (1,0) [0|0] "" Vector__XXX
 SG_ ESP_a161_ayOffsetExceeded m2 : 44|1@1+ (1,0) [0|0] "" Vector__XXX
 SG_ ESP_a221_DIvdcRightTimeout m3 : 44|1@1+ (1,0) [0|0] "" Vector__XXX
 SG_ ESP_a281_trackModeABSdisabled m4 : 44|1@1+ (1,0) [0|0] "" Vector__XXX
 SG_ ESP_a042_FrRWSSMaxSpeedExceeded m0 : 45|1@1+ (1,0) [0|0] "" Vector__XXX
 SG_ ESP_a102_absFault m1 : 45|1@1+ (1,0) [0|0] "" Vector__XXX
 SG_ ESP_a162_ayImplausible m2 : 45|1@1+ (1,0) [0|0] "" Vector__XXX
 SG_ ESP_a222_DIvdcRightDLC m3 : 45|1@1+ (1,0) [0|0] "" Vector__XXX
 SG_ ESP_a282_trackModeABSRequestInvalid m4 : 45|1@1+ (1,0) [0|0] "" Vector__XXX
 SG_ ESP_a043_FrRWSSTooManyPulses m0 : 46|1@1+ (1,0) [0|0] "" Vector__XXX
 SG_ ESP_a103_stabilityControlFault m1 : 46|1@1+ (1,0) [0|0] "" Vector__XXX
 SG_ ESP_a163_axMaxLatency m2 : 46|1@1+ (1,0) [0|0] "" Vector__XXX
 SG_ ESP_a223_DIvdcRightChecksum m3 : 46|1@1+ (1,0) [0|0] "" Vector__XXX
 SG_ ESP_a283_secondaryCollisionMitigationActive m4 : 46|1@1+ (1,0) [0|0] "" Vector__XXX
 SG_ ESP_a044_FrRWSSLostSignal m0 : 47|1@1+ (1,0) [0|0] "" Vector__XXX
 SG_ ESP_a104_hbcEnabled m1 : 47|1@1+ (1,0) [0|0] "" Vector__XXX
 SG_ ESP_a164_axInitFault m2 : 47|1@1+ (1,0) [0|0] "" Vector__XXX
 SG_ ESP_a224_DIvdcRightCounter m3 : 47|1@1+ (1,0) [0|0] "" Vector__XXX
 SG_ ESP_a284_scmRequestInvalidChecksum m4 : 47|1@1+ (1,0) [0|0] "" Vector__XXX
 SG_ ESP_a045_FrRWSSNoPulsesDetected m0 : 48|1@1+ (1,0) [0|0] "" Vector__XXX
 SG_ ESP_a105_ebrFault m1 : 48|1@1+ (1,0) [0|0] "" Vector__XXX
 SG_ ESP_a165_axInvalidValue m2 : 48|1@1+ (1,0) [0|0] "" Vector__XXX
 SG_ ESP_a225_configMismatch m3 : 48|1@1+ (1,0) [0|0] "" Vector__XXX
 SG_ ESP_a285_scmRequestDLC m4 : 48|1@1+ (1,0) [0|0] "" Vector__XXX
 SG_ ESP_a046_FrRWSSWrongSensorType m0 : 49|1@1+ (1,0) [0|0] "" Vector__XXX
 SG_ ESP_a106_vdcActuatorFault m1 : 49|1@1+ (1,0) [0|0] "" Vector__XXX
 SG_ ESP_a166_axSensorNotAvailable m2 : 49|1@1+ (1,0) [0|0] "" Vector__XXX
 SG_ ESP_a226_bdwRequestInvalid m3 : 49|1@1+ (1,0) [0|0] "" Vector__XXX
 SG_ ESP_a286_hydroplaneDetected m4 : 49|1@1+ (1,0) [0|0] "" Vector__XXX
 SG_ ESP_a047_FrRWSSSignalNoise m0 : 50|1@1+ (1,0) [0|0] "" Vector__XXX
 SG_ ESP_a107_reserved107 m1 : 50|1@1+ (1,0) [0|0] "" Vector__XXX
 SG_ ESP_a167_axSignalFault m2 : 50|1@1+ (1,0) [0|0] "" Vector__XXX
 SG_ ESP_a227_bdwRequestActiveInvalid m3 : 50|1@1+ (1,0) [0|0] "" Vector__XXX
 SG_ ESP_a287_failedBrakeCircuitDetected m4 : 50|1@1+ (1,0) [0|0] "" Vector__XXX
 SG_ ESP_a048_FrRWSSVDiffFault m0 : 51|1@1+ (1,0) [0|0] "" Vector__XXX
 SG_ ESP_a108_reserved108 m1 : 51|1@1+ (1,0) [0|0] "" Vector__XXX
 SG_ ESP_a168_axRangeExceeded m2 : 51|1@1+ (1,0) [0|0] "" Vector__XXX
 SG_ ESP_a228_GTWvinTimeout m3 : 51|1@1+ (1,0) [0|0] "" Vector__XXX
 SG_ ESP_a288_leftBusOff m4 : 51|1@1+ (1,0) [0|0] "" Vector__XXX
 SG_ ESP_a049_FrRWSSDirectionFault m0 : 52|1@1+ (1,0) [0|0] "" Vector__XXX
 SG_ ESP_a109_reserved109 m1 : 52|1@1+ (1,0) [0|0] "" Vector__XXX
 SG_ ESP_a169_axOffsetExceeded m2 : 52|1@1+ (1,0) [0|0] "" Vector__XXX
 SG_ ESP_a229_GTWvinDLC m3 : 52|1@1+ (1,0) [0|0] "" Vector__XXX
 SG_ ESP_a289_leftBusPassive m4 : 52|1@1+ (1,0) [0|0] "" Vector__XXX
 SG_ ESP_a050_FrRWSSLargeAirGap m0 : 53|1@1+ (1,0) [0|0] "" Vector__XXX
 SG_ ESP_a110_rollerBenchActive m1 : 53|1@1+ (1,0) [0|0] "" Vector__XXX
 SG_ ESP_a170_axSignalFrozen m2 : 53|1@1+ (1,0) [0|0] "" Vector__XXX
 SG_ ESP_a230_vinNotLearned m3 : 53|1@1+ (1,0) [0|0] "" Vector__XXX
 SG_ ESP_a290_brakeBusOff m4 : 53|1@1+ (1,0) [0|0] "" Vector__XXX
 SG_ ESP_a051_FrRWSSSupplyShortToGnd m0 : 54|1@1+ (1,0) [0|0] "" Vector__XXX
 SG_ ESP_a111_absActive m1 : 54|1@1+ (1,0) [0|0] "" Vector__XXX
 SG_ ESP_a171_axImplausible m2 : 54|1@1+ (1,0) [0|0] "" Vector__XXX
 SG_ ESP_a231_storedVINMismatch m3 : 54|1@1+ (1,0) [0|0] "" Vector__XXX
 SG_ ESP_a291_brakeBusPassive m4 : 54|1@1+ (1,0) [0|0] "" Vector__XXX
 SG_ ESP_a052_FrRWSSGeneralFault m0 : 55|1@1+ (1,0) [0|0] "" Vector__XXX
 SG_ ESP_a112_espActive m1 : 55|1@1+ (1,0) [0|0] "" Vector__XXX
 SG_ ESP_a172_IBSTparty1Timeout m2 : 55|1@1+ (1,0) [0|0] "" Vector__XXX
 SG_ ESP_a232_PMstate2Timeout m3 : 55|1@1+ (1,0) [0|0] "" Vector__XXX
 SG_ ESP_a292_PEPSstatusTimeout m4 : 55|1@1+ (1,0) [0|0] "" Vector__XXX
 SG_ ESP_a053_ReLWSSOpenOrShortToGnd m0 : 56|1@1+ (1,0) [0|0] "" Vector__XXX
 SG_ ESP_a113_btcActive m1 : 56|1@1+ (1,0) [0|0] "" Vector__XXX
 SG_ ESP_a173_IBSTparty1DLC m2 : 56|1@1+ (1,0) [0|0] "" Vector__XXX
 SG_ ESP_a233_PMstate2Checksum m3 : 56|1@1+ (1,0) [0|0] "" Vector__XXX
 SG_ ESP_a293_PEPSstatusDLC m4 : 56|1@1+ (1,0) [0|0] "" Vector__XXX
 SG_ ESP_a054_ReLWSSShortTo12V m0 : 57|1@1+ (1,0) [0|0] "" Vector__XXX
 SG_ ESP_a114_tvdcActive m1 : 57|1@1+ (1,0) [0|0] "" Vector__XXX
 SG_ ESP_a174_IBSTparty1Checksum m2 : 57|1@1+ (1,0) [0|0] "" Vector__XXX
 SG_ ESP_a234_PMstate2DLC m3 : 57|1@1+ (1,0) [0|0] "" Vector__XXX
 SG_ ESP_a294_PEPSstatusChecksum m4 : 57|1@1+ (1,0) [0|0] "" Vector__XXX
 SG_ ESP_a055_ReLWSSLineInterruption m0 : 58|1@1+ (1,0) [0|0] "" Vector__XXX
 SG_ ESP_a115_ebdActive m1 : 58|1@1+ (1,0) [0|0] "" Vector__XXX
 SG_ ESP_a175_IBSTparty1Counter m2 : 58|1@1+ (1,0) [0|0] "" Vector__XXX
 SG_ ESP_a235_PMstate2Counter m3 : 58|1@1+ (1,0) [0|0] "" Vector__XXX
 SG_ ESP_a295_PEPSstatusCounter m4 : 58|1@1+ (1,0) [0|0] "" Vector__XXX
 SG_ ESP_a056_ReLWSSMaxSpeedExceeded m0 : 59|1@1+ (1,0) [0|0] "" Vector__XXX
 SG_ ESP_a116_tsmActive m1 : 59|1@1+ (1,0) [0|0] "" Vector__XXX
 SG_ ESP_a176_IBSTEBRNotAvailable m2 : 59|1@1+ (1,0) [0|0] "" Vector__XXX
 SG_ ESP_a236_ebrCommandStateInvalid m3 : 59|1@1+ (1,0) [0|0] "" Vector__XXX
 SG_ ESP_a296_roadWheelAngleHealthDegraded m4 : 59|1@1+ (1,0) [0|0] "" Vector__XXX
 SG_ ESP_a057_ReLWSSTooManyPulses m0 : 60|1@1+ (1,0) [0|0] "" Vector__XXX
 SG_ ESP_a117_hbaActive m1 : 60|1@1+ (1,0) [0|0] "" Vector__XXX
 SG_ ESP_a177_IBSTOutputRodDrvInvalid m2 : 60|1@1+ (1,0) [0|0] "" Vector__XXX
 SG_ ESP_a237_vdcCommandStateInvalid m3 : 60|1@1+ (1,0) [0|0] "" Vector__XXX
 SG_ ESP_a297_roadWheelAngleHealthFaulted m4 : 60|1@1+ (1,0) [0|0] "" Vector__XXX
 SG_ ESP_a058_ReLWSSLostSignal m0 : 61|1@1+ (1,0) [0|0] "" Vector__XXX
 SG_ ESP_a118_hfcActive m1 : 61|1@1+ (1,0) [0|0] "" Vector__XXX
 SG_ ESP_a178_IBSTOutputRodActInvalid m2 : 61|1@1+ (1,0) [0|0] "" Vector__XXX
 SG_ ESP_a238_UIodoTimeout m3 : 61|1@1+ (1,0) [0|0] "" Vector__XXX
 SG_ ESP_a298_RSArearSteerStatusTimeout m4 : 61|1@1+ (1,0) [0|0] "" Vector__XXX
 SG_ ESP_a059_ReLWSSNoPulsesDetected m0 : 62|1@1+ (1,0) [0|0] "" Vector__XXX
 SG_ ESP_a119_hbbActive m1 : 62|1@1+ (1,0) [0|0] "" Vector__XXX
 SG_ ESP_a179_IBSTparty2Timeout m2 : 62|1@1+ (1,0) [0|0] "" Vector__XXX
 SG_ ESP_a239_UIodoDLC m3 : 62|1@1+ (1,0) [0|0] "" Vector__XXX
 SG_ ESP_a299_RSArearSteerStatusDLC m4 : 62|1@1+ (1,0) [0|0] "" Vector__XXX
 SG_ ESP_a060_ReLWSSWrongSensorType m0 : 63|1@1+ (1,0) [0|0] "" Vector__XXX
 SG_ ESP_a120_rmiActive m1 : 63|1@1+ (1,0) [0|0] "" Vector__XXX
 SG_ ESP_a180_IBSTparty2Checksum m2 : 63|1@1+ (1,0) [0|0] "" Vector__XXX
 SG_ ESP_a240_LVPowerStateTimeout m3 : 63|1@1+ (1,0) [0|0] "" Vector__XXX
 SG_ ESP_a300_RSArearSteerStatusChecksum m4 : 63|1@1+ (1,0) [0|0] "" Vector__XXX

BO_ 985 UI_locationOffset: 8 Vector__XXX
 SG_ UI_latitudeOffset : 0|28@1- (1e-06,0) [0|0] "" Vector__XXX
 SG_ UI_longitudeOffset : 28|29@1- (1e-06,0) [0|0] "" Vector__XXX

BO_ 986 DAS_telemetryEvent: 8 Vector__XXX
 SG_ DAS_TE_multiplexer M : 0|5@1+ (1,0) [0|0] "" Vector__XXX
 SG_ DAS_TE_accCounter m6 : 5|3@1+ (1,0) [0|0] "" Vector__XXX
 SG_ DAS_TE_counter m0 : 5|3@1+ (1,0) [0|0] "" Vector__XXX
 SG_ DAS_TE_fcmCounter m7 : 5|3@1+ (1,0) [0|0] "" Vector__XXX
 SG_ DAS_TE_hppCounter m3 : 5|3@1+ (1,0) [0|0] "" Vector__XXX
 SG_ DAS_TE_ipsoCounter m8 : 5|3@1+ (1,0) [0|0] "" Vector__XXX
 SG_ DAS_TE_llCounter m1 : 5|3@1+ (1,0) [0|0] "" Vector__XXX
 SG_ DAS_TE_navCounter m4 : 5|3@1+ (1,0) [0|0] "" Vector__XXX
 SG_ DAS_TE_rlCounter m2 : 5|3@1+ (1,0) [0|0] "" Vector__XXX
 SG_ DAS_TE_robCounter m9 : 5|3@1+ (1,0) [0|0] "" Vector__XXX
 SG_ DAS_TE_vlCounter m5 : 5|3@1+ (1,0) [0|0] "" Vector__XXX
 SG_ DAS_TE_accTargetDx m6 : 8|6@1+ (2,0) [0|0] "" Vector__XXX
 SG_ DAS_TE_eventID m0 : 8|16@1+ (1,0) [0|0] "" Vector__XXX
 SG_ DAS_TE_fcmTargetDx m7 : 8|8@1+ (0.25,0) [0|0] "" Vector__XXX
 SG_ DAS_TE_hppC0 m3 : 8|10@1- (0.02,0) [0|0] "" Vector__XXX
 SG_ DAS_TE_ipsoValid m8 : 8|1@1+ (1,0) [0|0] "" Vector__XXX
 SG_ DAS_TE_llC0 m1 : 8|10@1- (0.02,0) [0|0] "" Vector__XXX
 SG_ DAS_TE_navC0 m4 : 8|10@1- (0.02,0) [0|0] "" Vector__XXX
 SG_ DAS_TE_rlC0 m2 : 8|10@1- (0.02,0) [0|0] "" Vector__XXX
 SG_ DAS_TE_vlC0 m5 : 8|10@1- (0.02,0) [0|0] "" Vector__XXX
 SG_ DAS_TE_ipsoConfidence m8 : 9|7@1+ (1,0) [0|0] "" Vector__XXX
 SG_ DAS_TE_accTargetDy m6 : 14|6@1+ (0.2,-6.4) [0|0] "" Vector__XXX
 SG_ DAS_TE_fcmTargetDy m7 : 16|5@1+ (0.2,-3.2) [0|0] "" Vector__XXX
 SG_ DAS_TE_ipsoDx m8 : 16|6@1+ (2,0) [0|0] "" Vector__XXX
 SG_ DAS_TE_robExceptionStart m9 : 16|8@1+ (1,-95) [0|0] "" Vector__XXX
 SG_ DAS_TE_hppC1 m3 : 18|9@1- (0.001953125,0) [0|0] "" Vector__XXX
 SG_ DAS_TE_llC1 m1 : 18|9@1- (0.001953125,0) [0|0] "" Vector__XXX
 SG_ DAS_TE_navC1 m4 : 18|9@1- (0.001953125,0) [0|0] "" Vector__XXX
 SG_ DAS_TE_rlC1 m2 : 18|9@1- (0.001953125,0) [0|0] "" Vector__XXX
 SG_ DAS_TE_vlC1 m5 : 18|9@1- (0.001953125,0) [0|0] "" Vector__XXX
 SG_ DAS_TE_accTargetRelVel m6 : 20|7@1- (0.25,-15.75) [0|0] "" Vector__XXX
 SG_ DAS_TE_fcmTargetVRel m7 : 21|7@1+ (0.25,-31.75) [0|0] "" Vector__XXX
 SG_ DAS_TE_ipsoDy m8 : 22|6@1+ (0.1,-3.2) [0|0] "" Vector__XXX
 SG_ DAS_TE_eventType m0 : 24|6@1+ (1,0) [0|0] "" Vector__XXX
 SG_ DAS_TE_robExceptionEnd m9 : 24|8@1+ (1,0) [0|0] "" Vector__XXX
 SG_ DAS_TE_accTargetRelA m6 : 27|5@1- (0.5,-7.5) [0|0] "" Vector__XXX
 SG_ DAS_TE_hppC2 m3 : 27|14@1- (4e-06,0) [0|0] "" Vector__XXX
 SG_ DAS_TE_llC2 m1 : 27|14@1- (4e-06,0) [0|0] "" Vector__XXX
 SG_ DAS_TE_navC2 m4 : 27|14@1- (4e-06,0) [0|0] "" Vector__XXX
 SG_ DAS_TE_rlC2 m2 : 27|14@1- (4e-06,0) [0|0] "" Vector__XXX
 SG_ DAS_TE_vlC2 m5 : 27|14@1- (4e-06,0) [0|0] "" Vector__XXX
 SG_ DAS_TE_fcmTargetAccel m7 : 28|5@1+ (0.5,-15.5) [0|0] "" Vector__XXX
 SG_ DAS_TE_vlDyAtIpsoDx m8 : 28|6@1+ (0.1,-3.2) [0|0] "" Vector__XXX
 SG_ DAS_TE_accMinAccel m6 : 32|5@1- (0.5,-7.5) [0|0] "" Vector__XXX
 SG_ DAS_TE_lcAbortReason m0 : 32|5@1+ (1,0) [0|0] "" Vector__XXX
 SG_ DAS_TE_robDistanceEllipse m9 : 32|8@1+ (0.5,0) [0|0] "" Vector__XXX
 SG_ DAS_TE_fcmTargetProb m7 : 33|5@1+ (5,0) [0|0] "" Vector__XXX
 SG_ DAS_TE_swaProjection m8 : 34|6@1+ (0.1,-3.2) [0|0] "" Vector__XXX
 SG_ DAS_TE_accMinJ m6 : 37|5@1- (0.5,-7.5) [0|0] "" Vector__XXX
 SG_ DAS_TE_fcmDecelReqInstant m7 : 38|7@1- (0.1,-6.3) [0|0] "" Vector__XXX
 SG_ DAS_TE_ipsoIsTarget1 m8 : 40|1@1+ (1,0) [0|0] "" Vector__XXX
 SG_ DAS_TE_robEllipseOverlap m9 : 40|8@1+ (0.1,-12.5) [0|0] "" Vector__XXX
 SG_ DAS_TE_hppC3 m3 : 41|14@1- (1.6e-08,0) [0|0] "" Vector__XXX
 SG_ DAS_TE_ipsoIsTarget5 m8 : 41|1@1+ (1,0) [0|0] "" Vector__XXX
 SG_ DAS_TE_llC3 m1 : 41|14@1- (1.6e-08,0) [0|0] "" Vector__XXX
 SG_ DAS_TE_navC3 m4 : 41|14@1- (1.6e-08,0) [0|0] "" Vector__XXX
 SG_ DAS_TE_rlC3 m2 : 41|14@1- (1.6e-08,0) [0|0] "" Vector__XXX
 SG_ DAS_TE_vlC3 m5 : 41|14@1- (1.6e-08,0) [0|0] "" Vector__XXX
 SG_ DAS_TE_restrictedAccess m8 : 42|1@1+ (1,0) [0|0] "" Vector__XXX
 SG_ DAS_TE_csaOfframpValid m8 : 43|1@1+ (1,0) [0|0] "" Vector__XXX
 SG_ DAS_TE_accControlType m8 : 44|4@1+ (1,0) [0|0] "" Vector__XXX
 SG_ DAS_TE_fcmDecelReqAeb m7 : 45|7@1- (0.1,-6.3) [0|0] "" Vector__XXX
 SG_ DAS_TE_brakeCapacityWarning m8 : 48|1@1+ (1,0) [0|0] "" Vector__XXX
 SG_ DAS_TE_robEllipseAge m9 : 48|3@1+ (1,0) [0|0] "" Vector__XXX
 SG_ DAS_TE_emergencyBrake m8 : 49|1@1+ (1,0) [0|0] "" Vector__XXX
 SG_ DAS_TE_extendedAccLimits m8 : 50|1@1+ (1,0) [0|0] "" Vector__XXX
 SG_ DAS_TE_crashFront m8 : 51|1@1+ (1,0) [0|0] "" Vector__XXX
 SG_ DAS_TE_robInfrastructure m9 : 51|1@1+ (1,0) [0|0] "" Vector__XXX
 SG_ DAS_TE_crashLeft m8 : 52|1@1+ (1,0) [0|0] "" Vector__XXX
 SG_ DAS_TE_meAebFlag m7 : 52|1@1+ (1,0) [0|0] "" Vector__XXX
 SG_ DAS_TE_robTrustRadarMap m9 : 52|1@1+ (1,0) [0|0] "" Vector__XXX
 SG_ DAS_TE_crashRear m8 : 53|1@1+ (1,0) [0|0] "" Vector__XXX
 SG_ DAS_TE_robActiveBraking m9 : 53|1@1+ (1,0) [0|0] "" Vector__XXX
 SG_ DAS_TE_crashRight m8 : 54|1@1+ (1,0) [0|0] "" Vector__XXX
 SG_ DAS_TE_crashRollover m8 : 55|1@1+ (1,0) [0|0] "" Vector__XXX
 SG_ DAS_TE_hppQlty m3 : 55|1@1+ (1,0) [0|0] "" Vector__XXX
 SG_ DAS_TE_llQlty m1 : 55|1@1+ (1,0) [0|0] "" Vector__XXX
 SG_ DAS_TE_navQlty m4 : 55|1@1+ (1,0) [0|0] "" Vector__XXX
 SG_ DAS_TE_rlQlty m2 : 55|1@1+ (1,0) [0|0] "" Vector__XXX
 SG_ DAS_TE_vlQlty m5 : 55|1@1+ (1,0) [0|0] "" Vector__XXX
 SG_ DAS_TE_crashPedPro m8 : 56|1@1+ (1,0) [0|0] "" Vector__XXX
 SG_ DAS_TE_hppRange m3 : 56|7@1+ (1,0) [0|0] "" Vector__XXX
 SG_ DAS_TE_llRange m1 : 56|7@1+ (1,0) [0|0] "" Vector__XXX
 SG_ DAS_TE_navRange m4 : 56|7@1+ (1,0) [0|0] "" Vector__XXX
 SG_ DAS_TE_rlRange m2 : 56|7@1+ (1,0) [0|0] "" Vector__XXX
 SG_ DAS_TE_vlRange m5 : 56|7@1+ (1,0) [0|0] "" Vector__XXX
 SG_ DAS_TE_meIpsoValid m8 : 57|1@1+ (1,0) [0|0] "" Vector__XXX
 SG_ DAS_TE_hppFuse m3 : 63|1@1+ (1,0) [0|0] "" Vector__XXX
 SG_ DAS_TE_llFuse m1 : 63|1@1+ (1,0) [0|0] "" Vector__XXX
 SG_ DAS_TE_navFuse m4 : 63|1@1+ (1,0) [0|0] "" Vector__XXX
 SG_ DAS_TE_rlFuse m2 : 63|1@1+ (1,0) [0|0] "" Vector__XXX
 SG_ DAS_TE_vlFuse m5 : 63|1@1+ (1,0) [0|0] "" Vector__XXX

BO_ 987 UI_phoneLocationStatus: 8 Vector__XXX
 SG_ UI_phoneLatitude : 0|28@1- (1e-06,0) [0|0] "" Vector__XXX
 SG_ UI_phoneLongitude : 28|29@1- (1e-06,0) [0|0] "" Vector__XXX
 SG_ UI_phoneGpsAccuracy : 57|7@1+ (0.5,0) [0|0] "" Vector__XXX

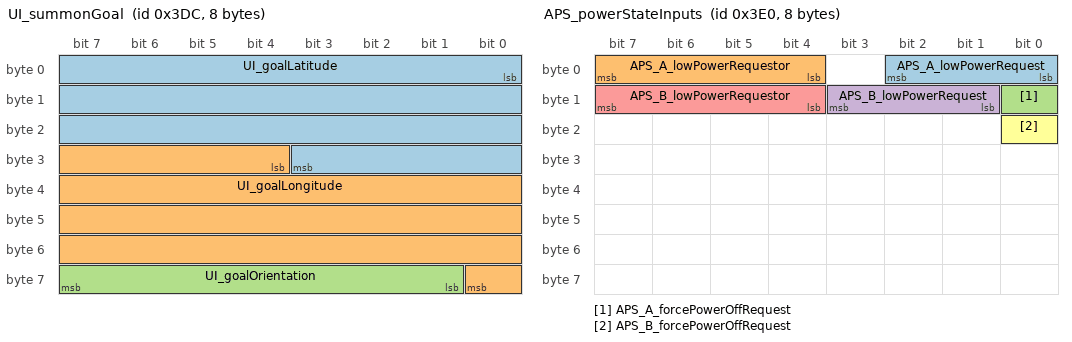
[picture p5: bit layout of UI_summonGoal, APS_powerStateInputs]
BO_ 988 UI_summonGoal: 8 Vector__XXX
 SG_ UI_goalLatitude : 0|28@1- (1e-06,0) [0|0] "" Vector__XXX
 SG_ UI_goalLongitude : 28|29@1- (1e-06,0) [0|0] "" Vector__XXX
 SG_ UI_goalOrientation : 57|7@1+ (2.8125,0) [0|0] "" Vector__XXX

BO_ 991 UI_status2: 8 Vector__XXX
 SG_ UI_mobileAppStepCount : 0|16@1+ (1,0) [0|0] "" Vector__XXX
 SG_ UI_userRequestSnapshot : 16|1@1+ (1,0) [0|0] "" Vector__XXX
 SG_ UI_touchDetected : 17|1@1+ (1,0) [0|0] "" Vector__XXX
 SG_ UI_validDeviceForEUSummon : 18|1@1+ (1,0) [0|0] "" Vector__XXX
 SG_ UI_locatedAtHome : 19|1@1+ (1,0) [0|0] "" Vector__XXX
 SG_ UI_locatedAtWork : 20|1@1+ (1,0) [0|0] "" Vector__XXX
 SG_ UI_locatedAtFavorite : 21|1@1+ (1,0) [0|0] "" Vector__XXX
 SG_ UI_displayInDarkMode : 22|1@1+ (1,0) [0|0] "" Vector__XXX
 SG_ UI_userActivity : 23|1@1+ (1,0) [0|0] "" Vector__XXX
 SG_ UI_activeTouchPoints : 24|8@1+ (1,0) [0|0] "" Vector__XXX
 SG_ UI_linkState : 32|2@1+ (1,0) [0|0] "" Vector__XXX
 SG_ UI_sentryModeState : 34|3@1+ (1,0) [0|0] "" Vector__XXX
 SG_ UI_autopilotSentryRequest : 37|1@1+ (1,0) [0|0] "" Vector__XXX
 SG_ UI_mobileAppConnected : 38|1@1+ (1,0) [0|0] "" Vector__XXX
 SG_ UI_autoshiftDRState : 40|3@1+ (1,0) [0|0] "" Vector__XXX
 SG_ UI_wifiBtModuleType : 43|3@1+ (1,0) [0|0] "" Vector__XXX
 SG_ UI_sohHealthStatus : 46|2@1+ (1,0) [0|0] "" Vector__XXX
 SG_ UI_selfParkState : 48|8@1+ (1,0) [0|0] "" Vector__XXX
 SG_ UI_summonDeviceIndex : 56|2@1+ (1,0) [0|0] "" Vector__XXX
 SG_ UI_sentryModeCameraDetection : 58|1@1+ (1,0) [0|0] "" Vector__XXX
 SG_ UI_wakeOnIPActive : 59|1@1+ (1,0) [0|0] "" Vector__XXX
 SG_ UI_sapActive : 60|1@1+ (1,0) [0|0] "" Vector__XXX
 SG_ UI_sapClients : 61|1@1+ (1,0) [0|0] "" Vector__XXX
 SG_ UI_connectivityStandbyActive : 62|1@1+ (1,0) [0|0] "" Vector__XXX

BO_ 992 APS_powerStateInputs: 8 Vector__XXX
 SG_ APS_A_lowPowerRequest : 0|3@1+ (1,0) [0|0] "" Vector__XXX
 SG_ APS_A_lowPowerRequestor : 4|4@1+ (1,0) [0|0] "" Vector__XXX
 SG_ APS_A_forcePowerOffRequest : 8|1@1+ (1,0) [0|0] "" Vector__XXX
 SG_ APS_B_lowPowerRequest : 9|3@1+ (1,0) [0|0] "" Vector__XXX
 SG_ APS_B_lowPowerRequestor : 12|4@1+ (1,0) [0|0] "" Vector__XXX
 SG_ APS_B_forcePowerOffRequest : 16|1@1+ (1,0) [0|0] "" Vector__XXX

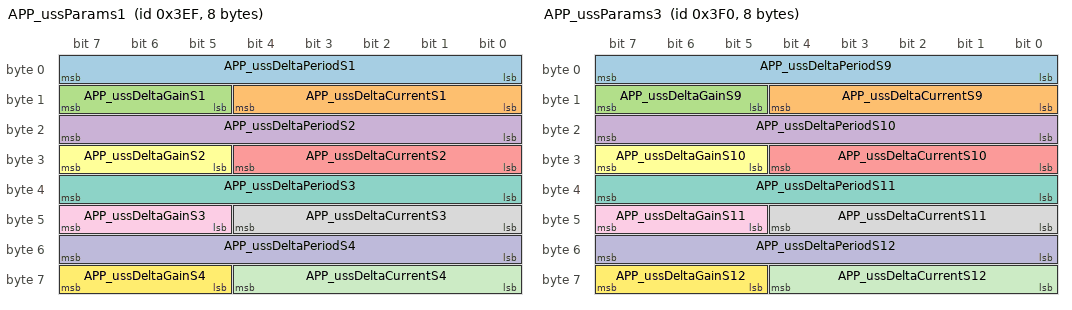
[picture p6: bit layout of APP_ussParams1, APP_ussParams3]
BO_ 1007 APP_ussParams1: 8 Vector__XXX
 SG_ APP_ussDeltaPeriodS1 : 0|8@1- (1,0) [0|0] "" Vector__XXX
 SG_ APP_ussDeltaCurrentS1 : 8|5@1- (1,0) [0|0] "" Vector__XXX
 SG_ APP_ussDeltaGainS1 : 13|3@1- (1,0) [0|0] "" Vector__XXX
 SG_ APP_ussDeltaPeriodS2 : 16|8@1- (1,0) [0|0] "" Vector__XXX
 SG_ APP_ussDeltaCurrentS2 : 24|5@1- (1,0) [0|0] "" Vector__XXX
 SG_ APP_ussDeltaGainS2 : 29|3@1- (1,0) [0|0] "" Vector__XXX
 SG_ APP_ussDeltaPeriodS3 : 32|8@1- (1,0) [0|0] "" Vector__XXX
 SG_ APP_ussDeltaCurrentS3 : 40|5@1- (1,0) [0|0] "" Vector__XXX
 SG_ APP_ussDeltaGainS3 : 45|3@1- (1,0) [0|0] "" Vector__XXX
 SG_ APP_ussDeltaPeriodS4 : 48|8@1- (1,0) [0|0] "" Vector__XXX
 SG_ APP_ussDeltaCurrentS4 : 56|5@1- (1,0) [0|0] "" Vector__XXX
 SG_ APP_ussDeltaGainS4 : 61|3@1- (1,0) [0|0] "" Vector__XXX

BO_ 1008 APP_ussParams3: 8 Vector__XXX
 SG_ APP_ussDeltaPeriodS9 : 0|8@1- (1,0) [0|0] "" Vector__XXX
 SG_ APP_ussDeltaCurrentS9 : 8|5@1- (1,0) [0|0] "" Vector__XXX
 SG_ APP_ussDeltaGainS9 : 13|3@1- (1,0) [0|0] "" Vector__XXX
 SG_ APP_ussDeltaPeriodS10 : 16|8@1- (1,0) [0|0] "" Vector__XXX
 SG_ APP_ussDeltaCurrentS10 : 24|5@1- (1,0) [0|0] "" Vector__XXX
 SG_ APP_ussDeltaGainS10 : 29|3@1- (1,0) [0|0] "" Vector__XXX
 SG_ APP_ussDeltaPeriodS11 : 32|8@1- (1,0) [0|0] "" Vector__XXX
 SG_ APP_ussDeltaCurrentS11 : 40|5@1- (1,0) [0|0] "" Vector__XXX
 SG_ APP_ussDeltaGainS11 : 45|3@1- (1,0) [0|0] "" Vector__XXX
 SG_ APP_ussDeltaPeriodS12 : 48|8@1- (1,0) [0|0] "" Vector__XXX
 SG_ APP_ussDeltaCurrentS12 : 56|5@1- (1,0) [0|0] "" Vector__XXX
 SG_ APP_ussDeltaGainS12 : 61|3@1- (1,0) [0|0] "" Vector__XXX
